VERSION ""

NS_ :

BS_:

BU_: CGM_HS TCM_HS RDCM_HS EPS_HS ECM_HS EBCM_HS BSM_HS BCM_HS

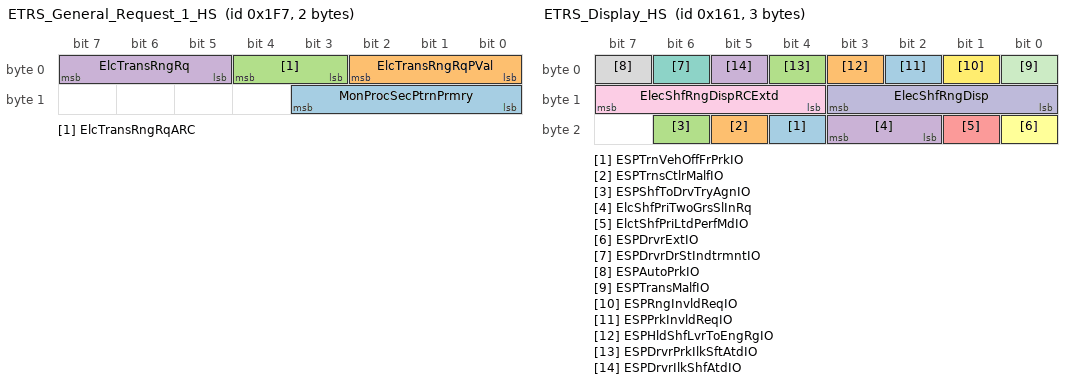
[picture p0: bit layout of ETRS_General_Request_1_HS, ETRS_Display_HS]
BO_ 503 ETRS_General_Request_1_HS: 2 ECM_HS
 SG_ MonProcSecPtrnPrmry : 11|4@0+ (1,0) [0|15] ""  CGM_HS,TCM_HS
 SG_ ElcTransRngRqPVal : 2|3@0+ (1,0) [0|7] ""  CGM_HS,TCM_HS,RDCM_HS
 SG_ ElcTransRngRqARC : 4|2@0+ (1,0) [0|3] ""  CGM_HS,TCM_HS,RDCM_HS
 SG_ ElcTransRngRq : 7|3@0+ (1,0) [0|7] ""  CGM_HS,TCM_HS,RDCM_HS,BCM_HS

BO_ 353 ETRS_Display_HS: 3 ECM_HS
 SG_ ESPTrnVehOffFrPrkIO : 20|1@0+ (1,0) [0|1] ""  CGM_HS,BCM_HS
 SG_ ESPTrnsCtlrMalfIO : 21|1@0+ (1,0) [0|1] ""  CGM_HS,BCM_HS
 SG_ ESPShfToDrvTryAgnIO : 22|1@0+ (1,0) [0|1] ""  CGM_HS,BCM_HS
 SG_ ElcShfPriTwoGrsSlInRq : 19|2@0+ (1,0) [0|3] ""  CGM_HS,BCM_HS
 SG_ ElctShfPriLtdPerfMdIO : 17|1@0+ (1,0) [0|1] ""  CGM_HS,BCM_HS
 SG_ ESPDrvrExtIO : 16|1@0+ (1,0) [0|1] ""  CGM_HS,BCM_HS
 SG_ ESPDrvrDrStIndtrmntIO : 6|1@0+ (1,0) [0|1] ""  CGM_HS,BCM_HS
 SG_ ESPAutoPrkIO : 7|1@0+ (1,0) [0|1] ""  CGM_HS,BCM_HS
 SG_ ElecShfRngDispRCExtd : 15|4@0+ (1,0) [0|15] ""  CGM_HS,BCM_HS
 SG_ ElecShfRngDisp : 11|4@0+ (1,0) [0|15] ""  CGM_HS,BCM_HS
 SG_ ESPTransMalfIO : 0|1@0+ (1,0) [0|1] ""  CGM_HS,BCM_HS
 SG_ ESPRngInvldReqIO : 1|1@0+ (1,0) [0|1] ""  CGM_HS,BCM_HS
 SG_ ESPPrkInvldReqIO : 2|1@0+ (1,0) [0|1] ""  CGM_HS,BCM_HS
 SG_ ESPHldShfLvrToEngRgIO : 3|1@0+ (1,0) [0|1] ""  CGM_HS,BCM_HS
 SG_ ESPDrvrPrkIlkSftAtdIO : 4|1@0+ (1,0) [0|1] ""  CGM_HS,BCM_HS
 SG_ ESPDrvrIlkShfAtdIO : 5|1@0+ (1,0) [0|1] ""  CGM_HS,BCM_HS

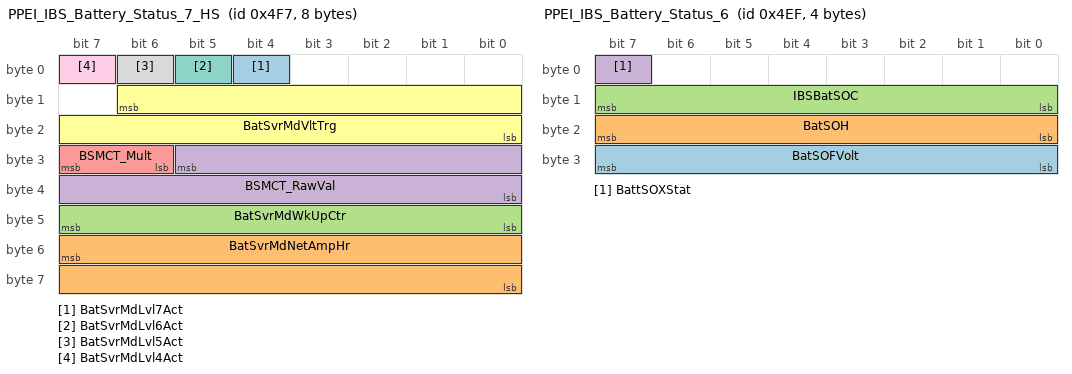
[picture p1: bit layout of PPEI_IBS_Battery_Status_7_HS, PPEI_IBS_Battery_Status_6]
BO_ 1271 PPEI_IBS_Battery_Status_7_HS: 8 ECM_HS
 SG_ BatSvrMdLvl7Act : 4|1@0+ (1,0) [0|1] ""  CGM_HS,BCM_HS
 SG_ BatSvrMdNetAmpHr : 55|16@0+ (0.01,-327.67) [-327.67|327.68] "AmpHours"  CGM_HS,BCM_HS
 SG_ BatSvrMdWkUpCtr : 47|8@0+ (1,0) [0|255] ""  CGM_HS,BCM_HS
 SG_ BSMCT_RawVal : 29|14@0+ (0.001,-8.192) [-8.192|8.191] "A"  CGM_HS,BCM_HS
 SG_ BSMCT_Mult : 31|2@0+ (1,0) [0|3] ""  CGM_HS,BCM_HS
 SG_ BatSvrMdVltTrg : 14|15@0+ (0.001,0) [0|32.767] "V"  CGM_HS,BCM_HS
 SG_ BatSvrMdLvl6Act : 5|1@0+ (1,0) [0|1] ""  CGM_HS,BCM_HS
 SG_ BatSvrMdLvl5Act : 6|1@0+ (1,0) [0|1] ""  CGM_HS,BCM_HS
 SG_ BatSvrMdLvl4Act : 7|1@0+ (1,0) [0|1] ""  CGM_HS,BCM_HS

BO_ 1263 PPEI_IBS_Battery_Status_6: 4 ECM_HS
 SG_ BatSOFVolt : 31|8@0+ (0.05,0) [0|12.75] "volts"  CGM_HS,BCM_HS
 SG_ BatSOH : 23|8@0+ (0.392157,0) [0|100.000035] "%"  CGM_HS,BCM_HS
 SG_ IBSBatSOC : 15|8@0+ (0.392157,0) [0|100.000035] "%"  CGM_HS,BCM_HS
 SG_ BattSOXStat : 7|1@0+ (1,0) [0|1] ""  CGM_HS,BCM_HS

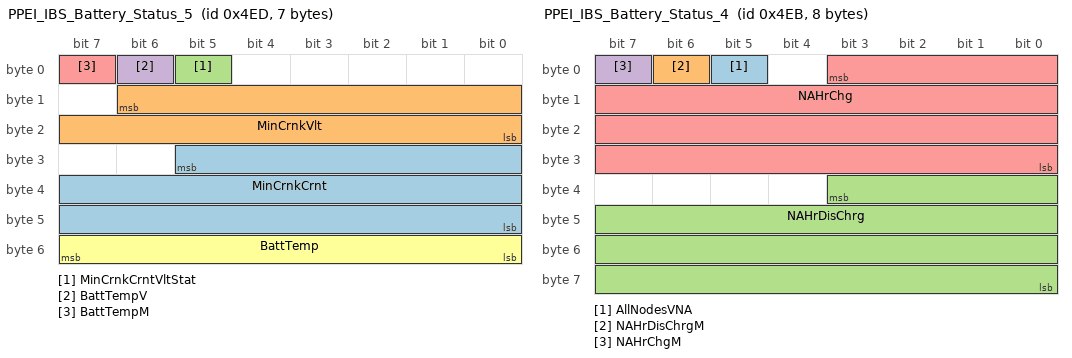
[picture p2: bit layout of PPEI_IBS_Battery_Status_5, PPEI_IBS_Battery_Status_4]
BO_ 1261 PPEI_IBS_Battery_Status_5: 7 ECM_HS
 SG_ MinCrnkCrnt : 29|22@0+ (0.001,-2097.152) [-2097.152|2097.151] "amps"  CGM_HS,BCM_HS
 SG_ MinCrnkVlt : 14|15@0+ (0.001,0) [0|32.767] "volts"  CGM_HS,BCM_HS
 SG_ MinCrnkCrntVltStat : 5|1@0+ (1,0) [0|1] ""  CGM_HS,BCM_HS
 SG_ BattTempV : 6|1@0+ (1,0) [0|1] ""  CGM_HS,BCM_HS
 SG_ BattTempM : 7|1@0+ (1,0) [0|1] ""  CGM_HS,BCM_HS
 SG_ BattTemp : 55|8@0+ (1,-40) [-40|215] "deg C"  CGM_HS,BCM_HS

BO_ 1259 PPEI_IBS_Battery_Status_4: 8 ECM_HS
 SG_ AllNodesVNA : 5|1@0+ (1,0) [0|1] ""  CGM_HS,BCM_HS
 SG_ NAHrDisChrgM : 6|1@0+ (1,0) [0|1] ""  CGM_HS,BCM_HS
 SG_ NAHrDisChrg : 35|28@0+ (0.001,0) [0|268435.455] "AmpHours"  CGM_HS,BCM_HS
 SG_ NAHrChgM : 7|1@0+ (1,0) [0|1] ""  CGM_HS,BCM_HS
 SG_ NAHrChg : 3|28@0+ (0.001,0) [0|268435.455] "AmpHours"  CGM_HS,BCM_HS

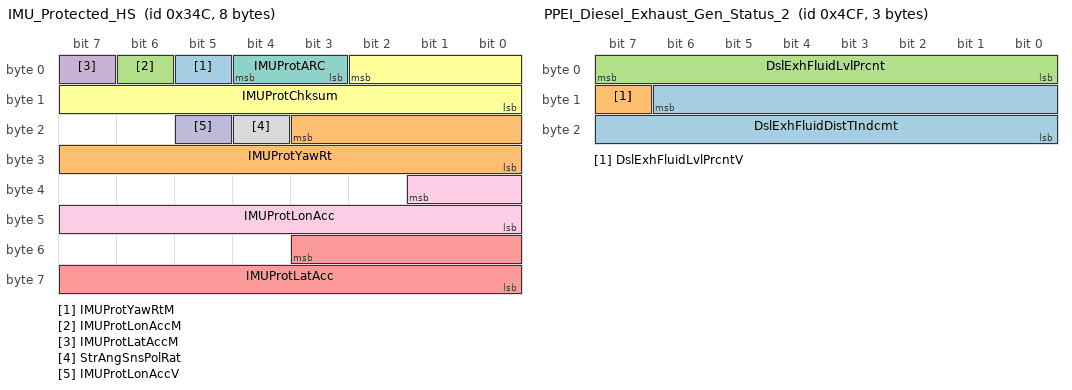
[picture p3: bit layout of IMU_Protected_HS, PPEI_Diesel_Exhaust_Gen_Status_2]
BO_ 844 IMU_Protected_HS: 8 EBCM_HS
 SG_ IMUProtYawRtM : 5|1@0+ (1,0) [0|1] ""  CGM_HS,EPS_HS
 SG_ IMUProtYawRt : 19|12@0- (0.0625,0) [-128|127.9375] "deg/sec"  CGM_HS,EPS_HS
 SG_ IMUProtLonAccM : 6|1@0+ (1,0) [0|1] ""  CGM_HS,EPS_HS
 SG_ IMUProtLatAccM : 7|1@0+ (1,0) [0|1] ""  CGM_HS,EPS_HS
 SG_ IMUProtLatAcc : 51|12@0- (0.015625,0) [-32|31.984375] "m/s^2"  CGM_HS,EPS_HS
 SG_ IMUProtChksum : 2|11@0+ (1,0) [0|2047] ""  CGM_HS,EPS_HS
 SG_ IMUProtARC : 4|2@0+ (1,0) [0|3] ""  CGM_HS,EPS_HS
 SG_ StrAngSnsPolRat : 20|1@0+ (1,0) [0|1] ""  CGM_HS,EPS_HS
 SG_ IMUProtLonAcc : 33|10@0- (0.03,0) [-15.36|15.33] "m/s^2"  CGM_HS,EPS_HS,RDCM_HS,ECM_HS,BCM_HS
 SG_ IMUProtLonAccV : 21|1@0+ (1,0) [0|1] ""  CGM_HS,EPS_HS,RDCM_HS,ECM_HS,BCM_HS

BO_ 806 DC_Converter_Stabilization_HS: 1 ECM_HS
 SG_ DCCnvStblznErrIO : 0|1@0+ (1,0) [0|1] ""  CGM_HS,ECM_HS,BCM_HS

BO_ 1231 PPEI_Diesel_Exhaust_Gen_Status_2: 3 ECM_HS
 SG_ DslExhFluidDistTIndcmt : 14|15@0+ (2,0) [0|65534] "km"  CGM_HS,BCM_HS
 SG_ DslExhFluidLvlPrcntV : 15|1@0+ (1,0) [0|1] ""  CGM_HS,BCM_HS
 SG_ DslExhFluidLvlPrcnt : 7|8@0+ (0.392157,0) [0|100.000035] "%"  CGM_HS,BCM_HS

BO_ 2032 CCP_Command_Receive_Object_HS: 8 CGM_HS
 SG_ DgnInf : 7|64@0+ (1,0) [0|1.84467440737096E+019] ""  BCM_HS

BO_ 563 Performance_Mode_Cust_Setings_HS: 5 EBCM_HS
 SG_ SPMCA_SusPrfMd6Avl : 32|1@0+ (1,0) [0|1] ""  CGM_HS,BCM_HS
 SG_ SPMCA_SusPrfMd5Avl : 33|1@0+ (1,0) [0|1] ""  CGM_HS,BCM_HS
 SG_ SPMCA_SusPrfMd4Avl : 34|1@0+ (1,0) [0|1] ""  CGM_HS,BCM_HS
 SG_ SPMCA_SusPrfMd3Avl : 35|1@0+ (1,0) [0|1] ""  CGM_HS,BCM_HS
 SG_ SPMCA_SusPrfMd2Avl : 36|1@0+ (1,0) [0|1] ""  CGM_HS,BCM_HS
 SG_ SPMCA_SusPrfMd1Avl : 37|1@0+ (1,0) [0|1] ""  CGM_HS,BCM_HS
 SG_ SPMCA_StrPrfMd6Avl : 24|1@0+ (1,0) [0|1] ""  CGM_HS,BCM_HS
 SG_ SPMCA_StrPrfMd5Avl : 25|1@0+ (1,0) [0|1] ""  CGM_HS,BCM_HS
 SG_ SPMCA_StrPrfMd4Avl : 26|1@0+ (1,0) [0|1] ""  CGM_HS,BCM_HS
 SG_ SPMCA_StrPrfMd3Avl : 27|1@0+ (1,0) [0|1] ""  CGM_HS,BCM_HS
 SG_ SPMCA_StrPrfMd2Avl : 28|1@0+ (1,0) [0|1] ""  CGM_HS,BCM_HS
 SG_ SPMCA_StrPrfMd1Avl : 29|1@0+ (1,0) [0|1] ""  CGM_HS,BCM_HS
 SG_ SPMCA_SndPrfMd6Avl : 16|1@0+ (1,0) [0|1] ""  CGM_HS,BCM_HS
 SG_ SPMCA_SndPrfMd5Avl : 17|1@0+ (1,0) [0|1] ""  CGM_HS,BCM_HS
 SG_ SPMCA_SndPrfMd4Avl : 18|1@0+ (1,0) [0|1] ""  CGM_HS,BCM_HS
 SG_ SPMCA_SndPrfMd3Avl : 19|1@0+ (1,0) [0|1] ""  CGM_HS,BCM_HS
 SG_ SPMCA_SndPrfMd2Avl : 20|1@0+ (1,0) [0|1] ""  CGM_HS,BCM_HS
 SG_ SPMCA_SndPrfMd1Avl : 21|1@0+ (1,0) [0|1] ""  CGM_HS,BCM_HS
 SG_ DPMCA_DispPrfMd6Avl : 8|1@0+ (1,0) [0|1] ""  CGM_HS,BCM_HS
 SG_ DPMCA_DispPrfMd5Avl : 9|1@0+ (1,0) [0|1] ""  CGM_HS,BCM_HS
 SG_ DPMCA_DispPrfMd4Avl : 10|1@0+ (1,0) [0|1] ""  CGM_HS,BCM_HS
 SG_ DPMCA_DispPrfMd3Avl : 11|1@0+ (1,0) [0|1] ""  CGM_HS,BCM_HS
 SG_ DPMCA_DispPrfMd2Avl : 12|1@0+ (1,0) [0|1] ""  CGM_HS,BCM_HS
 SG_ DPMCA_DispPrfMd1Avl : 13|1@0+ (1,0) [0|1] ""  CGM_HS,BCM_HS
 SG_ DPMCA_DrvlPrfMd6Avl : 0|1@0+ (1,0) [0|1] ""  CGM_HS,BCM_HS
 SG_ DPMCA_DrvlPrfMd5Avl : 1|1@0+ (1,0) [0|1] ""  CGM_HS,BCM_HS
 SG_ DPMCA_DrvlPrfMd4Avl : 2|1@0+ (1,0) [0|1] ""  CGM_HS,BCM_HS
 SG_ DPMCA_DrvlPrfMd3Avl : 3|1@0+ (1,0) [0|1] ""  CGM_HS,BCM_HS
 SG_ DPMCA_DrvlPrfMd2Avl : 4|1@0+ (1,0) [0|1] ""  CGM_HS,BCM_HS
 SG_ DPMCA_DrvlPrfMd1Avl : 5|1@0+ (1,0) [0|1] ""  CGM_HS,BCM_HS

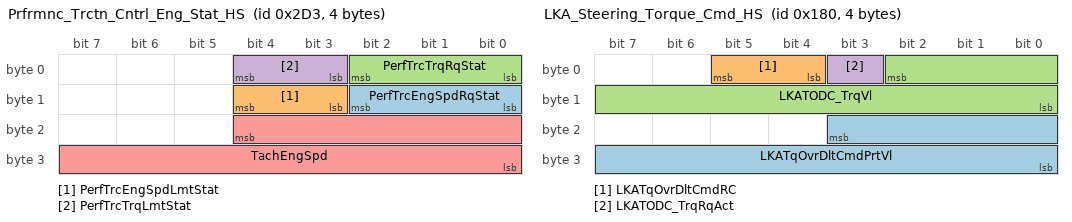
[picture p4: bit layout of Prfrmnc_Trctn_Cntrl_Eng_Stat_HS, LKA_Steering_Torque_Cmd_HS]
BO_ 723 Prfrmnc_Trctn_Cntrl_Eng_Stat_HS: 4 ECM_HS
 SG_ PerfTrcEngSpdRqStat : 10|3@0+ (1,0) [0|7] ""  CGM_HS,EBCM_HS
 SG_ PerfTrcEngSpdLmtStat : 12|2@0+ (1,0) [0|3] ""  CGM_HS,EBCM_HS
 SG_ PerfTrcTrqRqStat : 2|3@0+ (1,0) [0|7] ""  CGM_HS,EBCM_HS
 SG_ PerfTrcTrqLmtStat : 4|2@0+ (1,0) [0|3] ""  CGM_HS,EBCM_HS
 SG_ TachEngSpd : 20|13@0+ (1,0) [0|8191] "rpm"  CGM_HS,BCM_HS

BO_ 419 PTEI_Engine_Common_Use_1: 1 ECM_HS
 SG_ ClrCGMLgsDgInf : 6|1@0+ (1,0) [0|1] ""  CGM_HS
 SG_ EngRunng : 7|1@0+ (1,0) [0|1] ""  CGM_HS,TCM_HS,EBCM_HS,BCM_HS

BO_ 1268 PPEI_Engine_General_Status_9: 2 ECM_HS
 SG_ EngAirFltLfRmn : 14|7@0+ (1,0) [0|127] "%"  CGM_HS,BCM_HS
 SG_ EngAirFltMonSt : 2|3@0+ (1,0) [0|7] ""  CGM_HS,BCM_HS

BO_ 384 LKA_Steering_Torque_Cmd_HS: 4 CGM_HS
 SG_ LKATqOvrDltCmdPrtVl : 19|12@0+ (1,0) [0|4095] ""  EPS_HS
 SG_ LKATqOvrDltCmdRC : 5|2@0+ (1,0) [0|3] ""  EPS_HS
 SG_ LKATODC_TrqVl : 2|11@0- (0.01,0) [-10.24|10.23] "Nm"  EPS_HS,BCM_HS
 SG_ LKATODC_TrqRqAct : 3|1@0+ (1,0) [0|1] ""  EPS_HS,BCM_HS

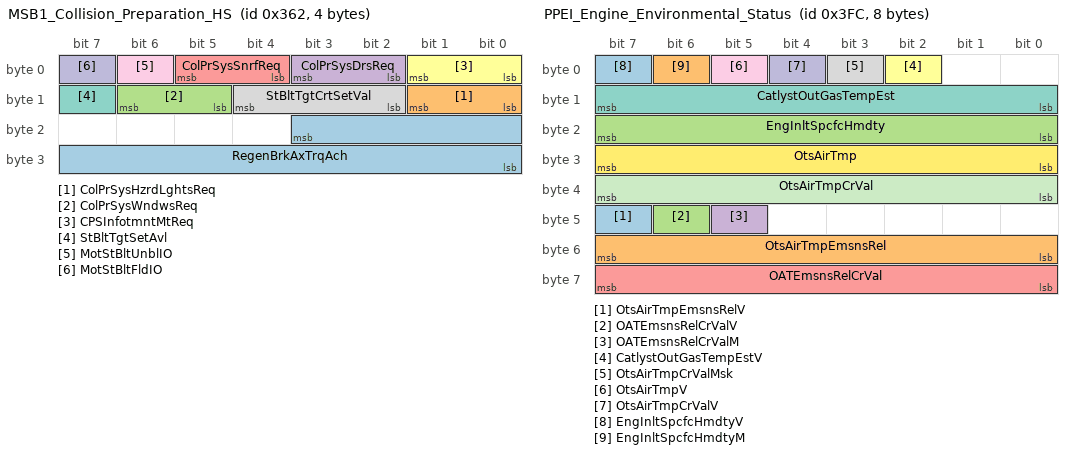
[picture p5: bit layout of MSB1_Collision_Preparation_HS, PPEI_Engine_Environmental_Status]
BO_ 866 MSB1_Collision_Preparation_HS: 4 EBCM_HS
 SG_ RegenBrkAxTrqAch : 19|12@0+ (2,0) [0|8190] "Nm"  CGM_HS,BSM_HS
 SG_ ColPrSysHzrdLghtsReq : 9|2@0+ (1,0) [0|3] ""  CGM_HS,BCM_HS
 SG_ ColPrSysWndwsReq : 14|2@0+ (1,0) [0|3] ""  CGM_HS,BCM_HS
 SG_ ColPrSysDrsReq : 3|2@0+ (1,0) [0|3] ""  CGM_HS,BCM_HS
 SG_ ColPrSysSnrfReq : 5|2@0+ (1,0) [0|3] ""  CGM_HS,BCM_HS
 SG_ CPSInfotmntMtReq : 1|2@0+ (1,0) [0|3] ""  CGM_HS,BCM_HS
 SG_ StBltTgtSetAvl : 15|1@0+ (1,0) [0|1] ""  CGM_HS,BCM_HS
 SG_ StBltTgtCrtSetVal : 12|3@0+ (1,0) [0|7] ""  CGM_HS,BCM_HS
 SG_ MotStBltUnblIO : 6|1@0+ (1,0) [0|1] ""  CGM_HS,BCM_HS
 SG_ MotStBltFldIO : 7|1@0+ (1,0) [0|1] ""  CGM_HS,BCM_HS

BO_ 479 PPEI_Propulsion_Gen_Stat_1_HS: 3 ECM_HS
 SG_ PTAVHEnbld : 4|1@0+ (1,0) [0|1] ""  CGM_HS,EBCM_HS
 SG_ PTAVHActv : 3|1@0+ (1,0) [0|1] ""  CGM_HS,EBCM_HS
 SG_ PrplsnSysAtv : 7|1@0+ (1,0) [0|1] ""  CGM_HS,TCM_HS,RDCM_HS,ECM_HS,EBCM_HS,BSM_HS
 SG_ EngAutoStpNotProb : 2|1@0+ (1,0) [0|1] ""  CGM_HS,TCM_HS,ECM_HS,BCM_HS
 SG_ EASSI_UnsdRsrvd2 : 8|1@0+ (1,0) [0|1] ""  CGM_HS,TCM_HS,EBCM_HS,ECM_HS,BCM_HS
 SG_ EASSI_StlDetd : 10|1@0+ (1,0) [0|1] ""  CGM_HS,TCM_HS,EBCM_HS,ECM_HS,BCM_HS
 SG_ EASSI_TrqDetd : 11|1@0+ (1,0) [0|1] ""  CGM_HS,TCM_HS,EBCM_HS,ECM_HS,BCM_HS
 SG_ EASSI_FuelReqOn : 12|1@0+ (1,0) [0|1] ""  CGM_HS,TCM_HS,EBCM_HS,ECM_HS,BCM_HS
 SG_ EASSI_StrtTyp : 15|3@0+ (1,0) [0|7] ""  CGM_HS,TCM_HS,EBCM_HS,ECM_HS,BCM_HS
 SG_ EASSI_StrtStpSt : 1|2@0+ (1,0) [0|3] ""  CGM_HS,TCM_HS,ECM_HS,EBCM_HS,BCM_HS
 SG_ EASSI_TorqDetdIndet : 9|1@0+ (1,0) [0|1] ""  CGM_HS,TCM_HS,ECM_HS,EBCM_HS,BCM_HS
 SG_ ASIRI_Indication08 : 16|1@0+ (1,0) [0|1] ""  CGM_HS,BCM_HS
 SG_ ASIRI_Indication07 : 17|1@0+ (1,0) [0|1] ""  CGM_HS,BCM_HS
 SG_ ASIRI_Indication06 : 18|1@0+ (1,0) [0|1] ""  CGM_HS,BCM_HS
 SG_ ASIRI_Indication05 : 19|1@0+ (1,0) [0|1] ""  CGM_HS,BCM_HS
 SG_ ASIRI_Indication04 : 20|1@0+ (1,0) [0|1] ""  CGM_HS,BCM_HS
 SG_ ASIRI_Indication03 : 21|1@0+ (1,0) [0|1] ""  CGM_HS,BCM_HS
 SG_ ASIRI_Indication02 : 22|1@0+ (1,0) [0|1] ""  CGM_HS,BCM_HS
 SG_ ASIRI_Indication01 : 23|1@0+ (1,0) [0|1] ""  CGM_HS,BCM_HS
 SG_ PTWrmgWtToShftIO : 5|1@0+ (1,0) [0|1] ""  CGM_HS,BCM_HS
 SG_ PTShftLvrLckRqd : 6|1@0+ (1,0) [0|1] ""  CGM_HS,BCM_HS

BO_ 1020 PPEI_Engine_Environmental_Status: 8 ECM_HS
 SG_ OtsAirTmpEmsnsRelV : 47|1@0+ (1,0) [0|1] ""  CGM_HS,BSM_HS
 SG_ OtsAirTmpEmsnsRel : 55|8@0+ (0.5,-40) [-40|87.5] "deg C"  CGM_HS,BSM_HS
 SG_ OATEmsnsRelCrValV : 46|1@0+ (1,0) [0|1] ""  CGM_HS,BSM_HS
 SG_ OATEmsnsRelCrValM : 45|1@0+ (1,0) [0|1] ""  CGM_HS,BSM_HS
 SG_ OATEmsnsRelCrVal : 63|8@0+ (0.5,-40) [-40|87.5] "deg C"  CGM_HS,BSM_HS
 SG_ CatlystOutGasTempEstV : 2|1@0+ (1,0) [0|1] ""  CGM_HS,BSM_HS
 SG_ CatlystOutGasTempEst : 15|8@0+ (5,-40) [-40|1235] "deg C"  CGM_HS,BSM_HS
 SG_ OtsAirTmpCrValMsk : 3|1@0+ (1,0) [0|1] ""  TCM_HS,BSM_HS,BCM_HS
 SG_ OtsAirTmpV : 5|1@0+ (1,0) [0|1] ""  CGM_HS,BSM_HS,BCM_HS
 SG_ OtsAirTmpCrValV : 4|1@0+ (1,0) [0|1] ""  TCM_HS,BSM_HS,BCM_HS
 SG_ OtsAirTmpCrVal : 39|8@0+ (0.5,-40) [-40|87.5] "deg C"  TCM_HS,BSM_HS,BCM_HS
 SG_ OtsAirTmp : 31|8@0+ (0.5,-40) [-40|87.5] "deg C"  CGM_HS,BSM_HS,BCM_HS
 SG_ EngInltSpcfcHmdtyV : 7|1@0+ (1,0) [0|1] ""  CGM_HS,EBCM_HS,BSM_HS,BCM_HS
 SG_ EngInltSpcfcHmdtyM : 6|1@0+ (1,0) [0|1] ""  CGM_HS,EBCM_HS,BSM_HS,BCM_HS
 SG_ EngInltSpcfcHmdty : 23|8@0+ (0.0196078,0) [0|4.999989] "% water"  CGM_HS,EBCM_HS,BSM_HS,BCM_HS

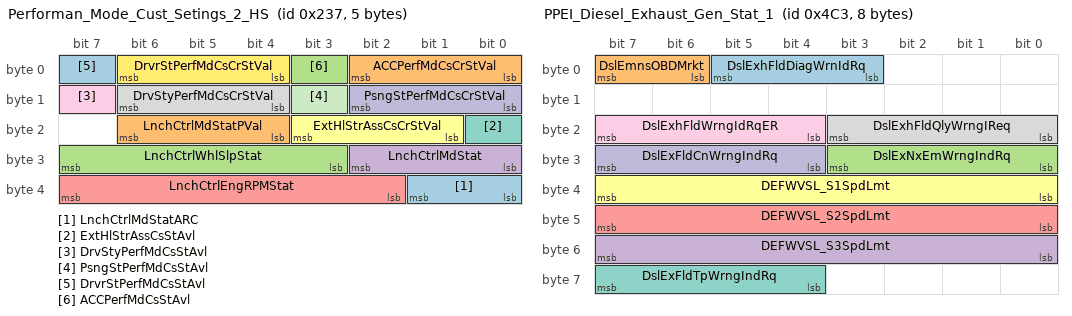
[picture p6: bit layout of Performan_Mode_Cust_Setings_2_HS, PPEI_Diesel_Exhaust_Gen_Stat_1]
BO_ 567 Performan_Mode_Cust_Setings_2_HS: 5 EBCM_HS
 SG_ LnchCtrlMdStatARC : 33|2@0+ (1,0) [0|3] ""  CGM_HS,ECM_HS
 SG_ LnchCtrlMdStatPVal : 22|3@0+ (1,0) [0|7] ""  CGM_HS,ECM_HS
 SG_ LnchCtrlWhlSlpStat : 31|5@0+ (1,0) [0|31] ""  CGM_HS,BCM_HS
 SG_ LnchCtrlMdStat : 26|3@0+ (1,0) [0|7] ""  CGM_HS,ECM_HS,BCM_HS
 SG_ LnchCtrlEngRPMStat : 39|6@0+ (1,0) [0|63] ""  CGM_HS,BCM_HS
 SG_ ExtHlStrAssCsCrStVal : 19|3@0+ (1,0) [0|7] ""  CGM_HS,BCM_HS
 SG_ ExtHlStrAssCsStAvl : 16|1@0+ (1,0) [0|1] ""  CGM_HS,BCM_HS
 SG_ DrvStyPerfMdCsCrStVal : 14|3@0+ (1,0) [0|7] ""  CGM_HS,BCM_HS
 SG_ DrvStyPerfMdCsStAvl : 15|1@0+ (1,0) [0|1] ""  CGM_HS,BCM_HS
 SG_ PsngStPerfMdCsCrStVal : 10|3@0+ (1,0) [0|7] ""  CGM_HS,BCM_HS
 SG_ PsngStPerfMdCsStAvl : 11|1@0+ (1,0) [0|1] ""  CGM_HS,BCM_HS
 SG_ DrvrStPerfMdCsCrStVal : 6|3@0+ (1,0) [0|7] ""  CGM_HS,BCM_HS
 SG_ DrvrStPerfMdCsStAvl : 7|1@0+ (1,0) [0|1] ""  CGM_HS,BCM_HS
 SG_ ACCPerfMdCsCrStVal : 2|3@0+ (1,0) [0|7] ""  CGM_HS,BCM_HS
 SG_ ACCPerfMdCsStAvl : 3|1@0+ (1,0) [0|1] ""  CGM_HS,BCM_HS

BO_ 1219 PPEI_Diesel_Exhaust_Gen_Stat_1: 8 ECM_HS
 SG_ DslExhFldDiagWrnIdRq : 5|3@0+ (1,0) [0|7] ""  CGM_HS,BCM_HS
 SG_ DslEmnsOBDMrkt : 7|2@0+ (1,0) [0|3] ""  CGM_HS,BCM_HS
 SG_ DslExNxEmWrngIndRq : 27|4@0+ (1,0) [0|15] ""  CGM_HS,BCM_HS
 SG_ DEFWVSL_S3SpdLmt : 55|8@0+ (1,0) [0|255] "km / h"  CGM_HS,BCM_HS
 SG_ DEFWVSL_S2SpdLmt : 47|8@0+ (1,0) [0|255] "km / h"  CGM_HS,BCM_HS
 SG_ DEFWVSL_S1SpdLmt : 39|8@0+ (1,0) [0|255] "km / h"  CGM_HS,BCM_HS
 SG_ DslExFldTpWrngIndRq : 63|4@0+ (1,0) [0|15] ""  CGM_HS,BCM_HS
 SG_ DslExhFldQlyWrngIReq : 19|4@0+ (1,0) [0|15] ""  CGM_HS,BCM_HS
 SG_ DslExhFldWrngIdRqER : 23|4@0+ (1,0) [0|15] ""  CGM_HS,BCM_HS
 SG_ DslExFldCnWrngIndRq : 31|4@0+ (1,0) [0|15] ""  CGM_HS,BCM_HS

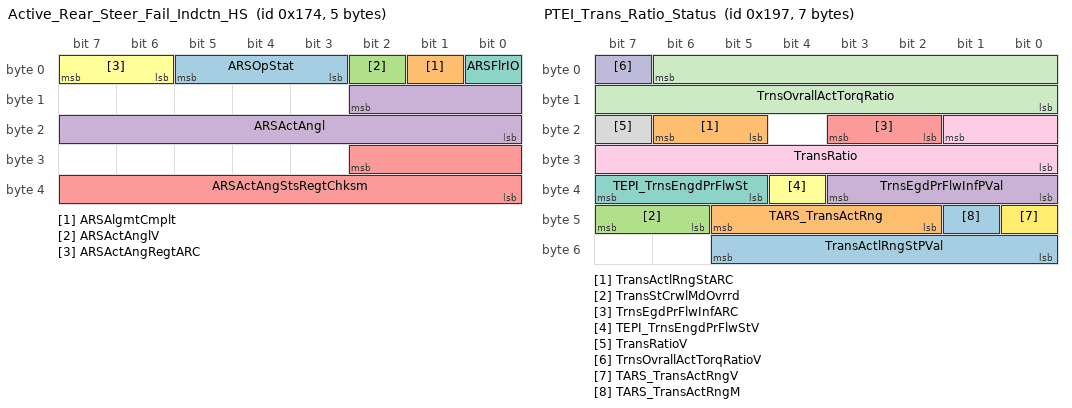
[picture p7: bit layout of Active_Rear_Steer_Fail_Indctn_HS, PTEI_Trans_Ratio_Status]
BO_ 372 Active_Rear_Steer_Fail_Indctn_HS: 5 EBCM_HS
 SG_ ARSOpStat : 5|3@0+ (1,0) [0|7] ""  CGM_HS
 SG_ ARSAlgmtCmplt : 1|1@0+ (1,0) [0|1] ""  CGM_HS
 SG_ ARSActAnglV : 2|1@0+ (1,0) [0|1] ""  CGM_HS
 SG_ ARSActAngl : 10|11@0- (0.01,0) [-10.24|10.23] "deg"  CGM_HS
 SG_ ARSActAngStsRegtChksm : 26|11@0+ (1,0) [0|2047] ""  CGM_HS
 SG_ ARSActAngRegtARC : 7|2@0+ (1,0) [0|3] ""  CGM_HS
 SG_ ARSFlrIO : 0|1@0+ (1,0) [0|1] ""  CGM_HS,BCM_HS

BO_ 565 Performan_Mode_Cust_Setings_1_HS: 5 EBCM_HS
 SG_ PerfMdMainMenuType : 2|3@0+ (1,0) [0|7] ""  CGM_HS,BCM_HS
 SG_ PSPMCA_PsngStPrfMd6Avl : 24|1@0+ (1,0) [0|1] ""  CGM_HS,BCM_HS
 SG_ PSPMCA_PsngStPrfMd5Avl : 25|1@0+ (1,0) [0|1] ""  CGM_HS,BCM_HS
 SG_ PSPMCA_PsngStPrfMd4Avl : 26|1@0+ (1,0) [0|1] ""  CGM_HS,BCM_HS
 SG_ PSPMCA_PsngStPrfMd3Avl : 27|1@0+ (1,0) [0|1] ""  CGM_HS,BCM_HS
 SG_ PSPMCA_PsngStPrfMd2Avl : 28|1@0+ (1,0) [0|1] ""  CGM_HS,BCM_HS
 SG_ PSPMCA_PsngStPrfMd1Avl : 29|1@0+ (1,0) [0|1] ""  CGM_HS,BCM_HS
 SG_ DSPMCA_DrvStyPrfMd7Avl : 32|1@0+ (1,0) [0|1] ""  CGM_HS,BCM_HS
 SG_ DSPMCA_DrvStyPrfMd6Avl : 33|1@0+ (1,0) [0|1] ""  CGM_HS,BCM_HS
 SG_ DSPMCA_DrvStyPrfMd5Avl : 34|1@0+ (1,0) [0|1] ""  CGM_HS,BCM_HS
 SG_ DSPMCA_DrvStyPrfMd4Avl : 35|1@0+ (1,0) [0|1] ""  CGM_HS,BCM_HS
 SG_ DSPMCA_DrvStyPrfMd3Avl : 36|1@0+ (1,0) [0|1] ""  CGM_HS,BCM_HS
 SG_ DSPMCA_DrvStyPrfMd2Avl : 37|1@0+ (1,0) [0|1] ""  CGM_HS,BCM_HS
 SG_ DSPMCA_DrvStyPrfMd1Avl : 38|1@0+ (1,0) [0|1] ""  CGM_HS,BCM_HS
 SG_ DSPMCA_DrvrStPrfMd6Avl : 16|1@0+ (1,0) [0|1] ""  CGM_HS,BCM_HS
 SG_ DSPMCA_DrvrStPrfMd5Avl : 17|1@0+ (1,0) [0|1] ""  CGM_HS,BCM_HS
 SG_ DSPMCA_DrvrStPrfMd4Avl : 18|1@0+ (1,0) [0|1] ""  CGM_HS,BCM_HS
 SG_ DSPMCA_DrvrStPrfMd3Avl : 19|1@0+ (1,0) [0|1] ""  CGM_HS,BCM_HS
 SG_ DSPMCA_DrvrStPrfMd2Avl : 20|1@0+ (1,0) [0|1] ""  CGM_HS,BCM_HS
 SG_ DSPMCA_DrvrStPrfMd1Avl : 21|1@0+ (1,0) [0|1] ""  CGM_HS,BCM_HS
 SG_ ACCPMCA_ACCPrfMd6Avl : 8|1@0+ (1,0) [0|1] ""  CGM_HS,BCM_HS
 SG_ ACCPMCA_ACCPrfMd5Avl : 9|1@0+ (1,0) [0|1] ""  CGM_HS,BCM_HS
 SG_ ACCPMCA_ACCPrfMd4Avl : 10|1@0+ (1,0) [0|1] ""  CGM_HS,BCM_HS
 SG_ ACCPMCA_ACCPrfMd3Avl : 11|1@0+ (1,0) [0|1] ""  CGM_HS,BCM_HS
 SG_ ACCPMCA_ACCPrfMd2Avl : 12|1@0+ (1,0) [0|1] ""  CGM_HS,BCM_HS
 SG_ ACCPMCA_ACCPrfMd1Avl : 13|1@0+ (1,0) [0|1] ""  CGM_HS,BCM_HS

BO_ 500 PPEI_Drv_Pref_Mode_Switch_Status: 6 ECM_HS
 SG_ AutoVehMdSelctIntrStat : 46|2@0+ (1,0) [0|3] ""  CGM_HS
 SG_ EnhDrvMdSwChUseAct : 40|1@0+ (1,0) [0|1] ""  CGM_HS,EBCM_HS
 SG_ EnhDrvSelMdSwStat : 42|2@0+ (1,0) [0|3] ""  CGM_HS,EBCM_HS
 SG_ DrvSelMd8Stat : 17|1@0+ (1,0) [0|1] ""  CGM_HS,RDCM_HS,EBCM_HS,BCM_HS
 SG_ DrvSelMd8ReqDnd : 16|1@0+ (1,0) [0|1] ""  CGM_HS,RDCM_HS,BCM_HS
 SG_ DrvSelMd7Stat : 19|1@0+ (1,0) [0|1] ""  CGM_HS,RDCM_HS,EBCM_HS,BCM_HS
 SG_ DrvSelMd7ReqDnd : 18|1@0+ (1,0) [0|1] ""  CGM_HS,RDCM_HS,BCM_HS
 SG_ DrvSelMd6Stat : 21|1@0+ (1,0) [0|1] ""  CGM_HS,RDCM_HS,EBCM_HS,BCM_HS
 SG_ DrvSelMd6ReqDnd : 20|1@0+ (1,0) [0|1] ""  CGM_HS,RDCM_HS,BCM_HS
 SG_ DrvSelMd5Stat : 23|1@0+ (1,0) [0|1] ""  CGM_HS,RDCM_HS,EBCM_HS,BCM_HS
 SG_ DrvSelMd5ReqDnd : 22|1@0+ (1,0) [0|1] ""  CGM_HS,RDCM_HS,BCM_HS
 SG_ DrvSelMd4Stat : 9|1@0+ (1,0) [0|1] ""  CGM_HS,RDCM_HS,EBCM_HS,BCM_HS
 SG_ DrvSelMd4ReqDnd : 8|1@0+ (1,0) [0|1] ""  CGM_HS,RDCM_HS,BCM_HS
 SG_ DrvSelMd3Stat : 11|1@0+ (1,0) [0|1] ""  CGM_HS,RDCM_HS,EBCM_HS,BCM_HS
 SG_ DrvSelMd3ReqDnd : 10|1@0+ (1,0) [0|1] ""  CGM_HS,RDCM_HS,EBCM_HS,BCM_HS
 SG_ DrvSelMd2Stat : 13|1@0+ (1,0) [0|1] ""  CGM_HS,RDCM_HS,EBCM_HS,BCM_HS
 SG_ DrvSelMd2ReqDnd : 12|1@0+ (1,0) [0|1] ""  CGM_HS,RDCM_HS,BCM_HS
 SG_ DSMSS_DrvSelMd0Pn : 47|1@0+ (1,0) [0|1] ""  CGM_HS,RDCM_HS,EBCM_HS,BCM_HS
 SG_ DSMSS_DrvSelMd8Pn : 32|1@0+ (1,0) [0|1] ""  CGM_HS,RDCM_HS,EBCM_HS,BCM_HS
 SG_ DSMSS_DrvSelMd7Pn : 33|1@0+ (1,0) [0|1] ""  CGM_HS,RDCM_HS,EBCM_HS,BCM_HS
 SG_ DSMSS_DrvSelMd6Pn : 34|1@0+ (1,0) [0|1] ""  CGM_HS,RDCM_HS,EBCM_HS,BCM_HS
 SG_ DSMSS_DrvSelMd5Pn : 35|1@0+ (1,0) [0|1] ""  CGM_HS,RDCM_HS,EBCM_HS,BCM_HS
 SG_ DSMSS_DrvSelMd4Pn : 36|1@0+ (1,0) [0|1] ""  CGM_HS,RDCM_HS,EBCM_HS,BCM_HS
 SG_ DSMSS_DrvSelMd3Pn : 37|1@0+ (1,0) [0|1] ""  CGM_HS,RDCM_HS,EBCM_HS,BCM_HS
 SG_ DSMSS_DrvSelMd2Pn : 38|1@0+ (1,0) [0|1] ""  CGM_HS,RDCM_HS,EBCM_HS,BCM_HS
 SG_ DSMSS_DrvSelMd1Pn : 39|1@0+ (1,0) [0|1] ""  CGM_HS,RDCM_HS,EBCM_HS,BCM_HS
 SG_ DSMSS_DrvSelMd8Un : 24|1@0+ (1,0) [0|1] ""  CGM_HS,RDCM_HS,EBCM_HS,BCM_HS
 SG_ DSMSS_DrvSelMd7Un : 25|1@0+ (1,0) [0|1] ""  CGM_HS,RDCM_HS,EBCM_HS,BCM_HS
 SG_ DSMSS_DrvSelMd6Un : 26|1@0+ (1,0) [0|1] ""  CGM_HS,RDCM_HS,EBCM_HS,BCM_HS
 SG_ DSMSS_DrvSelMd5Un : 27|1@0+ (1,0) [0|1] ""  CGM_HS,RDCM_HS,EBCM_HS,BCM_HS
 SG_ DSMSS_DrvSelMd4Un : 28|1@0+ (1,0) [0|1] ""  CGM_HS,RDCM_HS,EBCM_HS,BCM_HS
 SG_ DSMSS_DrvSelMd3Un : 29|1@0+ (1,0) [0|1] ""  CGM_HS,RDCM_HS,EBCM_HS,BCM_HS
 SG_ DSMSS_DrvSelMd2Un : 30|1@0+ (1,0) [0|1] ""  CGM_HS,RDCM_HS,EBCM_HS,BCM_HS
 SG_ DSMSS_DrvSelMd1Un : 31|1@0+ (1,0) [0|1] ""  CGM_HS,RDCM_HS,EBCM_HS,BCM_HS
 SG_ DrvSelMd1ReqDnd : 14|1@0+ (1,0) [0|1] ""  CGM_HS,RDCM_HS,BCM_HS
 SG_ DrvSelMd1Stat : 15|1@0+ (1,0) [0|1] ""  CGM_HS,RDCM_HS,EBCM_HS,BCM_HS

BO_ 407 PTEI_Trans_Ratio_Status: 7 TCM_HS
 SG_ TransActlRngStPVal : 53|6@0+ (1,0) [0|63] ""  CGM_HS,ECM_HS,BSM_HS
 SG_ TransActlRngStARC : 22|2@0+ (1,0) [0|3] ""  CGM_HS,ECM_HS,BSM_HS
 SG_ TransStCrwlMdOvrrd : 47|2@0+ (1,0) [0|3] ""  CGM_HS,ECM_HS
 SG_ TrnsEgdPrFlwInfPVal : 35|4@0+ (1,0) [0|15] ""  CGM_HS,ECM_HS
 SG_ TrnsEgdPrFlwInfARC : 19|2@0+ (1,0) [0|3] ""  CGM_HS,ECM_HS
 SG_ TEPI_TrnsEngdPrFlwStV : 36|1@0+ (1,0) [0|1] ""  CGM_HS,ECM_HS
 SG_ TEPI_TrnsEngdPrFlwSt : 39|3@0+ (1,0) [0|7] ""  CGM_HS,ECM_HS
 SG_ TransRatioV : 23|1@0+ (1,0) [0|1] ""  CGM_HS,ECM_HS
 SG_ TransRatio : 17|10@0+ (0.03125,0) [0|31.96875] ""  CGM_HS,ECM_HS
 SG_ TrnsOvrallActTorqRatioV : 7|1@0+ (1,0) [0|1] ""  CGM_HS,ECM_HS
 SG_ TrnsOvrallActTorqRatio : 6|15@0- (0.00390625,0) [-64|63.99609375] ""  CGM_HS,ECM_HS
 SG_ TARS_TransActRngV : 40|1@0+ (1,0) [0|1] ""  CGM_HS,ECM_HS,BSM_HS,BCM_HS
 SG_ TARS_TransActRngM : 41|1@0+ (1,0) [0|1] ""  CGM_HS,ECM_HS,BSM_HS,BCM_HS
 SG_ TARS_TransActRng : 45|4@0+ (1,0) [0|15] ""  CGM_HS,ECM_HS,BSM_HS,BCM_HS

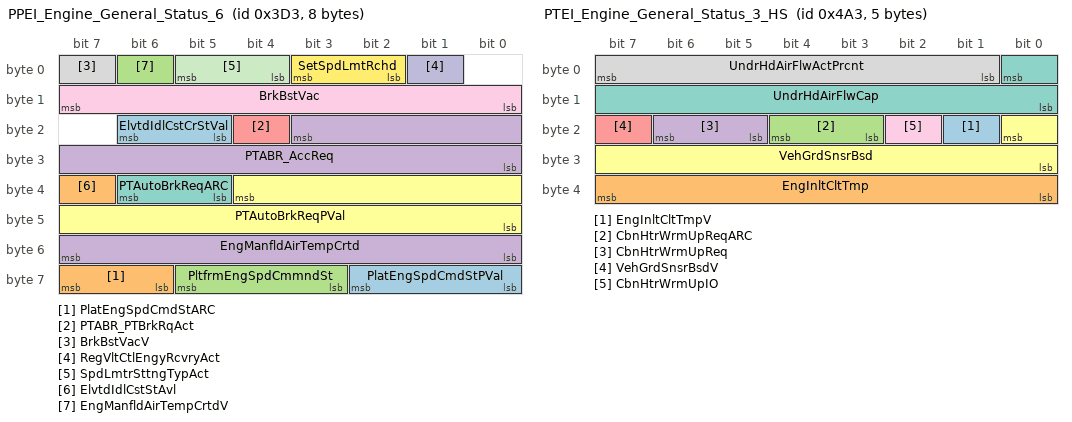
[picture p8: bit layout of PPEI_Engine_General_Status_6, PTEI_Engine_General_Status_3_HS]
BO_ 979 PPEI_Engine_General_Status_6: 8 ECM_HS
 SG_ PlatEngSpdCmdStPVal : 58|3@0+ (1,0) [0|7] ""  CGM_HS
 SG_ PlatEngSpdCmdStARC : 63|2@0+ (1,0) [0|3] ""  CGM_HS
 SG_ PltfrmEngSpdCmmndSt : 61|3@0+ (1,0) [0|7] ""  CGM_HS
 SG_ PTABR_AccReq : 19|12@0- (0.01,0) [-20.48|20.47] "m/s^2"  CGM_HS,EBCM_HS
 SG_ PTABR_PTBrkRqAct : 20|1@0+ (1,0) [0|1] ""  CGM_HS,EBCM_HS
 SG_ PTAutoBrkReqPVal : 36|13@0+ (1,0) [0|8191] ""  CGM_HS,EBCM_HS
 SG_ PTAutoBrkReqARC : 38|2@0+ (1,0) [0|3] ""  CGM_HS,EBCM_HS
 SG_ BrkBstVacV : 7|1@0+ (1,0) [0|1] ""  CGM_HS,EBCM_HS
 SG_ BrkBstVac : 15|8@0+ (0.5,0) [0|127.5] "kPa"  CGM_HS,EBCM_HS
 SG_ RegVltCtlEngyRcvryAct : 1|1@0+ (1,0) [0|1] ""  CGM_HS,BCM_HS
 SG_ SpdLmtrSttngTypAct : 5|2@0+ (1,0) [0|3] ""  CGM_HS,BCM_HS
 SG_ SetSpdLmtRchd : 3|2@0+ (1,0) [0|3] ""  CGM_HS,BCM_HS
 SG_ ElvtdIdlCstCrStVal : 22|2@0+ (1,0) [0|3] ""  CGM_HS,BCM_HS
 SG_ ElvtdIdlCstStAvl : 39|1@0+ (1,0) [0|1] ""  CGM_HS,BCM_HS
 SG_ EngManfldAirTempCrtdV : 6|1@0+ (1,0) [0|1] ""  CGM_HS,BCM_HS
 SG_ EngManfldAirTempCrtd : 55|8@0+ (1,-40) [-40|215] "deg C"  CGM_HS,BCM_HS

BO_ 368 Environment_Id_Resp_5_HS: 3 CGM_HS
 SG_ EnvIdRspSt5 : 17|2@0+ (1,0) [0|3] ""  BCM_HS
 SG_ EnvIdRsp5 : 7|16@0+ (1,0) [0|65535] ""  BCM_HS

BO_ 1187 PTEI_Engine_General_Status_3_HS: 5 ECM_HS
 SG_ EngInltCltTmpV : 17|1@0+ (1,0) [0|1] ""  TCM_HS,CGM_HS
 SG_ EngInltCltTmp : 39|8@0+ (1,-40) [-40|215] "deg C"  TCM_HS,CGM_HS
 SG_ CbnHtrWrmUpReqARC : 20|2@0+ (1,0) [0|3] ""  TCM_HS,CGM_HS
 SG_ CbnHtrWrmUpReq : 22|2@0+ (1,0) [0|3] ""  TCM_HS,CGM_HS
 SG_ VehGrdSnsrBsdV : 23|1@0+ (1,0) [0|1] ""  TCM_HS,CGM_HS
 SG_ VehGrdSnsrBsd : 16|9@0- (0.1945,0) [-49.792|49.5975] "%"  TCM_HS,CGM_HS
 SG_ UndrHdAirFlwCap : 0|9@0+ (2,0) [0|1022] "m^3/min"  TCM_HS,CGM_HS,BSM_HS
 SG_ UndrHdAirFlwActPrcnt : 7|7@0+ (0.787402,0) [0|100.000054] "%"  TCM_HS,CGM_HS,BSM_HS
 SG_ CbnHtrWrmUpIO : 18|1@0+ (1,0) [0|1] ""  CGM_HS,BCM_HS

BO_ 566 VICM_Status_HS: 7 BSM_HS
 SG_ RdDCChrgCntctrStat : 49|2@0+ (1,0) [0|3] ""  CGM_HS
 SG_ RdHVBatHtrCntctrStat : 51|2@0+ (1,0) [0|3] ""  CGM_HS
 SG_ RHVBCCS_InvtrCaptrChrgAct : 52|1@0+ (1,0) [0|1] ""  CGM_HS
 SG_ RHVBCCS_DCChrgrCntCmd : 53|1@0+ (1,0) [0|1] ""  CGM_HS
 SG_ RHVBCCS_InvtrCntCmd : 54|1@0+ (1,0) [0|1] ""  CGM_HS
 SG_ RHVBCCS_ACChrgrCntCmd : 55|1@0+ (1,0) [0|1] ""  CGM_HS
 SG_ RdHVCntctrShdwnCmd : 47|3@0+ (1,0) [0|7] ""  CGM_HS
 SG_ ChrgSysShftPrkReqPval : 44|2@0+ (1,0) [0|3] ""  ECM_HS,CGM_HS
 SG_ ChrgSysShftPrkReqARC : 42|2@0+ (1,0) [0|3] ""  ECM_HS,CGM_HS
 SG_ ChrgSysShftPrkReq : 40|1@0+ (1,0) [0|1] ""  ECM_HS,CGM_HS
 SG_ HVBatChrgCrdAlrtReq : 7|2@0+ (1,0) [0|3] ""  CGM_HS
 SG_ RdHVBatLwParMdReq : 32|1@0+ (1,0) [0|1] ""  CGM_HS
 SG_ RdHVBtClOVFFTstRq : 31|1@0+ (1,0) [0|1] ""  CGM_HS
 SG_ RdHVBtClOVFFTstIdx : 30|7@0+ (1,0) [0|127] ""  CGM_HS
 SG_ ClimCtrlHVDvcShtdwnCmd : 23|1@0+ (1,0) [0|1] ""  CGM_HS
 SG_ ThrmlRefCompSpdReqARC : 36|2@0+ (1,0) [0|3] " "  CGM_HS
 SG_ VICMHVEnMgCmEnTrS : 22|1@0+ (1,0) [0|1] ""  CGM_HS
 SG_ ChrgSysPrkBrkAnmsBrkReqPVal : 20|2@0+ (1,0) [0|3] ""  EBCM_HS,CGM_HS
 SG_ ChrgSysPrkBrkAnmsBrkReqARC : 18|2@0+ (1,0) [0|3] ""  EBCM_HS,CGM_HS
 SG_ ChrgSysPrkBrkAnmsBrkReq : 16|1@0+ (1,0) [0|1] ""  EBCM_HS,CGM_HS
 SG_ HybVehHiVltSysDisbld_236 : 21|1@0+ (1,0) [0|1] ""  CGM_HS
 SG_ ThrmlRefCompSpdReq : 5|14@0+ (1,0) [0|16383] "rpm"  CGM_HS
 SG_ ChrgSysAudblIndRq : 39|3@0+ (1,0) [0|7] ""  CGM_HS,BCM_HS

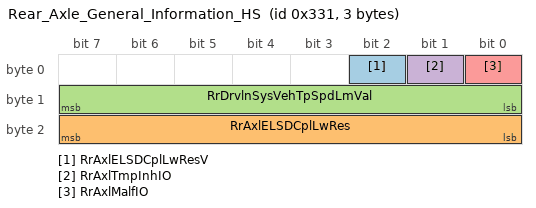
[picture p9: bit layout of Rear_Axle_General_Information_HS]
BO_ 817 Rear_Axle_General_Information_HS: 3 RDCM_HS
 SG_ RrAxlELSDCplLwResV : 2|1@0+ (1,0) [0|1] ""  CGM_HS,BCM_HS
 SG_ RrAxlELSDCplLwRes : 23|8@0+ (10,0) [0|2550] "Nm"  CGM_HS,BCM_HS
 SG_ RrDrvlnSysVehTpSpdLmVal : 15|8@0+ (2,0) [0|510] "km/h"  CGM_HS,BCM_HS
 SG_ RrAxlTmpInhIO : 1|1@0+ (1,0) [0|1] ""  CGM_HS,BCM_HS
 SG_ RrAxlMalfIO : 0|1@0+ (1,0) [0|1] ""  CGM_HS,EBCM_HS,BCM_HS

CM_ SG_ 1263 BatSOH "State of Health = the aging state of the Battery";
CM_ SG_ 979 BrkBstVac "0 kPA represents the sensor reading atmospheric pressure";
BA_DEF_ SG_  "GenSigSendOnInit" ENUM  "Not Initialized","Application","Handler","DLCLS","DLCHS","DLCCE","DLCFO";
BA_DEF_ SG_  "GenSigSendType" ENUM  "not used","not used","not used","not used","not used","not used","not used","NoSigSendType","not used","not used","OnAnyChange","OnChangeIfActive","OnDelta","DLCLS","DLCHS","DLCCE","DLCFO";
BA_DEF_ SG_  "GenSigDeltaValue" INT 0 0;
BA_DEF_ SG_  "VNSigAllNodes" ENUM  "No","Yes","DLCLS","DLCHS","DLCCE","DLCFO";
BA_DEF_ SG_  "VNSigSLHSSharedDiagnostic" ENUM  "No","Yes","DLCLS","DLCHS","DLCCE","DLCFO";
BA_DEF_ SG_  "VNSigSLHS_VNReq" ENUM  "No","Yes","DLCLS","DLCHS","DLCCE","DLCFO";
BA_DEF_ SG_  "SignalType" STRING ;
BA_DEF_ SG_  "PacketOrder" INT 0 65535;
BA_DEF_ SG_  "SignalLongName" STRING ;
BA_DEF_ SG_  "GenSigStartValue" INT 0 65535;
BA_DEF_ SG_  "TxSignalSendOnInit" ENUM  "Not Initialized","Application","Handler";
BA_DEF_ BO_  "GenMsgILSupport" ENUM  "No","Yes","DLCLS","DLCHS","DLCCE","DLCFO";
BA_DEF_ BO_  "AppGenMsgCycleTime" INT 0 0;
BA_DEF_ BO_  "TpApplType" STRING ;
BA_DEF_ BO_  "Prio" INT 0 7;
BA_DEF_ BO_  "MessageSubnet" ENUM  "LS","MS","HS","CE","PE","HV","FO","S1","HE","LE","HE2","DLCLS","DLCHS","DLCCE","DLCFO","vector_leerstring";
BA_DEF_ BO_  "DiagState" ENUM  "No","Yes";
BA_DEF_ BO_  "GenMsgIlSupport" ENUM  "No","Yes";
BA_DEF_ BO_  "GenMsgStartDelayTime" INT 0 100000;
BA_DEF_ BO_  "GenMsgDelayTime" INT 0 100000;
BA_DEF_ BO_  "GenMsgCycleTime" INT 0 100000;
BA_DEF_ BO_  "GenMsgSendType" ENUM  "cyclicX","spontanX","cyclicIfActiveX","spontanWithDelay","cyclicAndSpontanX","cyclicAndSpontanWithDelay","spontanWithRepitition","cyclicIfActiveAndSpontanWD";
BA_DEF_ BO_  "DiagResponse" ENUM  "No","Yes";
BA_DEF_ BO_  "DiagRequest" ENUM  "No","Yes";
BA_DEF_ BO_  "NmMessage" ENUM  "No","Yes";
BA_DEF_REL_ BU_SG_REL_  "GenSigSuprvResp" ENUM  "None","Notify App","Substitute Default","DLCLS","DLCHS","DLCCE","DLCFO";
BA_DEF_REL_ BU_SG_REL_  "GenSigSuprvRespSubValue" INT 0 65535;
BA_DEF_REL_ BU_SG_REL_  "GenSigRxStartValue" STRING ;
BA_DEF_REL_ BU_SG_REL_  "GenSigVDAFailResp" ENUM  "No","Yes","DLCLS","DLCHS","DLCCE","DLCFO";
BA_DEF_REL_ BU_SG_REL_  "GenSigVDAFailComment" STRING ;
BA_DEF_REL_ BU_SG_REL_  "GenSigVBitRespComment" STRING ;
BA_DEF_REL_ BU_SG_REL_  "GenSigVBitResp" ENUM  "No","Yes","DLCLS","DLCHS","DLCCE","DLCFO";
BA_DEF_REL_ BU_SG_REL_  "GenSigSuprvRespComment" STRING ;
BA_DEF_REL_ BU_SG_REL_  "GenSigTimeoutMsg" HEX 0 268435455;
BA_DEF_REL_ BU_SG_REL_  "GenSigTimeoutTime" INT 0 5000;
BA_DEF_DEF_  "GenSigSendOnInit" "Not Initialized";
BA_DEF_DEF_  "GenSigSendType" "NoSigSendType";
BA_DEF_DEF_  "GenSigDeltaValue" 0;
BA_DEF_DEF_  "VNSigAllNodes" "No";
BA_DEF_DEF_  "VNSigSLHSSharedDiagnostic" "No";
BA_DEF_DEF_  "VNSigSLHS_VNReq" "No";
BA_DEF_DEF_  "SignalType" "";
BA_DEF_DEF_  "PacketOrder" 0;
BA_DEF_DEF_  "SignalLongName" "";
BA_DEF_DEF_  "GenSigStartValue" 0;
BA_DEF_DEF_  "TxSignalSendOnInit" "Not Initialized";
BA_DEF_DEF_  "GenMsgILSupport" "Yes";
BA_DEF_DEF_  "AppGenMsgCycleTime" 0;
BA_DEF_DEF_  "TpApplType" "";
BA_DEF_DEF_  "Prio" 0;
BA_DEF_DEF_  "MessageSubnet" "LS";
BA_DEF_DEF_  "DiagState" "No";
BA_DEF_DEF_  "GenMsgIlSupport" "Yes";
BA_DEF_DEF_  "GenMsgStartDelayTime" 0;
BA_DEF_DEF_  "GenMsgDelayTime" 0;
BA_DEF_DEF_  "GenMsgCycleTime" 0;
BA_DEF_DEF_  "GenMsgSendType" "spontanX";
BA_DEF_DEF_  "DiagResponse" "No";
BA_DEF_DEF_  "DiagRequest" "No";
BA_DEF_DEF_  "NmMessage" "No";
BA_DEF_DEF_REL_ "GenSigSuprvResp" "None";
BA_DEF_DEF_REL_ "GenSigSuprvRespSubValue" 0;
BA_DEF_DEF_REL_ "GenSigRxStartValue" "";
BA_DEF_DEF_REL_ "GenSigVDAFailResp" "No";
BA_DEF_DEF_REL_ "GenSigVDAFailComment" "";
BA_DEF_DEF_REL_ "GenSigVBitRespComment" "";
BA_DEF_DEF_REL_ "GenSigVBitResp" "No";
BA_DEF_DEF_REL_ "GenSigSuprvRespComment" "";
BA_DEF_DEF_REL_ "GenSigTimeoutMsg" 0;
BA_DEF_DEF_REL_ "GenSigTimeoutTime" 0;
BA_ "GenMsgSendType" BO_ 503 0;
BA_ "GenMsgCycleTime" BO_ 503 25;
BA_ "MessageSubnet" BO_ 503 2;
BA_ "GenMsgSendType" BO_ 353 0;
BA_ "GenMsgCycleTime" BO_ 353 100;
BA_ "MessageSubnet" BO_ 353 2;
BA_ "GenMsgSendType" BO_ 1271 0;
BA_ "GenMsgCycleTime" BO_ 1271 5000;
BA_ "MessageSubnet" BO_ 1271 2;
BA_ "GenMsgSendType" BO_ 1263 0;
BA_ "GenMsgCycleTime" BO_ 1263 1000;
BA_ "MessageSubnet" BO_ 1263 2;
BA_ "GenMsgSendType" BO_ 1261 0;
BA_ "GenMsgCycleTime" BO_ 1261 1000;
BA_ "MessageSubnet" BO_ 1261 2;
BA_ "GenMsgSendType" BO_ 1259 0;
BA_ "GenMsgCycleTime" BO_ 1259 500;
BA_ "MessageSubnet" BO_ 1259 2;
BA_ "GenMsgSendType" BO_ 844 0;
BA_ "GenMsgCycleTime" BO_ 844 50;
BA_ "MessageSubnet" BO_ 844 2;
BA_ "GenMsgSendType" BO_ 806 0;
BA_ "GenMsgCycleTime" BO_ 806 500;
BA_ "MessageSubnet" BO_ 806 2;
BA_ "GenMsgSendType" BO_ 1231 0;
BA_ "GenMsgCycleTime" BO_ 1231 1000;
BA_ "MessageSubnet" BO_ 1231 2;
BA_ "DiagRequest" BO_ 2032 1;
BA_ "MessageSubnet" BO_ 2032 2;
BA_ "GenMsgSendType" BO_ 563 0;
BA_ "GenMsgCycleTime" BO_ 563 2000;
BA_ "MessageSubnet" BO_ 563 2;
BA_ "GenMsgSendType" BO_ 723 0;
BA_ "GenMsgCycleTime" BO_ 723 50;
BA_ "MessageSubnet" BO_ 723 2;
BA_ "GenMsgSendType" BO_ 419 0;
BA_ "GenMsgCycleTime" BO_ 419 25;
BA_ "MessageSubnet" BO_ 419 2;
BA_ "GenMsgSendType" BO_ 1268 0;
BA_ "GenMsgCycleTime" BO_ 1268 1000;
BA_ "MessageSubnet" BO_ 1268 2;
BA_ "GenMsgSendType" BO_ 384 0;
BA_ "GenMsgCycleTime" BO_ 384 100;
BA_ "GenMsgDelayTime" BO_ 384 10;
BA_ "MessageSubnet" BO_ 384 2;
BA_ "GenMsgSendType" BO_ 866 0;
BA_ "GenMsgCycleTime" BO_ 866 50;
BA_ "MessageSubnet" BO_ 866 2;
BA_ "GenMsgSendType" BO_ 479 0;
BA_ "GenMsgCycleTime" BO_ 479 25;
BA_ "MessageSubnet" BO_ 479 2;
BA_ "GenMsgSendType" BO_ 1020 0;
BA_ "GenMsgCycleTime" BO_ 1020 250;
BA_ "MessageSubnet" BO_ 1020 2;
BA_ "GenMsgSendType" BO_ 567 0;
BA_ "GenMsgCycleTime" BO_ 567 250;
BA_ "MessageSubnet" BO_ 567 2;
BA_ "GenMsgSendType" BO_ 1219 0;
BA_ "GenMsgCycleTime" BO_ 1219 1000;
BA_ "MessageSubnet" BO_ 1219 2;
BA_ "GenMsgSendType" BO_ 372 0;
BA_ "GenMsgCycleTime" BO_ 372 100;
BA_ "MessageSubnet" BO_ 372 2;
BA_ "GenMsgSendType" BO_ 565 0;
BA_ "GenMsgCycleTime" BO_ 565 2000;
BA_ "MessageSubnet" BO_ 565 2;
BA_ "GenMsgSendType" BO_ 500 0;
BA_ "GenMsgCycleTime" BO_ 500 25;
BA_ "MessageSubnet" BO_ 500 2;
BA_ "GenMsgSendType" BO_ 407 0;
BA_ "GenMsgCycleTime" BO_ 407 25;
BA_ "MessageSubnet" BO_ 407 2;
BA_ "GenMsgSendType" BO_ 979 0;
BA_ "GenMsgCycleTime" BO_ 979 100;
BA_ "MessageSubnet" BO_ 979 2;
BA_ "GenMsgSendType" BO_ 368 0;
BA_ "GenMsgCycleTime" BO_ 368 100;
BA_ "MessageSubnet" BO_ 368 2;
BA_ "GenMsgSendType" BO_ 1187 0;
BA_ "GenMsgCycleTime" BO_ 1187 1000;
BA_ "MessageSubnet" BO_ 1187 2;
BA_ "GenMsgSendType" BO_ 566 0;
BA_ "GenMsgCycleTime" BO_ 566 100;
BA_ "MessageSubnet" BO_ 566 2;
BA_ "GenMsgSendType" BO_ 817 0;
BA_ "GenMsgCycleTime" BO_ 817 100;
BA_ "MessageSubnet" BO_ 817 2;
BA_ "SignalLongName" SG_ 503 MonProcSecPtrnPrmry "Monitor Processor Security Pattern Primary";
BA_ "SignalType" SG_ 503 MonProcSecPtrnPrmry "UNM";
BA_ "VNSigAllNodes" SG_ 503 MonProcSecPtrnPrmry 1;
BA_ "SignalLongName" SG_ 503 ElcTransRngRqPVal "Electronic Transmission Range Request Protection Value";
BA_ "SignalType" SG_ 503 ElcTransRngRqPVal "UNM";
BA_ "VNSigAllNodes" SG_ 503 ElcTransRngRqPVal 1;
BA_ "SignalLongName" SG_ 503 ElcTransRngRqARC "Electronic Transmission Range Request Alive Rolling Count";
BA_ "SignalType" SG_ 503 ElcTransRngRqARC "UNM";
BA_ "VNSigAllNodes" SG_ 503 ElcTransRngRqARC 1;
BA_ "SignalLongName" SG_ 503 ElcTransRngRq "Electronic Transmission Range Request";
BA_ "SignalType" SG_ 503 ElcTransRngRq "ENM";
BA_ "VNSigAllNodes" SG_ 503 ElcTransRngRq 1;
BA_ "SignalLongName" SG_ 353 ESPTrnVehOffFrPrkIO "Electronic Shift Primary Turn Vehicle Off For Park Indication On";
BA_ "SignalType" SG_ 353 ESPTrnVehOffFrPrkIO "BLN";
BA_ "VNSigAllNodes" SG_ 353 ESPTrnVehOffFrPrkIO 1;
BA_ "SignalLongName" SG_ 353 ESPTrnsCtlrMalfIO "Electronic Shift Primary Transmission Controller Malfunction Indication On";
BA_ "SignalType" SG_ 353 ESPTrnsCtlrMalfIO "BLN";
BA_ "VNSigAllNodes" SG_ 353 ESPTrnsCtlrMalfIO 1;
BA_ "SignalLongName" SG_ 353 ESPShfToDrvTryAgnIO "Electronic Shift Primary Shift To Drive Try Again Indication On";
BA_ "SignalType" SG_ 353 ESPShfToDrvTryAgnIO "BLN";
BA_ "VNSigAllNodes" SG_ 353 ESPShfToDrvTryAgnIO 1;
BA_ "SignalLongName" SG_ 353 ElcShfPriTwoGrsSlInRq "Electronic Shift Primary Two Gears Selected Indication Request";
BA_ "SignalType" SG_ 353 ElcShfPriTwoGrsSlInRq "ENM";
BA_ "VNSigAllNodes" SG_ 353 ElcShfPriTwoGrsSlInRq 1;
BA_ "SignalLongName" SG_ 353 ElctShfPriLtdPerfMdIO "Electronic Shift Primary Limited Performance Mode Indication On";
BA_ "SignalType" SG_ 353 ElctShfPriLtdPerfMdIO "BLN";
BA_ "VNSigAllNodes" SG_ 353 ElctShfPriLtdPerfMdIO 1;
BA_ "GenSigSendType" SG_ 353 ElctShfPriLtdPerfMdIO 10;
BA_ "SignalLongName" SG_ 353 ESPDrvrExtIO "Electronic Shift Primary Driver Exit Indication On";
BA_ "SignalType" SG_ 353 ESPDrvrExtIO "BLN";
BA_ "VNSigAllNodes" SG_ 353 ESPDrvrExtIO 1;
BA_ "GenSigSendType" SG_ 353 ESPDrvrExtIO 10;
BA_ "SignalLongName" SG_ 353 ESPDrvrDrStIndtrmntIO "Electronic Shift Primary Driver Door State Indeterminate Indication On";
BA_ "SignalType" SG_ 353 ESPDrvrDrStIndtrmntIO "BLN";
BA_ "VNSigAllNodes" SG_ 353 ESPDrvrDrStIndtrmntIO 1;
BA_ "GenSigSendType" SG_ 353 ESPDrvrDrStIndtrmntIO 10;
BA_ "SignalLongName" SG_ 353 ESPAutoPrkIO "Electronic Shift Primary Auto Park Indication On";
BA_ "SignalType" SG_ 353 ESPAutoPrkIO "BLN";
BA_ "VNSigAllNodes" SG_ 353 ESPAutoPrkIO 1;
BA_ "GenSigSendType" SG_ 353 ESPAutoPrkIO 10;
BA_ "SignalLongName" SG_ 353 ElecShfRngDispRCExtd "Electronic Shift Range Display Rolling Count Extended";
BA_ "SignalType" SG_ 353 ElecShfRngDispRCExtd "UNM";
BA_ "VNSigAllNodes" SG_ 353 ElecShfRngDispRCExtd 1;
BA_ "SignalLongName" SG_ 353 ElecShfRngDisp "Electronic Shift Range Display";
BA_ "SignalType" SG_ 353 ElecShfRngDisp "ENM";
BA_ "VNSigAllNodes" SG_ 353 ElecShfRngDisp 1;
BA_ "SignalLongName" SG_ 353 ESPTransMalfIO "Electronic Shift Primary Transmission Malfunction Indication On";
BA_ "SignalType" SG_ 353 ESPTransMalfIO "BLN";
BA_ "VNSigAllNodes" SG_ 353 ESPTransMalfIO 1;
BA_ "SignalLongName" SG_ 353 ESPRngInvldReqIO "Electronic Shift Primary Range Invalid Request Indication On";
BA_ "SignalType" SG_ 353 ESPRngInvldReqIO "BLN";
BA_ "VNSigAllNodes" SG_ 353 ESPRngInvldReqIO 1;
BA_ "SignalLongName" SG_ 353 ESPPrkInvldReqIO "Electronic Shift Primary Park Invalid Request Indication On";
BA_ "SignalType" SG_ 353 ESPPrkInvldReqIO "BLN";
BA_ "VNSigAllNodes" SG_ 353 ESPPrkInvldReqIO 1;
BA_ "SignalLongName" SG_ 353 ESPHldShfLvrToEngRgIO "Electronic Shift Primary Hold Shift Lever to Engage Range Indication On";
BA_ "SignalType" SG_ 353 ESPHldShfLvrToEngRgIO "BLN";
BA_ "VNSigAllNodes" SG_ 353 ESPHldShfLvrToEngRgIO 1;
BA_ "SignalLongName" SG_ 353 ESPDrvrPrkIlkSftAtdIO "Electronic Shift Primary Driver Park Interlock Shift Attempted Indication On";
BA_ "SignalType" SG_ 353 ESPDrvrPrkIlkSftAtdIO "BLN";
BA_ "VNSigAllNodes" SG_ 353 ESPDrvrPrkIlkSftAtdIO 1;
BA_ "SignalLongName" SG_ 353 ESPDrvrIlkShfAtdIO "Electronic Shift Primary Driver Interlock Shift Attempted Indication On";
BA_ "SignalType" SG_ 353 ESPDrvrIlkShfAtdIO "BLN";
BA_ "VNSigAllNodes" SG_ 353 ESPDrvrIlkShfAtdIO 1;
BA_ "SignalLongName" SG_ 1271 BatSvrMdLvl7Act "Battery Saver Mode Level 7 Active";
BA_ "SignalType" SG_ 1271 BatSvrMdLvl7Act "BLN";
BA_ "VNSigAllNodes" SG_ 1271 BatSvrMdLvl7Act 1;
BA_ "SignalLongName" SG_ 1271 BatSvrMdNetAmpHr "Battery Saver Mode Net Amp Hour";
BA_ "SignalType" SG_ 1271 BatSvrMdNetAmpHr "UNM";
BA_ "VNSigAllNodes" SG_ 1271 BatSvrMdNetAmpHr 1;
BA_ "SignalLongName" SG_ 1271 BatSvrMdWkUpCtr "Battery Saver Mode Wake Up Counter";
BA_ "SignalType" SG_ 1271 BatSvrMdWkUpCtr "UNM";
BA_ "VNSigAllNodes" SG_ 1271 BatSvrMdWkUpCtr 1;
BA_ "SignalLongName" SG_ 1271 BSMCT_RawVal "Battery Saver Mode Current Trigger : Raw Value";
BA_ "PacketOrder" SG_ 1271 BSMCT_RawVal 2;
BA_ "SignalType" SG_ 1271 BSMCT_RawVal "UNM";
BA_ "VNSigAllNodes" SG_ 1271 BSMCT_RawVal 1;
BA_ "SignalLongName" SG_ 1271 BSMCT_Mult "Battery Saver Mode Current Trigger : Multiplier";
BA_ "PacketOrder" SG_ 1271 BSMCT_Mult 1;
BA_ "SignalType" SG_ 1271 BSMCT_Mult "ENM";
BA_ "VNSigAllNodes" SG_ 1271 BSMCT_Mult 1;
BA_ "SignalLongName" SG_ 1271 BatSvrMdVltTrg "Battery Saver Mode Voltage Trigger";
BA_ "SignalType" SG_ 1271 BatSvrMdVltTrg "UNM";
BA_ "VNSigAllNodes" SG_ 1271 BatSvrMdVltTrg 1;
BA_ "SignalLongName" SG_ 1271 BatSvrMdLvl6Act "Battery Saver Mode Level 6 Active";
BA_ "SignalType" SG_ 1271 BatSvrMdLvl6Act "BLN";
BA_ "VNSigAllNodes" SG_ 1271 BatSvrMdLvl6Act 1;
BA_ "SignalLongName" SG_ 1271 BatSvrMdLvl5Act "Battery Saver Mode Level 5 Active";
BA_ "SignalType" SG_ 1271 BatSvrMdLvl5Act "BLN";
BA_ "VNSigAllNodes" SG_ 1271 BatSvrMdLvl5Act 1;
BA_ "SignalLongName" SG_ 1271 BatSvrMdLvl4Act "Battery Saver Mode Level 4 Active";
BA_ "SignalType" SG_ 1271 BatSvrMdLvl4Act "BLN";
BA_ "VNSigAllNodes" SG_ 1271 BatSvrMdLvl4Act 1;
BA_ "GenSigStartValue" SG_ 1263 BatSOFVolt 200;
BA_ "SignalLongName" SG_ 1263 BatSOFVolt "Battery State Of Function Voltage";
BA_ "SignalType" SG_ 1263 BatSOFVolt "UNM";
BA_ "VNSigAllNodes" SG_ 1263 BatSOFVolt 1;
BA_ "GenSigStartValue" SG_ 1263 BatSOH 203.999928600025;
BA_ "SignalLongName" SG_ 1263 BatSOH "Battery State Of Health";
BA_ "SignalType" SG_ 1263 BatSOH "UNM";
BA_ "VNSigAllNodes" SG_ 1263 BatSOH 1;
BA_ "GenSigStartValue" SG_ 1263 IBSBatSOC 196;
BA_ "SignalLongName" SG_ 1263 IBSBatSOC "Intelligent Battery Sensor Battery State of Charge";
BA_ "SignalType" SG_ 1263 IBSBatSOC "UNM";
BA_ "VNSigAllNodes" SG_ 1263 IBSBatSOC 1;
BA_ "SignalLongName" SG_ 1263 BattSOXStat "Battery SOX Status";
BA_ "SignalType" SG_ 1263 BattSOXStat "ENM";
BA_ "VNSigAllNodes" SG_ 1263 BattSOXStat 1;
BA_ "SignalLongName" SG_ 1261 MinCrnkCrnt "Minimum Cranking Current";
BA_ "SignalType" SG_ 1261 MinCrnkCrnt "UNM";
BA_ "VNSigAllNodes" SG_ 1261 MinCrnkCrnt 1;
BA_ "SignalLongName" SG_ 1261 MinCrnkVlt "Minimum Cranking Voltage";
BA_ "SignalType" SG_ 1261 MinCrnkVlt "UNM";
BA_ "VNSigAllNodes" SG_ 1261 MinCrnkVlt 1;
BA_ "SignalLongName" SG_ 1261 MinCrnkCrntVltStat "Minimum Cranking Voltage and Current Status";
BA_ "SignalType" SG_ 1261 MinCrnkCrntVltStat "ENM";
BA_ "VNSigAllNodes" SG_ 1261 MinCrnkCrntVltStat 1;
BA_ "SignalLongName" SG_ 1261 BattTempV "Battery Temperature Validity";
BA_ "SignalType" SG_ 1261 BattTempV "ENM";
BA_ "VNSigAllNodes" SG_ 1261 BattTempV 1;
BA_ "SignalLongName" SG_ 1261 BattTempM "Battery Temperature Mask";
BA_ "SignalType" SG_ 1261 BattTempM "ENM";
BA_ "VNSigAllNodes" SG_ 1261 BattTempM 1;
BA_ "GenSigStartValue" SG_ 1261 BattTemp 65;
BA_ "SignalLongName" SG_ 1261 BattTemp "Battery Temperature";
BA_ "SignalType" SG_ 1261 BattTemp "UNM";
BA_ "VNSigAllNodes" SG_ 1261 BattTemp 1;
BA_ "SignalLongName" SG_ 1259 AllNodesVNA "All Nodes Virtual Network Activation";
BA_ "SignalType" SG_ 1259 AllNodesVNA "ENM";
BA_ "VNSigSLHS_VNReq" SG_ 1259 AllNodesVNA 1;
BA_ "VNSigAllNodes" SG_ 1259 AllNodesVNA 1;
BA_ "SignalLongName" SG_ 1259 NAHrDisChrgM "Net Amp Hours Discharge Mask";
BA_ "SignalType" SG_ 1259 NAHrDisChrgM "ENM";
BA_ "VNSigAllNodes" SG_ 1259 NAHrDisChrgM 1;
BA_ "SignalLongName" SG_ 1259 NAHrDisChrg "Net Amp Hours Discharge";
BA_ "SignalType" SG_ 1259 NAHrDisChrg "UNM";
BA_ "VNSigAllNodes" SG_ 1259 NAHrDisChrg 1;
BA_ "SignalLongName" SG_ 1259 NAHrChgM "Net Amp Hours Charge Mask";
BA_ "SignalType" SG_ 1259 NAHrChgM "ENM";
BA_ "VNSigAllNodes" SG_ 1259 NAHrChgM 1;
BA_ "SignalLongName" SG_ 1259 NAHrChg "Net Amp Hours Charge";
BA_ "SignalType" SG_ 1259 NAHrChg "UNM";
BA_ "VNSigAllNodes" SG_ 1259 NAHrChg 1;
BA_ "SignalLongName" SG_ 844 IMUProtYawRtM "Inertial Measurement Unit Protected Yaw Rate Mask";
BA_ "SignalType" SG_ 844 IMUProtYawRtM "ENM";
BA_ "VNSigAllNodes" SG_ 844 IMUProtYawRtM 1;
BA_ "SignalLongName" SG_ 844 IMUProtYawRt "Inertial Measurement Unit Protected Yaw Rate";
BA_ "SignalType" SG_ 844 IMUProtYawRt "SNM";
BA_ "VNSigAllNodes" SG_ 844 IMUProtYawRt 1;
BA_ "SignalLongName" SG_ 844 IMUProtLonAccM "Inertial Measurement Unit Protected Longitudinal Acceleration Mask";
BA_ "SignalType" SG_ 844 IMUProtLonAccM "ENM";
BA_ "VNSigAllNodes" SG_ 844 IMUProtLonAccM 1;
BA_ "SignalLongName" SG_ 844 IMUProtLatAccM "Inertial Measurement Unit Protected Lateral Acceleration Mask";
BA_ "SignalType" SG_ 844 IMUProtLatAccM "ENM";
BA_ "VNSigAllNodes" SG_ 844 IMUProtLatAccM 1;
BA_ "SignalLongName" SG_ 844 IMUProtLatAcc "Inertial Measurement Unit Protected Lateral Acceleration";
BA_ "SignalType" SG_ 844 IMUProtLatAcc "SNM";
BA_ "VNSigAllNodes" SG_ 844 IMUProtLatAcc 1;
BA_ "SignalLongName" SG_ 844 IMUProtChksum "Inertial Measurement Unit Protected Checksum";
BA_ "SignalType" SG_ 844 IMUProtChksum "UNM";
BA_ "VNSigAllNodes" SG_ 844 IMUProtChksum 1;
BA_ "SignalLongName" SG_ 844 IMUProtARC "Inertial Measurement Unit Protected Alive Rolling Count";
BA_ "SignalType" SG_ 844 IMUProtARC "UNM";
BA_ "VNSigAllNodes" SG_ 844 IMUProtARC 1;
BA_ "SignalLongName" SG_ 844 StrAngSnsPolRat "Steering Angle Sensor Polarity Rationality";
BA_ "SignalType" SG_ 844 StrAngSnsPolRat "ENM";
BA_ "VNSigAllNodes" SG_ 844 StrAngSnsPolRat 1;
BA_ "SignalLongName" SG_ 844 IMUProtLonAcc "Inertial Measurement Unit Protected Longitudinal Acceleration";
BA_ "SignalType" SG_ 844 IMUProtLonAcc "SNM";
BA_ "VNSigAllNodes" SG_ 844 IMUProtLonAcc 1;
BA_ "SignalLongName" SG_ 844 IMUProtLonAccV "Inertial Measurement Unit Protected Longitudinal Acceleration Validity";
BA_ "SignalType" SG_ 844 IMUProtLonAccV "ENM";
BA_ "VNSigAllNodes" SG_ 844 IMUProtLonAccV 1;
BA_ "SignalLongName" SG_ 806 DCCnvStblznErrIO "DC Converter Stabilization Error Indication On";
BA_ "SignalType" SG_ 806 DCCnvStblznErrIO "BLN";
BA_ "VNSigAllNodes" SG_ 806 DCCnvStblznErrIO 1;
BA_ "SignalLongName" SG_ 1231 DslExhFluidDistTIndcmt "Diesel Exhaust Fluid Distance to Inducement";
BA_ "SignalType" SG_ 1231 DslExhFluidDistTIndcmt "UNM";
BA_ "VNSigAllNodes" SG_ 1231 DslExhFluidDistTIndcmt 1;
BA_ "SignalLongName" SG_ 1231 DslExhFluidLvlPrcntV "Diesel Exhaust Fluid Level Percent Validity";
BA_ "SignalType" SG_ 1231 DslExhFluidLvlPrcntV "ENM";
BA_ "VNSigAllNodes" SG_ 1231 DslExhFluidLvlPrcntV 1;
BA_ "SignalLongName" SG_ 1231 DslExhFluidLvlPrcnt "Diesel Exhaust Fluid Level Percent";
BA_ "SignalType" SG_ 1231 DslExhFluidLvlPrcnt "UNM";
BA_ "VNSigAllNodes" SG_ 1231 DslExhFluidLvlPrcnt 1;
BA_ "SignalLongName" SG_ 2032 DgnInf "Diagnostic Information";
BA_ "SignalType" SG_ 2032 DgnInf "UNM";
BA_ "VNSigSLHSSharedDiagnostic" SG_ 2032 DgnInf 1;
BA_ "VNSigAllNodes" SG_ 2032 DgnInf 1;
BA_ "GenSigDeltaValue" SG_ 2032 DgnInf 1;
BA_ "GenSigSendType" SG_ 2032 DgnInf 12;
BA_ "SignalLongName" SG_ 563 SPMCA_SusPrfMd6Avl "Suspension Performance Mode Customization Available : Suspension Performance Mode 6 Available";
BA_ "PacketOrder" SG_ 563 SPMCA_SusPrfMd6Avl 6;
BA_ "SignalType" SG_ 563 SPMCA_SusPrfMd6Avl "BLN";
BA_ "VNSigAllNodes" SG_ 563 SPMCA_SusPrfMd6Avl 1;
BA_ "SignalLongName" SG_ 563 SPMCA_SusPrfMd5Avl "Suspension Performance Mode Customization Available : Suspension Performance Mode 5 Available";
BA_ "PacketOrder" SG_ 563 SPMCA_SusPrfMd5Avl 5;
BA_ "SignalType" SG_ 563 SPMCA_SusPrfMd5Avl "BLN";
BA_ "VNSigAllNodes" SG_ 563 SPMCA_SusPrfMd5Avl 1;
BA_ "SignalLongName" SG_ 563 SPMCA_SusPrfMd4Avl "Suspension Performance Mode Customization Available : Suspension Performance Mode 4 Available";
BA_ "PacketOrder" SG_ 563 SPMCA_SusPrfMd4Avl 4;
BA_ "SignalType" SG_ 563 SPMCA_SusPrfMd4Avl "BLN";
BA_ "VNSigAllNodes" SG_ 563 SPMCA_SusPrfMd4Avl 1;
BA_ "SignalLongName" SG_ 563 SPMCA_SusPrfMd3Avl "Suspension Performance Mode Customization Available : Suspension Performance Mode 3 Available";
BA_ "PacketOrder" SG_ 563 SPMCA_SusPrfMd3Avl 3;
BA_ "SignalType" SG_ 563 SPMCA_SusPrfMd3Avl "BLN";
BA_ "VNSigAllNodes" SG_ 563 SPMCA_SusPrfMd3Avl 1;
BA_ "SignalLongName" SG_ 563 SPMCA_SusPrfMd2Avl "Suspension Performance Mode Customization Available : Suspension Performance Mode 2 Available";
BA_ "PacketOrder" SG_ 563 SPMCA_SusPrfMd2Avl 2;
BA_ "SignalType" SG_ 563 SPMCA_SusPrfMd2Avl "BLN";
BA_ "VNSigAllNodes" SG_ 563 SPMCA_SusPrfMd2Avl 1;
BA_ "SignalLongName" SG_ 563 SPMCA_SusPrfMd1Avl "Suspension Performance Mode Customization Available : Suspension Performance Mode 1 Available";
BA_ "PacketOrder" SG_ 563 SPMCA_SusPrfMd1Avl 1;
BA_ "SignalType" SG_ 563 SPMCA_SusPrfMd1Avl "BLN";
BA_ "VNSigAllNodes" SG_ 563 SPMCA_SusPrfMd1Avl 1;
BA_ "SignalLongName" SG_ 563 SPMCA_StrPrfMd6Avl "Steering Performance Mode Customization Available : Steering Performance Mode 6 Available";
BA_ "PacketOrder" SG_ 563 SPMCA_StrPrfMd6Avl 6;
BA_ "SignalType" SG_ 563 SPMCA_StrPrfMd6Avl "BLN";
BA_ "VNSigAllNodes" SG_ 563 SPMCA_StrPrfMd6Avl 1;
BA_ "SignalLongName" SG_ 563 SPMCA_StrPrfMd5Avl "Steering Performance Mode Customization Available : Steering Performance Mode 5 Available";
BA_ "PacketOrder" SG_ 563 SPMCA_StrPrfMd5Avl 5;
BA_ "SignalType" SG_ 563 SPMCA_StrPrfMd5Avl "BLN";
BA_ "VNSigAllNodes" SG_ 563 SPMCA_StrPrfMd5Avl 1;
BA_ "SignalLongName" SG_ 563 SPMCA_StrPrfMd4Avl "Steering Performance Mode Customization Available : Steering Performance Mode 4 Available";
BA_ "PacketOrder" SG_ 563 SPMCA_StrPrfMd4Avl 4;
BA_ "SignalType" SG_ 563 SPMCA_StrPrfMd4Avl "BLN";
BA_ "VNSigAllNodes" SG_ 563 SPMCA_StrPrfMd4Avl 1;
BA_ "SignalLongName" SG_ 563 SPMCA_StrPrfMd3Avl "Steering Performance Mode Customization Available : Steering Performance Mode 3 Available";
BA_ "PacketOrder" SG_ 563 SPMCA_StrPrfMd3Avl 3;
BA_ "SignalType" SG_ 563 SPMCA_StrPrfMd3Avl "BLN";
BA_ "VNSigAllNodes" SG_ 563 SPMCA_StrPrfMd3Avl 1;
BA_ "SignalLongName" SG_ 563 SPMCA_StrPrfMd2Avl "Steering Performance Mode Customization Available : Steering Performance Mode 2 Available";
BA_ "PacketOrder" SG_ 563 SPMCA_StrPrfMd2Avl 2;
BA_ "SignalType" SG_ 563 SPMCA_StrPrfMd2Avl "BLN";
BA_ "VNSigAllNodes" SG_ 563 SPMCA_StrPrfMd2Avl 1;
BA_ "SignalLongName" SG_ 563 SPMCA_StrPrfMd1Avl "Steering Performance Mode Customization Available : Steering Performance Mode 1 Available";
BA_ "PacketOrder" SG_ 563 SPMCA_StrPrfMd1Avl 1;
BA_ "SignalType" SG_ 563 SPMCA_StrPrfMd1Avl "BLN";
BA_ "VNSigAllNodes" SG_ 563 SPMCA_StrPrfMd1Avl 1;
BA_ "SignalLongName" SG_ 563 SPMCA_SndPrfMd6Avl "Sound Performance Mode Customization Available : Sound Performance Mode 6 Available";
BA_ "PacketOrder" SG_ 563 SPMCA_SndPrfMd6Avl 6;
BA_ "SignalType" SG_ 563 SPMCA_SndPrfMd6Avl "BLN";
BA_ "VNSigAllNodes" SG_ 563 SPMCA_SndPrfMd6Avl 1;
BA_ "SignalLongName" SG_ 563 SPMCA_SndPrfMd5Avl "Sound Performance Mode Customization Available : Sound Performance Mode 5 Available";
BA_ "PacketOrder" SG_ 563 SPMCA_SndPrfMd5Avl 5;
BA_ "SignalType" SG_ 563 SPMCA_SndPrfMd5Avl "BLN";
BA_ "VNSigAllNodes" SG_ 563 SPMCA_SndPrfMd5Avl 1;
BA_ "SignalLongName" SG_ 563 SPMCA_SndPrfMd4Avl "Sound Performance Mode Customization Available : Sound Performance Mode 4 Available";
BA_ "PacketOrder" SG_ 563 SPMCA_SndPrfMd4Avl 4;
BA_ "SignalType" SG_ 563 SPMCA_SndPrfMd4Avl "BLN";
BA_ "VNSigAllNodes" SG_ 563 SPMCA_SndPrfMd4Avl 1;
BA_ "SignalLongName" SG_ 563 SPMCA_SndPrfMd3Avl "Sound Performance Mode Customization Available : Sound Performance Mode 3 Available";
BA_ "PacketOrder" SG_ 563 SPMCA_SndPrfMd3Avl 3;
BA_ "SignalType" SG_ 563 SPMCA_SndPrfMd3Avl "BLN";
BA_ "VNSigAllNodes" SG_ 563 SPMCA_SndPrfMd3Avl 1;
BA_ "SignalLongName" SG_ 563 SPMCA_SndPrfMd2Avl "Sound Performance Mode Customization Available : Sound Performance Mode 2 Available";
BA_ "PacketOrder" SG_ 563 SPMCA_SndPrfMd2Avl 2;
BA_ "SignalType" SG_ 563 SPMCA_SndPrfMd2Avl "BLN";
BA_ "VNSigAllNodes" SG_ 563 SPMCA_SndPrfMd2Avl 1;
BA_ "SignalLongName" SG_ 563 SPMCA_SndPrfMd1Avl "Sound Performance Mode Customization Available : Sound Performance Mode 1 Available";
BA_ "PacketOrder" SG_ 563 SPMCA_SndPrfMd1Avl 1;
BA_ "SignalType" SG_ 563 SPMCA_SndPrfMd1Avl "BLN";
BA_ "VNSigAllNodes" SG_ 563 SPMCA_SndPrfMd1Avl 1;
BA_ "SignalLongName" SG_ 563 DPMCA_DispPrfMd6Avl "Display Performance Mode Customization Available : Display Performance Mode 6 Available";
BA_ "PacketOrder" SG_ 563 DPMCA_DispPrfMd6Avl 6;
BA_ "SignalType" SG_ 563 DPMCA_DispPrfMd6Avl "BLN";
BA_ "VNSigAllNodes" SG_ 563 DPMCA_DispPrfMd6Avl 1;
BA_ "SignalLongName" SG_ 563 DPMCA_DispPrfMd5Avl "Display Performance Mode Customization Available : Display Performance Mode 5 Available";
BA_ "PacketOrder" SG_ 563 DPMCA_DispPrfMd5Avl 5;
BA_ "SignalType" SG_ 563 DPMCA_DispPrfMd5Avl "BLN";
BA_ "VNSigAllNodes" SG_ 563 DPMCA_DispPrfMd5Avl 1;
BA_ "SignalLongName" SG_ 563 DPMCA_DispPrfMd4Avl "Display Performance Mode Customization Available : Display Performance Mode 4 Available";
BA_ "PacketOrder" SG_ 563 DPMCA_DispPrfMd4Avl 4;
BA_ "SignalType" SG_ 563 DPMCA_DispPrfMd4Avl "BLN";
BA_ "VNSigAllNodes" SG_ 563 DPMCA_DispPrfMd4Avl 1;
BA_ "SignalLongName" SG_ 563 DPMCA_DispPrfMd3Avl "Display Performance Mode Customization Available : Display Performance Mode 3 Available";
BA_ "PacketOrder" SG_ 563 DPMCA_DispPrfMd3Avl 3;
BA_ "SignalType" SG_ 563 DPMCA_DispPrfMd3Avl "BLN";
BA_ "VNSigAllNodes" SG_ 563 DPMCA_DispPrfMd3Avl 1;
BA_ "SignalLongName" SG_ 563 DPMCA_DispPrfMd2Avl "Display Performance Mode Customization Available : Display Performance Mode 2 Available";
BA_ "PacketOrder" SG_ 563 DPMCA_DispPrfMd2Avl 2;
BA_ "SignalType" SG_ 563 DPMCA_DispPrfMd2Avl "BLN";
BA_ "VNSigAllNodes" SG_ 563 DPMCA_DispPrfMd2Avl 1;
BA_ "SignalLongName" SG_ 563 DPMCA_DispPrfMd1Avl "Display Performance Mode Customization Available : Display Performance Mode 1 Available";
BA_ "PacketOrder" SG_ 563 DPMCA_DispPrfMd1Avl 1;
BA_ "SignalType" SG_ 563 DPMCA_DispPrfMd1Avl "BLN";
BA_ "VNSigAllNodes" SG_ 563 DPMCA_DispPrfMd1Avl 1;
BA_ "SignalLongName" SG_ 563 DPMCA_DrvlPrfMd6Avl "Driveline Performance Mode Customization Available : Driveline Performance Mode 6 Available";
BA_ "PacketOrder" SG_ 563 DPMCA_DrvlPrfMd6Avl 6;
BA_ "SignalType" SG_ 563 DPMCA_DrvlPrfMd6Avl "BLN";
BA_ "VNSigAllNodes" SG_ 563 DPMCA_DrvlPrfMd6Avl 1;
BA_ "SignalLongName" SG_ 563 DPMCA_DrvlPrfMd5Avl "Driveline Performance Mode Customization Available : Driveline Performance Mode 5 Available";
BA_ "PacketOrder" SG_ 563 DPMCA_DrvlPrfMd5Avl 5;
BA_ "SignalType" SG_ 563 DPMCA_DrvlPrfMd5Avl "BLN";
BA_ "VNSigAllNodes" SG_ 563 DPMCA_DrvlPrfMd5Avl 1;
BA_ "SignalLongName" SG_ 563 DPMCA_DrvlPrfMd4Avl "Driveline Performance Mode Customization Available : Driveline Performance Mode 4 Available";
BA_ "PacketOrder" SG_ 563 DPMCA_DrvlPrfMd4Avl 4;
BA_ "SignalType" SG_ 563 DPMCA_DrvlPrfMd4Avl "BLN";
BA_ "VNSigAllNodes" SG_ 563 DPMCA_DrvlPrfMd4Avl 1;
BA_ "SignalLongName" SG_ 563 DPMCA_DrvlPrfMd3Avl "Driveline Performance Mode Customization Available : Driveline Performance Mode 3 Available";
BA_ "PacketOrder" SG_ 563 DPMCA_DrvlPrfMd3Avl 3;
BA_ "SignalType" SG_ 563 DPMCA_DrvlPrfMd3Avl "BLN";
BA_ "VNSigAllNodes" SG_ 563 DPMCA_DrvlPrfMd3Avl 1;
BA_ "SignalLongName" SG_ 563 DPMCA_DrvlPrfMd2Avl "Driveline Performance Mode Customization Available : Driveline Performance Mode 2 Available";
BA_ "PacketOrder" SG_ 563 DPMCA_DrvlPrfMd2Avl 2;
BA_ "SignalType" SG_ 563 DPMCA_DrvlPrfMd2Avl "BLN";
BA_ "VNSigAllNodes" SG_ 563 DPMCA_DrvlPrfMd2Avl 1;
BA_ "SignalLongName" SG_ 563 DPMCA_DrvlPrfMd1Avl "Driveline Performance Mode Customization Available : Driveline Performance Mode 1 Available";
BA_ "PacketOrder" SG_ 563 DPMCA_DrvlPrfMd1Avl 1;
BA_ "SignalType" SG_ 563 DPMCA_DrvlPrfMd1Avl "BLN";
BA_ "VNSigAllNodes" SG_ 563 DPMCA_DrvlPrfMd1Avl 1;
BA_ "SignalLongName" SG_ 723 PerfTrcEngSpdRqStat "Performance Traction Engine Speed Request Status";
BA_ "SignalType" SG_ 723 PerfTrcEngSpdRqStat "ENM";
BA_ "VNSigAllNodes" SG_ 723 PerfTrcEngSpdRqStat 1;
BA_ "SignalLongName" SG_ 723 PerfTrcEngSpdLmtStat "Performance Traction Engine Speed Limiting Status";
BA_ "SignalType" SG_ 723 PerfTrcEngSpdLmtStat "ENM";
BA_ "VNSigAllNodes" SG_ 723 PerfTrcEngSpdLmtStat 1;
BA_ "SignalLongName" SG_ 723 PerfTrcTrqRqStat "Performance Traction Torque Request Status";
BA_ "SignalType" SG_ 723 PerfTrcTrqRqStat "ENM";
BA_ "VNSigAllNodes" SG_ 723 PerfTrcTrqRqStat 1;
BA_ "SignalLongName" SG_ 723 PerfTrcTrqLmtStat "Performance Traction Torque Limiting Status";
BA_ "SignalType" SG_ 723 PerfTrcTrqLmtStat "ENM";
BA_ "VNSigAllNodes" SG_ 723 PerfTrcTrqLmtStat 1;
BA_ "SignalLongName" SG_ 723 TachEngSpd "Tachometer Engine Speed";
BA_ "SignalType" SG_ 723 TachEngSpd "UNM";
BA_ "VNSigAllNodes" SG_ 723 TachEngSpd 1;
BA_ "SignalLongName" SG_ 419 ClrCGMLgsDgInf "Clear Central Gateway Module Legislated Diagnostic Information";
BA_ "SignalType" SG_ 419 ClrCGMLgsDgInf "BLN";
BA_ "VNSigAllNodes" SG_ 419 ClrCGMLgsDgInf 1;
BA_ "SignalLongName" SG_ 419 EngRunng "Engine Running";
BA_ "SignalType" SG_ 419 EngRunng "BLN";
BA_ "VNSigAllNodes" SG_ 419 EngRunng 1;
BA_ "SignalLongName" SG_ 1268 EngAirFltLfRmn "Engine Air Filter Life Remaining";
BA_ "SignalType" SG_ 1268 EngAirFltLfRmn "UNM";
BA_ "VNSigAllNodes" SG_ 1268 EngAirFltLfRmn 1;
BA_ "GenSigDeltaValue" SG_ 1268 EngAirFltLfRmn 1;
BA_ "GenSigSendType" SG_ 1268 EngAirFltLfRmn 12;
BA_ "SignalLongName" SG_ 1268 EngAirFltMonSt "Engine Air Filter Monitor Status";
BA_ "SignalType" SG_ 1268 EngAirFltMonSt "ENM";
BA_ "VNSigAllNodes" SG_ 1268 EngAirFltMonSt 1;
BA_ "GenSigSendType" SG_ 1268 EngAirFltMonSt 10;
BA_ "GenSigSendOnInit" SG_ 1268 EngAirFltMonSt 2;
BA_ "SignalLongName" SG_ 384 LKATqOvrDltCmdPrtVl "Lane Keeping Assist Torque Overlay Delta Command Protection Value";
BA_ "SignalType" SG_ 384 LKATqOvrDltCmdPrtVl "UNM";
BA_ "VNSigAllNodes" SG_ 384 LKATqOvrDltCmdPrtVl 1;
BA_ "GenSigDeltaValue" SG_ 384 LKATqOvrDltCmdPrtVl 1;
BA_ "GenSigSendType" SG_ 384 LKATqOvrDltCmdPrtVl 12;
BA_ "SignalLongName" SG_ 384 LKATqOvrDltCmdRC "Lane Keeping Assist Torque Overlay Delta Command Rolling Count";
BA_ "SignalType" SG_ 384 LKATqOvrDltCmdRC "UNM";
BA_ "VNSigAllNodes" SG_ 384 LKATqOvrDltCmdRC 1;
BA_ "GenSigDeltaValue" SG_ 384 LKATqOvrDltCmdRC 1;
BA_ "GenSigSendType" SG_ 384 LKATqOvrDltCmdRC 12;
BA_ "SignalLongName" SG_ 384 LKATODC_TrqVl "Lane Keeping Assist Torque Overlay Delta Command : Torque Value";
BA_ "PacketOrder" SG_ 384 LKATODC_TrqVl 2;
BA_ "SignalType" SG_ 384 LKATODC_TrqVl "SNM";
BA_ "VNSigAllNodes" SG_ 384 LKATODC_TrqVl 1;
BA_ "GenSigDeltaValue" SG_ 384 LKATODC_TrqVl 1;
BA_ "GenSigSendType" SG_ 384 LKATODC_TrqVl 12;
BA_ "SignalLongName" SG_ 384 LKATODC_TrqRqAct "Lane Keeping Assist Torque Overlay Delta Command : Torque Request Active";
BA_ "PacketOrder" SG_ 384 LKATODC_TrqRqAct 1;
BA_ "SignalType" SG_ 384 LKATODC_TrqRqAct "BLN";
BA_ "VNSigAllNodes" SG_ 384 LKATODC_TrqRqAct 1;
BA_ "GenSigSendType" SG_ 384 LKATODC_TrqRqAct 10;
BA_ "SignalLongName" SG_ 866 RegenBrkAxTrqAch "Regenerative Braking Axle Torque Achieved";
BA_ "SignalType" SG_ 866 RegenBrkAxTrqAch "UNM";
BA_ "VNSigAllNodes" SG_ 866 RegenBrkAxTrqAch 1;
BA_ "SignalLongName" SG_ 866 ColPrSysHzrdLghtsReq "Collision Preparation System Hazard Lights Request";
BA_ "SignalType" SG_ 866 ColPrSysHzrdLghtsReq "ENM";
BA_ "VNSigAllNodes" SG_ 866 ColPrSysHzrdLghtsReq 1;
BA_ "SignalLongName" SG_ 866 ColPrSysWndwsReq "Collision Preparation System Windows Request";
BA_ "SignalType" SG_ 866 ColPrSysWndwsReq "ENM";
BA_ "VNSigAllNodes" SG_ 866 ColPrSysWndwsReq 1;
BA_ "SignalLongName" SG_ 866 ColPrSysDrsReq "Collision Preparation System Doors Request";
BA_ "SignalType" SG_ 866 ColPrSysDrsReq "ENM";
BA_ "VNSigAllNodes" SG_ 866 ColPrSysDrsReq 1;
BA_ "SignalLongName" SG_ 866 ColPrSysSnrfReq "Collision Preparation System Sunroof Request";
BA_ "SignalType" SG_ 866 ColPrSysSnrfReq "ENM";
BA_ "VNSigAllNodes" SG_ 866 ColPrSysSnrfReq 1;
BA_ "SignalLongName" SG_ 866 CPSInfotmntMtReq "Collision Preparation System Infotainment Mute Request";
BA_ "SignalType" SG_ 866 CPSInfotmntMtReq "ENM";
BA_ "VNSigAllNodes" SG_ 866 CPSInfotmntMtReq 1;
BA_ "SignalLongName" SG_ 866 StBltTgtSetAvl "Seat Belt Tightening Settings Available";
BA_ "SignalType" SG_ 866 StBltTgtSetAvl "BLN";
BA_ "VNSigAllNodes" SG_ 866 StBltTgtSetAvl 1;
BA_ "SignalLongName" SG_ 866 StBltTgtCrtSetVal "Seat Belt Tightening Current Setting Value";
BA_ "SignalType" SG_ 866 StBltTgtCrtSetVal "ENM";
BA_ "VNSigAllNodes" SG_ 866 StBltTgtCrtSetVal 1;
BA_ "SignalLongName" SG_ 866 MotStBltUnblIO "Motorized Seat Belt Unavailable Indication On";
BA_ "SignalType" SG_ 866 MotStBltUnblIO "BLN";
BA_ "VNSigAllNodes" SG_ 866 MotStBltUnblIO 1;
BA_ "SignalLongName" SG_ 866 MotStBltFldIO "Motorized Seat Belt Failed Indication On";
BA_ "SignalType" SG_ 866 MotStBltFldIO "BLN";
BA_ "VNSigAllNodes" SG_ 866 MotStBltFldIO 1;
BA_ "SignalLongName" SG_ 479 PTAVHEnbld "Powertrain Auto Vehicle Hold Enabled";
BA_ "SignalType" SG_ 479 PTAVHEnbld "BLN";
BA_ "VNSigAllNodes" SG_ 479 PTAVHEnbld 1;
BA_ "SignalLongName" SG_ 479 PTAVHActv "Powertrain Auto Vehicle Hold Active";
BA_ "SignalType" SG_ 479 PTAVHActv "BLN";
BA_ "VNSigAllNodes" SG_ 479 PTAVHActv 1;
BA_ "SignalLongName" SG_ 479 PrplsnSysAtv "Propulsion System Active";
BA_ "SignalType" SG_ 479 PrplsnSysAtv "BLN";
BA_ "VNSigAllNodes" SG_ 479 PrplsnSysAtv 1;
BA_ "SignalLongName" SG_ 479 EngAutoStpNotProb "Engine Auto Stop Not Probable";
BA_ "SignalType" SG_ 479 EngAutoStpNotProb "BLN";
BA_ "VNSigAllNodes" SG_ 479 EngAutoStpNotProb 1;
BA_ "GenSigSendType" SG_ 479 EngAutoStpNotProb 10;
BA_ "SignalLongName" SG_ 479 EASSI_UnsdRsrvd2 "Engine Auto Start Stop Information : Unused and Reserved 2";
BA_ "PacketOrder" SG_ 479 EASSI_UnsdRsrvd2 7;
BA_ "SignalType" SG_ 479 EASSI_UnsdRsrvd2 "BLN";
BA_ "VNSigAllNodes" SG_ 479 EASSI_UnsdRsrvd2 1;
BA_ "GenSigSendType" SG_ 479 EASSI_UnsdRsrvd2 10;
BA_ "SignalLongName" SG_ 479 EASSI_StlDetd "Engine Auto Start Stop Information : Stall Detected";
BA_ "PacketOrder" SG_ 479 EASSI_StlDetd 5;
BA_ "SignalType" SG_ 479 EASSI_StlDetd "BLN";
BA_ "VNSigAllNodes" SG_ 479 EASSI_StlDetd 1;
BA_ "GenSigSendType" SG_ 479 EASSI_StlDetd 10;
BA_ "SignalLongName" SG_ 479 EASSI_TrqDetd "Engine Auto Start Stop Information : Torque Detected";
BA_ "PacketOrder" SG_ 479 EASSI_TrqDetd 4;
BA_ "SignalType" SG_ 479 EASSI_TrqDetd "BLN";
BA_ "VNSigAllNodes" SG_ 479 EASSI_TrqDetd 1;
BA_ "GenSigSendType" SG_ 479 EASSI_TrqDetd 10;
BA_ "SignalLongName" SG_ 479 EASSI_FuelReqOn "Engine Auto Start Stop Information : Fuel Requested On";
BA_ "PacketOrder" SG_ 479 EASSI_FuelReqOn 3;
BA_ "SignalType" SG_ 479 EASSI_FuelReqOn "BLN";
BA_ "VNSigAllNodes" SG_ 479 EASSI_FuelReqOn 1;
BA_ "GenSigSendType" SG_ 479 EASSI_FuelReqOn 10;
BA_ "SignalLongName" SG_ 479 EASSI_StrtTyp "Engine Auto Start Stop Information : Start Type";
BA_ "PacketOrder" SG_ 479 EASSI_StrtTyp 2;
BA_ "SignalType" SG_ 479 EASSI_StrtTyp "ENM";
BA_ "VNSigAllNodes" SG_ 479 EASSI_StrtTyp 1;
BA_ "GenSigSendType" SG_ 479 EASSI_StrtTyp 10;
BA_ "SignalLongName" SG_ 479 EASSI_StrtStpSt "Engine Auto Start Stop Information : Start Stop State";
BA_ "PacketOrder" SG_ 479 EASSI_StrtStpSt 1;
BA_ "SignalType" SG_ 479 EASSI_StrtStpSt "ENM";
BA_ "VNSigAllNodes" SG_ 479 EASSI_StrtStpSt 1;
BA_ "GenSigSendType" SG_ 479 EASSI_StrtStpSt 10;
BA_ "SignalLongName" SG_ 479 EASSI_TorqDetdIndet "Engine Auto Start Stop Information : Torque Detected Indeterminate";
BA_ "PacketOrder" SG_ 479 EASSI_TorqDetdIndet 6;
BA_ "SignalType" SG_ 479 EASSI_TorqDetdIndet "BLN";
BA_ "VNSigAllNodes" SG_ 479 EASSI_TorqDetdIndet 1;
BA_ "GenSigSendType" SG_ 479 EASSI_TorqDetdIndet 10;
BA_ "SignalLongName" SG_ 479 ASIRI_Indication08 "Auto Stop Inhibit Reason Indication : Indication 8";
BA_ "PacketOrder" SG_ 479 ASIRI_Indication08 8;
BA_ "SignalType" SG_ 479 ASIRI_Indication08 "BLN";
BA_ "VNSigAllNodes" SG_ 479 ASIRI_Indication08 1;
BA_ "GenSigSendType" SG_ 479 ASIRI_Indication08 10;
BA_ "SignalLongName" SG_ 479 ASIRI_Indication07 "Auto Stop Inhibit Reason Indication : Indication 7";
BA_ "PacketOrder" SG_ 479 ASIRI_Indication07 7;
BA_ "SignalType" SG_ 479 ASIRI_Indication07 "BLN";
BA_ "VNSigAllNodes" SG_ 479 ASIRI_Indication07 1;
BA_ "GenSigSendType" SG_ 479 ASIRI_Indication07 10;
BA_ "SignalLongName" SG_ 479 ASIRI_Indication06 "Auto Stop Inhibit Reason Indication : Indication 6";
BA_ "PacketOrder" SG_ 479 ASIRI_Indication06 6;
BA_ "SignalType" SG_ 479 ASIRI_Indication06 "BLN";
BA_ "VNSigAllNodes" SG_ 479 ASIRI_Indication06 1;
BA_ "GenSigSendType" SG_ 479 ASIRI_Indication06 10;
BA_ "SignalLongName" SG_ 479 ASIRI_Indication05 "Auto Stop Inhibit Reason Indication : Indication 5";
BA_ "PacketOrder" SG_ 479 ASIRI_Indication05 5;
BA_ "SignalType" SG_ 479 ASIRI_Indication05 "BLN";
BA_ "VNSigAllNodes" SG_ 479 ASIRI_Indication05 1;
BA_ "GenSigSendType" SG_ 479 ASIRI_Indication05 10;
BA_ "SignalLongName" SG_ 479 ASIRI_Indication04 "Auto Stop Inhibit Reason Indication : Indication 4";
BA_ "PacketOrder" SG_ 479 ASIRI_Indication04 4;
BA_ "SignalType" SG_ 479 ASIRI_Indication04 "BLN";
BA_ "VNSigAllNodes" SG_ 479 ASIRI_Indication04 1;
BA_ "GenSigSendType" SG_ 479 ASIRI_Indication04 10;
BA_ "SignalLongName" SG_ 479 ASIRI_Indication03 "Auto Stop Inhibit Reason Indication : Indication 3";
BA_ "PacketOrder" SG_ 479 ASIRI_Indication03 3;
BA_ "SignalType" SG_ 479 ASIRI_Indication03 "BLN";
BA_ "VNSigAllNodes" SG_ 479 ASIRI_Indication03 1;
BA_ "GenSigSendType" SG_ 479 ASIRI_Indication03 10;
BA_ "SignalLongName" SG_ 479 ASIRI_Indication02 "Auto Stop Inhibit Reason Indication : Indication 2";
BA_ "PacketOrder" SG_ 479 ASIRI_Indication02 2;
BA_ "SignalType" SG_ 479 ASIRI_Indication02 "BLN";
BA_ "VNSigAllNodes" SG_ 479 ASIRI_Indication02 1;
BA_ "GenSigSendType" SG_ 479 ASIRI_Indication02 10;
BA_ "SignalLongName" SG_ 479 ASIRI_Indication01 "Auto Stop Inhibit Reason Indication : Indication 1";
BA_ "PacketOrder" SG_ 479 ASIRI_Indication01 1;
BA_ "SignalType" SG_ 479 ASIRI_Indication01 "BLN";
BA_ "VNSigAllNodes" SG_ 479 ASIRI_Indication01 1;
BA_ "GenSigSendType" SG_ 479 ASIRI_Indication01 10;
BA_ "SignalLongName" SG_ 479 PTWrmgWtToShftIO "Powertrain Warming Wait To Shift Indication On";
BA_ "SignalType" SG_ 479 PTWrmgWtToShftIO "BLN";
BA_ "VNSigAllNodes" SG_ 479 PTWrmgWtToShftIO 1;
BA_ "SignalLongName" SG_ 479 PTShftLvrLckRqd "Powertrain Shift Lever Lock Requested";
BA_ "SignalType" SG_ 479 PTShftLvrLckRqd "BLN";
BA_ "VNSigAllNodes" SG_ 479 PTShftLvrLckRqd 1;
BA_ "SignalLongName" SG_ 1020 OtsAirTmpEmsnsRelV "Outside Air Temperature Emissions Related Validity";
BA_ "SignalType" SG_ 1020 OtsAirTmpEmsnsRelV "ENM";
BA_ "VNSigAllNodes" SG_ 1020 OtsAirTmpEmsnsRelV 1;
BA_ "SignalLongName" SG_ 1020 OtsAirTmpEmsnsRel "Outside Air Temperature Emissions Related";
BA_ "SignalType" SG_ 1020 OtsAirTmpEmsnsRel "UNM";
BA_ "VNSigAllNodes" SG_ 1020 OtsAirTmpEmsnsRel 1;
BA_ "SignalLongName" SG_ 1020 OATEmsnsRelCrValV "Outside Air Temperature Emissions Related Corrected Value Validity";
BA_ "SignalType" SG_ 1020 OATEmsnsRelCrValV "ENM";
BA_ "VNSigAllNodes" SG_ 1020 OATEmsnsRelCrValV 1;
BA_ "SignalLongName" SG_ 1020 OATEmsnsRelCrValM "Outside Air Temperature Emissions Related Corrected Value Mask";
BA_ "SignalType" SG_ 1020 OATEmsnsRelCrValM "ENM";
BA_ "VNSigAllNodes" SG_ 1020 OATEmsnsRelCrValM 1;
BA_ "SignalLongName" SG_ 1020 OATEmsnsRelCrVal "Outside Air Temperature Emissions Related Corrected Value";
BA_ "SignalType" SG_ 1020 OATEmsnsRelCrVal "UNM";
BA_ "VNSigAllNodes" SG_ 1020 OATEmsnsRelCrVal 1;
BA_ "SignalLongName" SG_ 1020 CatlystOutGasTempEstV "Catalyst Outlet Gas Temperature Estimate Validity";
BA_ "SignalType" SG_ 1020 CatlystOutGasTempEstV "ENM";
BA_ "VNSigAllNodes" SG_ 1020 CatlystOutGasTempEstV 1;
BA_ "SignalLongName" SG_ 1020 CatlystOutGasTempEst "Catalyst Outlet Gas Temperature Estimate";
BA_ "SignalType" SG_ 1020 CatlystOutGasTempEst "UNM";
BA_ "VNSigAllNodes" SG_ 1020 CatlystOutGasTempEst 1;
BA_ "SignalLongName" SG_ 1020 OtsAirTmpCrValMsk "Outside Air Temperature Corrected Value Mask";
BA_ "SignalType" SG_ 1020 OtsAirTmpCrValMsk "ENM";
BA_ "VNSigAllNodes" SG_ 1020 OtsAirTmpCrValMsk 1;
BA_ "GenSigSendType" SG_ 1020 OtsAirTmpCrValMsk 10;
BA_ "SignalLongName" SG_ 1020 OtsAirTmpV "Outside Air Temperature Validity";
BA_ "SignalType" SG_ 1020 OtsAirTmpV "ENM";
BA_ "VNSigAllNodes" SG_ 1020 OtsAirTmpV 1;
BA_ "GenSigSendType" SG_ 1020 OtsAirTmpV 10;
BA_ "SignalLongName" SG_ 1020 OtsAirTmpCrValV "Outside Air Temperature Corrected Value Validity";
BA_ "SignalType" SG_ 1020 OtsAirTmpCrValV "ENM";
BA_ "VNSigAllNodes" SG_ 1020 OtsAirTmpCrValV 1;
BA_ "GenSigSendType" SG_ 1020 OtsAirTmpCrValV 10;
BA_ "SignalLongName" SG_ 1020 OtsAirTmpCrVal "Outside Air Temperature Corrected Value";
BA_ "SignalType" SG_ 1020 OtsAirTmpCrVal "UNM";
BA_ "VNSigAllNodes" SG_ 1020 OtsAirTmpCrVal 1;
BA_ "GenSigDeltaValue" SG_ 1020 OtsAirTmpCrVal 1;
BA_ "GenSigSendType" SG_ 1020 OtsAirTmpCrVal 12;
BA_ "GenSigSendOnInit" SG_ 1020 OtsAirTmpCrVal 1;
BA_ "SignalLongName" SG_ 1020 OtsAirTmp "Outside Air Temperature";
BA_ "SignalType" SG_ 1020 OtsAirTmp "UNM";
BA_ "VNSigAllNodes" SG_ 1020 OtsAirTmp 1;
BA_ "GenSigDeltaValue" SG_ 1020 OtsAirTmp 1;
BA_ "GenSigSendType" SG_ 1020 OtsAirTmp 12;
BA_ "GenSigSendOnInit" SG_ 1020 OtsAirTmp 1;
BA_ "SignalLongName" SG_ 1020 EngInltSpcfcHmdtyV "Engine Inlet Specific Humidity Validity";
BA_ "SignalType" SG_ 1020 EngInltSpcfcHmdtyV "ENM";
BA_ "VNSigAllNodes" SG_ 1020 EngInltSpcfcHmdtyV 1;
BA_ "GenSigSendType" SG_ 1020 EngInltSpcfcHmdtyV 10;
BA_ "SignalLongName" SG_ 1020 EngInltSpcfcHmdtyM "Engine Inlet Specific Humidity Mask";
BA_ "SignalType" SG_ 1020 EngInltSpcfcHmdtyM "ENM";
BA_ "VNSigAllNodes" SG_ 1020 EngInltSpcfcHmdtyM 1;
BA_ "GenSigSendType" SG_ 1020 EngInltSpcfcHmdtyM 10;
BA_ "SignalLongName" SG_ 1020 EngInltSpcfcHmdty "Engine Inlet Specific Humidity";
BA_ "SignalType" SG_ 1020 EngInltSpcfcHmdty "UNM";
BA_ "VNSigAllNodes" SG_ 1020 EngInltSpcfcHmdty 1;
BA_ "GenSigDeltaValue" SG_ 1020 EngInltSpcfcHmdty 1;
BA_ "GenSigSendType" SG_ 1020 EngInltSpcfcHmdty 12;
BA_ "SignalLongName" SG_ 567 LnchCtrlMdStatARC "Launch Control Mode Status Alive Rolling Count";
BA_ "SignalType" SG_ 567 LnchCtrlMdStatARC "UNM";
BA_ "VNSigAllNodes" SG_ 567 LnchCtrlMdStatARC 1;
BA_ "SignalLongName" SG_ 567 LnchCtrlMdStatPVal "Launch Control Mode Status Protection Value";
BA_ "SignalType" SG_ 567 LnchCtrlMdStatPVal "UNM";
BA_ "VNSigAllNodes" SG_ 567 LnchCtrlMdStatPVal 1;
BA_ "SignalLongName" SG_ 567 LnchCtrlWhlSlpStat "Launch Control Wheel Slip Status";
BA_ "SignalType" SG_ 567 LnchCtrlWhlSlpStat "ENM";
BA_ "VNSigAllNodes" SG_ 567 LnchCtrlWhlSlpStat 1;
BA_ "GenSigSendType" SG_ 567 LnchCtrlWhlSlpStat 10;
BA_ "SignalLongName" SG_ 567 LnchCtrlMdStat "Launch Control Mode Status";
BA_ "SignalType" SG_ 567 LnchCtrlMdStat "ENM";
BA_ "VNSigAllNodes" SG_ 567 LnchCtrlMdStat 1;
BA_ "GenSigSendType" SG_ 567 LnchCtrlMdStat 10;
BA_ "SignalLongName" SG_ 567 LnchCtrlEngRPMStat "Launch Control Engine RPM Status";
BA_ "SignalType" SG_ 567 LnchCtrlEngRPMStat "ENM";
BA_ "VNSigAllNodes" SG_ 567 LnchCtrlEngRPMStat 1;
BA_ "GenSigSendType" SG_ 567 LnchCtrlEngRPMStat 10;
BA_ "SignalLongName" SG_ 567 ExtHlStrAssCsCrStVal "Extended Hill Start Assist Customization Current Setting Value";
BA_ "SignalType" SG_ 567 ExtHlStrAssCsCrStVal "ENM";
BA_ "VNSigAllNodes" SG_ 567 ExtHlStrAssCsCrStVal 1;
BA_ "SignalLongName" SG_ 567 ExtHlStrAssCsStAvl "Extended Hill Start Assist Customization Setting Available";
BA_ "SignalType" SG_ 567 ExtHlStrAssCsStAvl "BLN";
BA_ "VNSigAllNodes" SG_ 567 ExtHlStrAssCsStAvl 1;
BA_ "SignalLongName" SG_ 567 DrvStyPerfMdCsCrStVal "Driving Style Performance Mode Customization Current Setting Value";
BA_ "SignalType" SG_ 567 DrvStyPerfMdCsCrStVal "ENM";
BA_ "VNSigAllNodes" SG_ 567 DrvStyPerfMdCsCrStVal 1;
BA_ "SignalLongName" SG_ 567 DrvStyPerfMdCsStAvl "Driving Style Performance Mode Customization Setting Available";
BA_ "SignalType" SG_ 567 DrvStyPerfMdCsStAvl "BLN";
BA_ "VNSigAllNodes" SG_ 567 DrvStyPerfMdCsStAvl 1;
BA_ "SignalLongName" SG_ 567 PsngStPerfMdCsCrStVal "Passenger Seat Performance Mode Customization Current Setting Value";
BA_ "SignalType" SG_ 567 PsngStPerfMdCsCrStVal "ENM";
BA_ "VNSigAllNodes" SG_ 567 PsngStPerfMdCsCrStVal 1;
BA_ "SignalLongName" SG_ 567 PsngStPerfMdCsStAvl "Passenger Seat Performance Mode Customization Setting Available";
BA_ "SignalType" SG_ 567 PsngStPerfMdCsStAvl "BLN";
BA_ "VNSigAllNodes" SG_ 567 PsngStPerfMdCsStAvl 1;
BA_ "SignalLongName" SG_ 567 DrvrStPerfMdCsCrStVal "Driver Seat Performance Mode Customization Current Setting Value";
BA_ "SignalType" SG_ 567 DrvrStPerfMdCsCrStVal "ENM";
BA_ "VNSigAllNodes" SG_ 567 DrvrStPerfMdCsCrStVal 1;
BA_ "SignalLongName" SG_ 567 DrvrStPerfMdCsStAvl "Driver Seat Performance Mode Customization Setting Available";
BA_ "SignalType" SG_ 567 DrvrStPerfMdCsStAvl "BLN";
BA_ "VNSigAllNodes" SG_ 567 DrvrStPerfMdCsStAvl 1;
BA_ "SignalLongName" SG_ 567 ACCPerfMdCsCrStVal "Adaptive Cruise Control Performance Mode Customization Current Setting Value";
BA_ "SignalType" SG_ 567 ACCPerfMdCsCrStVal "ENM";
BA_ "VNSigAllNodes" SG_ 567 ACCPerfMdCsCrStVal 1;
BA_ "SignalLongName" SG_ 567 ACCPerfMdCsStAvl "Adaptive Cruise Control Performance Mode Customization Setting Available";
BA_ "SignalType" SG_ 567 ACCPerfMdCsStAvl "BLN";
BA_ "VNSigAllNodes" SG_ 567 ACCPerfMdCsStAvl 1;
BA_ "SignalLongName" SG_ 1219 DslExhFldDiagWrnIdRq "Diesel Exhaust Fluid System Diagnostic Warning Indication Request";
BA_ "SignalType" SG_ 1219 DslExhFldDiagWrnIdRq "ENM";
BA_ "VNSigAllNodes" SG_ 1219 DslExhFldDiagWrnIdRq 1;
BA_ "SignalLongName" SG_ 1219 DslEmnsOBDMrkt "Diesel Emissions OBD Market";
BA_ "SignalType" SG_ 1219 DslEmnsOBDMrkt "ENM";
BA_ "VNSigAllNodes" SG_ 1219 DslEmnsOBDMrkt 1;
BA_ "SignalLongName" SG_ 1219 DslExNxEmWrngIndRq "Diesel Exhaust NOx Emissions Too High Warning Indication Request";
BA_ "SignalType" SG_ 1219 DslExNxEmWrngIndRq "ENM";
BA_ "VNSigAllNodes" SG_ 1219 DslExNxEmWrngIndRq 1;
BA_ "SignalLongName" SG_ 1219 DEFWVSL_S3SpdLmt "Diesel Exhaust Fluid Warning Vehicle Speed Limit : Stage 3 Vehicle Speed Limit";
BA_ "PacketOrder" SG_ 1219 DEFWVSL_S3SpdLmt 3;
BA_ "SignalType" SG_ 1219 DEFWVSL_S3SpdLmt "UNM";
BA_ "VNSigAllNodes" SG_ 1219 DEFWVSL_S3SpdLmt 1;
BA_ "SignalLongName" SG_ 1219 DEFWVSL_S2SpdLmt "Diesel Exhaust Fluid Warning Vehicle Speed Limit : Stage 2 Vehicle Speed Limit";
BA_ "PacketOrder" SG_ 1219 DEFWVSL_S2SpdLmt 2;
BA_ "SignalType" SG_ 1219 DEFWVSL_S2SpdLmt "UNM";
BA_ "VNSigAllNodes" SG_ 1219 DEFWVSL_S2SpdLmt 1;
BA_ "SignalLongName" SG_ 1219 DEFWVSL_S1SpdLmt "Diesel Exhaust Fluid Warning Vehicle Speed Limit : Stage 1 Vehicle Speed Limit";
BA_ "PacketOrder" SG_ 1219 DEFWVSL_S1SpdLmt 1;
BA_ "SignalType" SG_ 1219 DEFWVSL_S1SpdLmt "UNM";
BA_ "VNSigAllNodes" SG_ 1219 DEFWVSL_S1SpdLmt 1;
BA_ "SignalLongName" SG_ 1219 DslExFldTpWrngIndRq "Diesel Exhaust Fluid Tampering Warning Indication Request";
BA_ "SignalType" SG_ 1219 DslExFldTpWrngIndRq "ENM";
BA_ "VNSigAllNodes" SG_ 1219 DslExFldTpWrngIndRq 1;
BA_ "SignalLongName" SG_ 1219 DslExhFldQlyWrngIReq "Diesel Exhaust Fluid Quality Warning Indication Request";
BA_ "SignalType" SG_ 1219 DslExhFldQlyWrngIReq "ENM";
BA_ "VNSigAllNodes" SG_ 1219 DslExhFldQlyWrngIReq 1;
BA_ "SignalLongName" SG_ 1219 DslExhFldWrngIdRqER "Diesel Exhaust Fluid Level Warning Indication Request Extended Range";
BA_ "SignalType" SG_ 1219 DslExhFldWrngIdRqER "ENM";
BA_ "VNSigAllNodes" SG_ 1219 DslExhFldWrngIdRqER 1;
BA_ "SignalLongName" SG_ 1219 DslExFldCnWrngIndRq "Diesel Exhaust Fluid Consumption Monitoring Warning Indication Request";
BA_ "SignalType" SG_ 1219 DslExFldCnWrngIndRq "ENM";
BA_ "VNSigAllNodes" SG_ 1219 DslExFldCnWrngIndRq 1;
BA_ "SignalLongName" SG_ 372 ARSOpStat "Active Rear Steer Operational Status";
BA_ "SignalType" SG_ 372 ARSOpStat "ENM";
BA_ "VNSigAllNodes" SG_ 372 ARSOpStat 1;
BA_ "SignalLongName" SG_ 372 ARSAlgmtCmplt "Active Rear Steer Alignment Complete";
BA_ "SignalType" SG_ 372 ARSAlgmtCmplt "BLN";
BA_ "VNSigAllNodes" SG_ 372 ARSAlgmtCmplt 1;
BA_ "SignalLongName" SG_ 372 ARSActAnglV "Active Rear Steer Actual Angle Validity";
BA_ "SignalType" SG_ 372 ARSActAnglV "ENM";
BA_ "VNSigAllNodes" SG_ 372 ARSActAnglV 1;
BA_ "SignalLongName" SG_ 372 ARSActAngl "Active Rear Steer Actual Angle";
BA_ "SignalType" SG_ 372 ARSActAngl "SNM";
BA_ "VNSigAllNodes" SG_ 372 ARSActAngl 1;
BA_ "SignalLongName" SG_ 372 ARSActAngStsRegtChksm "Active Rear Steer Actual Angle Status Regenerated Checksum";
BA_ "SignalType" SG_ 372 ARSActAngStsRegtChksm "UNM";
BA_ "VNSigAllNodes" SG_ 372 ARSActAngStsRegtChksm 1;
BA_ "SignalLongName" SG_ 372 ARSActAngRegtARC "Active Rear Steer Actual Angle Regenerated Alive Rolling Count";
BA_ "SignalType" SG_ 372 ARSActAngRegtARC "UNM";
BA_ "VNSigAllNodes" SG_ 372 ARSActAngRegtARC 1;
BA_ "SignalLongName" SG_ 372 ARSFlrIO "Active Rear Steer Failure Indication On";
BA_ "SignalType" SG_ 372 ARSFlrIO "BLN";
BA_ "VNSigAllNodes" SG_ 372 ARSFlrIO 1;
BA_ "SignalLongName" SG_ 565 PerfMdMainMenuType "Performance Mode Main Menu Type";
BA_ "SignalType" SG_ 565 PerfMdMainMenuType "ENM";
BA_ "VNSigAllNodes" SG_ 565 PerfMdMainMenuType 1;
BA_ "GenSigSendType" SG_ 565 PerfMdMainMenuType 10;
BA_ "GenSigSendOnInit" SG_ 565 PerfMdMainMenuType 2;
BA_ "SignalLongName" SG_ 565 PSPMCA_PsngStPrfMd6Avl "Passenger Seat Performance Mode Customization Available : Passenger Seat Performance Mode 6 Available";
BA_ "PacketOrder" SG_ 565 PSPMCA_PsngStPrfMd6Avl 6;
BA_ "SignalType" SG_ 565 PSPMCA_PsngStPrfMd6Avl "BLN";
BA_ "VNSigAllNodes" SG_ 565 PSPMCA_PsngStPrfMd6Avl 1;
BA_ "SignalLongName" SG_ 565 PSPMCA_PsngStPrfMd5Avl "Passenger Seat Performance Mode Customization Available : Passenger Seat Performance Mode 5 Available";
BA_ "PacketOrder" SG_ 565 PSPMCA_PsngStPrfMd5Avl 5;
BA_ "SignalType" SG_ 565 PSPMCA_PsngStPrfMd5Avl "BLN";
BA_ "VNSigAllNodes" SG_ 565 PSPMCA_PsngStPrfMd5Avl 1;
BA_ "SignalLongName" SG_ 565 PSPMCA_PsngStPrfMd4Avl "Passenger Seat Performance Mode Customization Available : Passenger Seat Performance Mode 4 Available";
BA_ "PacketOrder" SG_ 565 PSPMCA_PsngStPrfMd4Avl 4;
BA_ "SignalType" SG_ 565 PSPMCA_PsngStPrfMd4Avl "BLN";
BA_ "VNSigAllNodes" SG_ 565 PSPMCA_PsngStPrfMd4Avl 1;
BA_ "SignalLongName" SG_ 565 PSPMCA_PsngStPrfMd3Avl "Passenger Seat Performance Mode Customization Available : Passenger Seat Performance Mode 3 Available";
BA_ "PacketOrder" SG_ 565 PSPMCA_PsngStPrfMd3Avl 3;
BA_ "SignalType" SG_ 565 PSPMCA_PsngStPrfMd3Avl "BLN";
BA_ "VNSigAllNodes" SG_ 565 PSPMCA_PsngStPrfMd3Avl 1;
BA_ "SignalLongName" SG_ 565 PSPMCA_PsngStPrfMd2Avl "Passenger Seat Performance Mode Customization Available : Passenger Seat Performance Mode 2 Available";
BA_ "PacketOrder" SG_ 565 PSPMCA_PsngStPrfMd2Avl 2;
BA_ "SignalType" SG_ 565 PSPMCA_PsngStPrfMd2Avl "BLN";
BA_ "VNSigAllNodes" SG_ 565 PSPMCA_PsngStPrfMd2Avl 1;
BA_ "SignalLongName" SG_ 565 PSPMCA_PsngStPrfMd1Avl "Passenger Seat Performance Mode Customization Available : Passenger Seat Performance Mode 1 Available";
BA_ "PacketOrder" SG_ 565 PSPMCA_PsngStPrfMd1Avl 1;
BA_ "SignalType" SG_ 565 PSPMCA_PsngStPrfMd1Avl "BLN";
BA_ "VNSigAllNodes" SG_ 565 PSPMCA_PsngStPrfMd1Avl 1;
BA_ "SignalLongName" SG_ 565 DSPMCA_DrvStyPrfMd7Avl "Driving Style Performance Mode Customization Available : Driving Style Performance Mode 7 Available";
BA_ "PacketOrder" SG_ 565 DSPMCA_DrvStyPrfMd7Avl 7;
BA_ "SignalType" SG_ 565 DSPMCA_DrvStyPrfMd7Avl "BLN";
BA_ "VNSigAllNodes" SG_ 565 DSPMCA_DrvStyPrfMd7Avl 1;
BA_ "SignalLongName" SG_ 565 DSPMCA_DrvStyPrfMd6Avl "Driving Style Performance Mode Customization Available : Driving Style Performance Mode 6 Available";
BA_ "PacketOrder" SG_ 565 DSPMCA_DrvStyPrfMd6Avl 6;
BA_ "SignalType" SG_ 565 DSPMCA_DrvStyPrfMd6Avl "BLN";
BA_ "VNSigAllNodes" SG_ 565 DSPMCA_DrvStyPrfMd6Avl 1;
BA_ "SignalLongName" SG_ 565 DSPMCA_DrvStyPrfMd5Avl "Driving Style Performance Mode Customization Available : Driving Style Performance Mode 5 Available";
BA_ "PacketOrder" SG_ 565 DSPMCA_DrvStyPrfMd5Avl 5;
BA_ "SignalType" SG_ 565 DSPMCA_DrvStyPrfMd5Avl "BLN";
BA_ "VNSigAllNodes" SG_ 565 DSPMCA_DrvStyPrfMd5Avl 1;
BA_ "SignalLongName" SG_ 565 DSPMCA_DrvStyPrfMd4Avl "Driving Style Performance Mode Customization Available : Driving Style Performance Mode 4 Available";
BA_ "PacketOrder" SG_ 565 DSPMCA_DrvStyPrfMd4Avl 4;
BA_ "SignalType" SG_ 565 DSPMCA_DrvStyPrfMd4Avl "BLN";
BA_ "VNSigAllNodes" SG_ 565 DSPMCA_DrvStyPrfMd4Avl 1;
BA_ "SignalLongName" SG_ 565 DSPMCA_DrvStyPrfMd3Avl "Driving Style Performance Mode Customization Available : Driving Style Performance Mode 3 Available";
BA_ "PacketOrder" SG_ 565 DSPMCA_DrvStyPrfMd3Avl 3;
BA_ "SignalType" SG_ 565 DSPMCA_DrvStyPrfMd3Avl "BLN";
BA_ "VNSigAllNodes" SG_ 565 DSPMCA_DrvStyPrfMd3Avl 1;
BA_ "SignalLongName" SG_ 565 DSPMCA_DrvStyPrfMd2Avl "Driving Style Performance Mode Customization Available : Driving Style Performance Mode 2 Available";
BA_ "PacketOrder" SG_ 565 DSPMCA_DrvStyPrfMd2Avl 2;
BA_ "SignalType" SG_ 565 DSPMCA_DrvStyPrfMd2Avl "BLN";
BA_ "VNSigAllNodes" SG_ 565 DSPMCA_DrvStyPrfMd2Avl 1;
BA_ "SignalLongName" SG_ 565 DSPMCA_DrvStyPrfMd1Avl "Driving Style Performance Mode Customization Available : Driving Style Performance Mode 1 Available";
BA_ "PacketOrder" SG_ 565 DSPMCA_DrvStyPrfMd1Avl 1;
BA_ "SignalType" SG_ 565 DSPMCA_DrvStyPrfMd1Avl "BLN";
BA_ "VNSigAllNodes" SG_ 565 DSPMCA_DrvStyPrfMd1Avl 1;
BA_ "SignalLongName" SG_ 565 DSPMCA_DrvrStPrfMd6Avl "Driver Seat Performance Mode Customization Available : Driver Seat Performance Mode 6 Available";
BA_ "PacketOrder" SG_ 565 DSPMCA_DrvrStPrfMd6Avl 6;
BA_ "SignalType" SG_ 565 DSPMCA_DrvrStPrfMd6Avl "BLN";
BA_ "VNSigAllNodes" SG_ 565 DSPMCA_DrvrStPrfMd6Avl 1;
BA_ "SignalLongName" SG_ 565 DSPMCA_DrvrStPrfMd5Avl "Driver Seat Performance Mode Customization Available : Driver Seat Performance Mode 5 Available";
BA_ "PacketOrder" SG_ 565 DSPMCA_DrvrStPrfMd5Avl 5;
BA_ "SignalType" SG_ 565 DSPMCA_DrvrStPrfMd5Avl "BLN";
BA_ "VNSigAllNodes" SG_ 565 DSPMCA_DrvrStPrfMd5Avl 1;
BA_ "SignalLongName" SG_ 565 DSPMCA_DrvrStPrfMd4Avl "Driver Seat Performance Mode Customization Available : Driver Seat Performance Mode 4 Available";
BA_ "PacketOrder" SG_ 565 DSPMCA_DrvrStPrfMd4Avl 4;
BA_ "SignalType" SG_ 565 DSPMCA_DrvrStPrfMd4Avl "BLN";
BA_ "VNSigAllNodes" SG_ 565 DSPMCA_DrvrStPrfMd4Avl 1;
BA_ "SignalLongName" SG_ 565 DSPMCA_DrvrStPrfMd3Avl "Driver Seat Performance Mode Customization Available : Driver Seat Performance Mode 3 Available";
BA_ "PacketOrder" SG_ 565 DSPMCA_DrvrStPrfMd3Avl 3;
BA_ "SignalType" SG_ 565 DSPMCA_DrvrStPrfMd3Avl "BLN";
BA_ "VNSigAllNodes" SG_ 565 DSPMCA_DrvrStPrfMd3Avl 1;
BA_ "SignalLongName" SG_ 565 DSPMCA_DrvrStPrfMd2Avl "Driver Seat Performance Mode Customization Available : Driver Seat Performance Mode 2 Available";
BA_ "PacketOrder" SG_ 565 DSPMCA_DrvrStPrfMd2Avl 2;
BA_ "SignalType" SG_ 565 DSPMCA_DrvrStPrfMd2Avl "BLN";
BA_ "VNSigAllNodes" SG_ 565 DSPMCA_DrvrStPrfMd2Avl 1;
BA_ "SignalLongName" SG_ 565 DSPMCA_DrvrStPrfMd1Avl "Driver Seat Performance Mode Customization Available : Driver Seat Performance Mode 1 Available";
BA_ "PacketOrder" SG_ 565 DSPMCA_DrvrStPrfMd1Avl 1;
BA_ "SignalType" SG_ 565 DSPMCA_DrvrStPrfMd1Avl "BLN";
BA_ "VNSigAllNodes" SG_ 565 DSPMCA_DrvrStPrfMd1Avl 1;
BA_ "SignalLongName" SG_ 565 ACCPMCA_ACCPrfMd6Avl "Adaptive Cruise Control Performance Mode Customization Available : Adaptive Cruise Control Performance Mode 6 Available";
BA_ "PacketOrder" SG_ 565 ACCPMCA_ACCPrfMd6Avl 6;
BA_ "SignalType" SG_ 565 ACCPMCA_ACCPrfMd6Avl "BLN";
BA_ "VNSigAllNodes" SG_ 565 ACCPMCA_ACCPrfMd6Avl 1;
BA_ "SignalLongName" SG_ 565 ACCPMCA_ACCPrfMd5Avl "Adaptive Cruise Control Performance Mode Customization Available : Adaptive Cruise Control Performance Mode 5 Available";
BA_ "PacketOrder" SG_ 565 ACCPMCA_ACCPrfMd5Avl 5;
BA_ "SignalType" SG_ 565 ACCPMCA_ACCPrfMd5Avl "BLN";
BA_ "VNSigAllNodes" SG_ 565 ACCPMCA_ACCPrfMd5Avl 1;
BA_ "SignalLongName" SG_ 565 ACCPMCA_ACCPrfMd4Avl "Adaptive Cruise Control Performance Mode Customization Available : Adaptive Cruise Control Performance Mode 4 Available";
BA_ "PacketOrder" SG_ 565 ACCPMCA_ACCPrfMd4Avl 4;
BA_ "SignalType" SG_ 565 ACCPMCA_ACCPrfMd4Avl "BLN";
BA_ "VNSigAllNodes" SG_ 565 ACCPMCA_ACCPrfMd4Avl 1;
BA_ "SignalLongName" SG_ 565 ACCPMCA_ACCPrfMd3Avl "Adaptive Cruise Control Performance Mode Customization Available : Adaptive Cruise Control Performance Mode 3 Available";
BA_ "PacketOrder" SG_ 565 ACCPMCA_ACCPrfMd3Avl 3;
BA_ "SignalType" SG_ 565 ACCPMCA_ACCPrfMd3Avl "BLN";
BA_ "VNSigAllNodes" SG_ 565 ACCPMCA_ACCPrfMd3Avl 1;
BA_ "SignalLongName" SG_ 565 ACCPMCA_ACCPrfMd2Avl "Adaptive Cruise Control Performance Mode Customization Available : Adaptive Cruise Control Performance Mode 2 Available";
BA_ "PacketOrder" SG_ 565 ACCPMCA_ACCPrfMd2Avl 2;
BA_ "SignalType" SG_ 565 ACCPMCA_ACCPrfMd2Avl "BLN";
BA_ "VNSigAllNodes" SG_ 565 ACCPMCA_ACCPrfMd2Avl 1;
BA_ "SignalLongName" SG_ 565 ACCPMCA_ACCPrfMd1Avl "Adaptive Cruise Control Performance Mode Customization Available : Adaptive Cruise Control Performance Mode 1 Available";
BA_ "PacketOrder" SG_ 565 ACCPMCA_ACCPrfMd1Avl 1;
BA_ "SignalType" SG_ 565 ACCPMCA_ACCPrfMd1Avl "BLN";
BA_ "VNSigAllNodes" SG_ 565 ACCPMCA_ACCPrfMd1Avl 1;
BA_ "SignalLongName" SG_ 500 AutoVehMdSelctIntrStat "Automatic Vehicle Mode Selection Interface Status";
BA_ "SignalType" SG_ 500 AutoVehMdSelctIntrStat "ENM";
BA_ "VNSigAllNodes" SG_ 500 AutoVehMdSelctIntrStat 1;
BA_ "SignalLongName" SG_ 500 EnhDrvMdSwChUseAct "Enhanced Driver Selected Mode Switch Chassis Use Active";
BA_ "SignalType" SG_ 500 EnhDrvMdSwChUseAct "BLN";
BA_ "VNSigAllNodes" SG_ 500 EnhDrvMdSwChUseAct 1;
BA_ "SignalLongName" SG_ 500 EnhDrvSelMdSwStat "Enhanced Driver Selected Mode Switch Status";
BA_ "SignalType" SG_ 500 EnhDrvSelMdSwStat "ENM";
BA_ "VNSigAllNodes" SG_ 500 EnhDrvSelMdSwStat 1;
BA_ "SignalLongName" SG_ 500 DrvSelMd8Stat "Driver Selected Mode 8 Status";
BA_ "SignalType" SG_ 500 DrvSelMd8Stat "ENM";
BA_ "VNSigAllNodes" SG_ 500 DrvSelMd8Stat 1;
BA_ "GenSigSendType" SG_ 500 DrvSelMd8Stat 10;
BA_ "SignalLongName" SG_ 500 DrvSelMd8ReqDnd "Driver Selected Mode 8 Request Denied";
BA_ "SignalType" SG_ 500 DrvSelMd8ReqDnd "BLN";
BA_ "VNSigAllNodes" SG_ 500 DrvSelMd8ReqDnd 1;
BA_ "GenSigSendType" SG_ 500 DrvSelMd8ReqDnd 10;
BA_ "SignalLongName" SG_ 500 DrvSelMd7Stat "Driver Selected Mode 7 Status";
BA_ "SignalType" SG_ 500 DrvSelMd7Stat "ENM";
BA_ "VNSigAllNodes" SG_ 500 DrvSelMd7Stat 1;
BA_ "GenSigSendType" SG_ 500 DrvSelMd7Stat 10;
BA_ "SignalLongName" SG_ 500 DrvSelMd7ReqDnd "Driver Selected Mode 7 Request Denied";
BA_ "SignalType" SG_ 500 DrvSelMd7ReqDnd "BLN";
BA_ "VNSigAllNodes" SG_ 500 DrvSelMd7ReqDnd 1;
BA_ "GenSigSendType" SG_ 500 DrvSelMd7ReqDnd 10;
BA_ "SignalLongName" SG_ 500 DrvSelMd6Stat "Driver Selected Mode 6 Status";
BA_ "SignalType" SG_ 500 DrvSelMd6Stat "ENM";
BA_ "VNSigAllNodes" SG_ 500 DrvSelMd6Stat 1;
BA_ "GenSigSendType" SG_ 500 DrvSelMd6Stat 10;
BA_ "SignalLongName" SG_ 500 DrvSelMd6ReqDnd "Driver Selected Mode 6 Request Denied";
BA_ "SignalType" SG_ 500 DrvSelMd6ReqDnd "BLN";
BA_ "VNSigAllNodes" SG_ 500 DrvSelMd6ReqDnd 1;
BA_ "GenSigSendType" SG_ 500 DrvSelMd6ReqDnd 10;
BA_ "SignalLongName" SG_ 500 DrvSelMd5Stat "Driver Selected Mode 5 Status";
BA_ "SignalType" SG_ 500 DrvSelMd5Stat "ENM";
BA_ "VNSigAllNodes" SG_ 500 DrvSelMd5Stat 1;
BA_ "GenSigSendType" SG_ 500 DrvSelMd5Stat 10;
BA_ "SignalLongName" SG_ 500 DrvSelMd5ReqDnd "Driver Selected Mode 5 Request Denied";
BA_ "SignalType" SG_ 500 DrvSelMd5ReqDnd "BLN";
BA_ "VNSigAllNodes" SG_ 500 DrvSelMd5ReqDnd 1;
BA_ "GenSigSendType" SG_ 500 DrvSelMd5ReqDnd 10;
BA_ "SignalLongName" SG_ 500 DrvSelMd4Stat "Driver Selected Mode 4 Status";
BA_ "SignalType" SG_ 500 DrvSelMd4Stat "ENM";
BA_ "VNSigAllNodes" SG_ 500 DrvSelMd4Stat 1;
BA_ "GenSigSendType" SG_ 500 DrvSelMd4Stat 10;
BA_ "SignalLongName" SG_ 500 DrvSelMd4ReqDnd "Driver Selected Mode 4 Request Denied";
BA_ "SignalType" SG_ 500 DrvSelMd4ReqDnd "BLN";
BA_ "VNSigAllNodes" SG_ 500 DrvSelMd4ReqDnd 1;
BA_ "GenSigSendType" SG_ 500 DrvSelMd4ReqDnd 10;
BA_ "SignalLongName" SG_ 500 DrvSelMd3Stat "Driver Selected Mode 3 Status";
BA_ "SignalType" SG_ 500 DrvSelMd3Stat "ENM";
BA_ "VNSigAllNodes" SG_ 500 DrvSelMd3Stat 1;
BA_ "GenSigSendType" SG_ 500 DrvSelMd3Stat 10;
BA_ "GenSigSendOnInit" SG_ 500 DrvSelMd3Stat 1;
BA_ "SignalLongName" SG_ 500 DrvSelMd3ReqDnd "Driver Selected Mode 3 Request Denied";
BA_ "SignalType" SG_ 500 DrvSelMd3ReqDnd "BLN";
BA_ "VNSigAllNodes" SG_ 500 DrvSelMd3ReqDnd 1;
BA_ "GenSigSendType" SG_ 500 DrvSelMd3ReqDnd 10;
BA_ "SignalLongName" SG_ 500 DrvSelMd2Stat "Driver Selected Mode 2 Status";
BA_ "SignalType" SG_ 500 DrvSelMd2Stat "ENM";
BA_ "VNSigAllNodes" SG_ 500 DrvSelMd2Stat 1;
BA_ "GenSigSendType" SG_ 500 DrvSelMd2Stat 10;
BA_ "GenSigSendOnInit" SG_ 500 DrvSelMd2Stat 1;
BA_ "SignalLongName" SG_ 500 DrvSelMd2ReqDnd "Driver Selected Mode 2 Request Denied";
BA_ "SignalType" SG_ 500 DrvSelMd2ReqDnd "BLN";
BA_ "VNSigAllNodes" SG_ 500 DrvSelMd2ReqDnd 1;
BA_ "GenSigSendType" SG_ 500 DrvSelMd2ReqDnd 10;
BA_ "SignalLongName" SG_ 500 DSMSS_DrvSelMd0Pn "Driver Selected Mode Selection Status : Driver Selected Mode 0 Pending";
BA_ "PacketOrder" SG_ 500 DSMSS_DrvSelMd0Pn 17;
BA_ "SignalType" SG_ 500 DSMSS_DrvSelMd0Pn "BLN";
BA_ "VNSigAllNodes" SG_ 500 DSMSS_DrvSelMd0Pn 1;
BA_ "GenSigSendType" SG_ 500 DSMSS_DrvSelMd0Pn 10;
BA_ "GenSigSendOnInit" SG_ 500 DSMSS_DrvSelMd0Pn 1;
BA_ "SignalLongName" SG_ 500 DSMSS_DrvSelMd8Pn "Driver Selected Mode Selection Status : Driver Selected Mode 8 Pending";
BA_ "PacketOrder" SG_ 500 DSMSS_DrvSelMd8Pn 16;
BA_ "SignalType" SG_ 500 DSMSS_DrvSelMd8Pn "BLN";
BA_ "VNSigAllNodes" SG_ 500 DSMSS_DrvSelMd8Pn 1;
BA_ "GenSigSendType" SG_ 500 DSMSS_DrvSelMd8Pn 10;
BA_ "GenSigSendOnInit" SG_ 500 DSMSS_DrvSelMd8Pn 1;
BA_ "SignalLongName" SG_ 500 DSMSS_DrvSelMd7Pn "Driver Selected Mode Selection Status : Driver Selected Mode 7 Pending";
BA_ "PacketOrder" SG_ 500 DSMSS_DrvSelMd7Pn 15;
BA_ "SignalType" SG_ 500 DSMSS_DrvSelMd7Pn "BLN";
BA_ "VNSigAllNodes" SG_ 500 DSMSS_DrvSelMd7Pn 1;
BA_ "GenSigSendType" SG_ 500 DSMSS_DrvSelMd7Pn 10;
BA_ "GenSigSendOnInit" SG_ 500 DSMSS_DrvSelMd7Pn 1;
BA_ "SignalLongName" SG_ 500 DSMSS_DrvSelMd6Pn "Driver Selected Mode Selection Status : Driver Selected Mode 6 Pending";
BA_ "PacketOrder" SG_ 500 DSMSS_DrvSelMd6Pn 14;
BA_ "SignalType" SG_ 500 DSMSS_DrvSelMd6Pn "BLN";
BA_ "VNSigAllNodes" SG_ 500 DSMSS_DrvSelMd6Pn 1;
BA_ "GenSigSendType" SG_ 500 DSMSS_DrvSelMd6Pn 10;
BA_ "GenSigSendOnInit" SG_ 500 DSMSS_DrvSelMd6Pn 1;
BA_ "SignalLongName" SG_ 500 DSMSS_DrvSelMd5Pn "Driver Selected Mode Selection Status : Driver Selected Mode 5 Pending";
BA_ "PacketOrder" SG_ 500 DSMSS_DrvSelMd5Pn 13;
BA_ "SignalType" SG_ 500 DSMSS_DrvSelMd5Pn "BLN";
BA_ "VNSigAllNodes" SG_ 500 DSMSS_DrvSelMd5Pn 1;
BA_ "GenSigSendType" SG_ 500 DSMSS_DrvSelMd5Pn 10;
BA_ "GenSigSendOnInit" SG_ 500 DSMSS_DrvSelMd5Pn 1;
BA_ "SignalLongName" SG_ 500 DSMSS_DrvSelMd4Pn "Driver Selected Mode Selection Status : Driver Selected Mode 4 Pending";
BA_ "PacketOrder" SG_ 500 DSMSS_DrvSelMd4Pn 12;
BA_ "SignalType" SG_ 500 DSMSS_DrvSelMd4Pn "BLN";
BA_ "VNSigAllNodes" SG_ 500 DSMSS_DrvSelMd4Pn 1;
BA_ "GenSigSendType" SG_ 500 DSMSS_DrvSelMd4Pn 10;
BA_ "GenSigSendOnInit" SG_ 500 DSMSS_DrvSelMd4Pn 1;
BA_ "SignalLongName" SG_ 500 DSMSS_DrvSelMd3Pn "Driver Selected Mode Selection Status : Driver Selected Mode 3 Pending";
BA_ "PacketOrder" SG_ 500 DSMSS_DrvSelMd3Pn 11;
BA_ "SignalType" SG_ 500 DSMSS_DrvSelMd3Pn "BLN";
BA_ "VNSigAllNodes" SG_ 500 DSMSS_DrvSelMd3Pn 1;
BA_ "GenSigSendType" SG_ 500 DSMSS_DrvSelMd3Pn 10;
BA_ "GenSigSendOnInit" SG_ 500 DSMSS_DrvSelMd3Pn 1;
BA_ "SignalLongName" SG_ 500 DSMSS_DrvSelMd2Pn "Driver Selected Mode Selection Status : Driver Selected Mode 2 Pending";
BA_ "PacketOrder" SG_ 500 DSMSS_DrvSelMd2Pn 10;
BA_ "SignalType" SG_ 500 DSMSS_DrvSelMd2Pn "BLN";
BA_ "VNSigAllNodes" SG_ 500 DSMSS_DrvSelMd2Pn 1;
BA_ "GenSigSendType" SG_ 500 DSMSS_DrvSelMd2Pn 10;
BA_ "GenSigSendOnInit" SG_ 500 DSMSS_DrvSelMd2Pn 1;
BA_ "SignalLongName" SG_ 500 DSMSS_DrvSelMd1Pn "Driver Selected Mode Selection Status : Driver Selected Mode 1 Pending";
BA_ "PacketOrder" SG_ 500 DSMSS_DrvSelMd1Pn 9;
BA_ "SignalType" SG_ 500 DSMSS_DrvSelMd1Pn "BLN";
BA_ "VNSigAllNodes" SG_ 500 DSMSS_DrvSelMd1Pn 1;
BA_ "GenSigSendType" SG_ 500 DSMSS_DrvSelMd1Pn 10;
BA_ "GenSigSendOnInit" SG_ 500 DSMSS_DrvSelMd1Pn 1;
BA_ "SignalLongName" SG_ 500 DSMSS_DrvSelMd8Un "Driver Selected Mode Selection Status : Driver Selected Mode 8 Unavailable";
BA_ "PacketOrder" SG_ 500 DSMSS_DrvSelMd8Un 8;
BA_ "SignalType" SG_ 500 DSMSS_DrvSelMd8Un "BLN";
BA_ "VNSigAllNodes" SG_ 500 DSMSS_DrvSelMd8Un 1;
BA_ "GenSigSendType" SG_ 500 DSMSS_DrvSelMd8Un 10;
BA_ "GenSigSendOnInit" SG_ 500 DSMSS_DrvSelMd8Un 1;
BA_ "SignalLongName" SG_ 500 DSMSS_DrvSelMd7Un "Driver Selected Mode Selection Status : Driver Selected Mode 7 Unavailable";
BA_ "PacketOrder" SG_ 500 DSMSS_DrvSelMd7Un 7;
BA_ "SignalType" SG_ 500 DSMSS_DrvSelMd7Un "BLN";
BA_ "VNSigAllNodes" SG_ 500 DSMSS_DrvSelMd7Un 1;
BA_ "GenSigSendType" SG_ 500 DSMSS_DrvSelMd7Un 10;
BA_ "GenSigSendOnInit" SG_ 500 DSMSS_DrvSelMd7Un 1;
BA_ "SignalLongName" SG_ 500 DSMSS_DrvSelMd6Un "Driver Selected Mode Selection Status : Driver Selected Mode 6 Unavailable";
BA_ "PacketOrder" SG_ 500 DSMSS_DrvSelMd6Un 6;
BA_ "SignalType" SG_ 500 DSMSS_DrvSelMd6Un "BLN";
BA_ "VNSigAllNodes" SG_ 500 DSMSS_DrvSelMd6Un 1;
BA_ "GenSigSendType" SG_ 500 DSMSS_DrvSelMd6Un 10;
BA_ "GenSigSendOnInit" SG_ 500 DSMSS_DrvSelMd6Un 1;
BA_ "SignalLongName" SG_ 500 DSMSS_DrvSelMd5Un "Driver Selected Mode Selection Status : Driver Selected Mode 5 Unavailable";
BA_ "PacketOrder" SG_ 500 DSMSS_DrvSelMd5Un 5;
BA_ "SignalType" SG_ 500 DSMSS_DrvSelMd5Un "BLN";
BA_ "VNSigAllNodes" SG_ 500 DSMSS_DrvSelMd5Un 1;
BA_ "GenSigSendType" SG_ 500 DSMSS_DrvSelMd5Un 10;
BA_ "GenSigSendOnInit" SG_ 500 DSMSS_DrvSelMd5Un 1;
BA_ "SignalLongName" SG_ 500 DSMSS_DrvSelMd4Un "Driver Selected Mode Selection Status : Driver Selected Mode 4 Unavailable";
BA_ "PacketOrder" SG_ 500 DSMSS_DrvSelMd4Un 4;
BA_ "SignalType" SG_ 500 DSMSS_DrvSelMd4Un "BLN";
BA_ "VNSigAllNodes" SG_ 500 DSMSS_DrvSelMd4Un 1;
BA_ "GenSigSendType" SG_ 500 DSMSS_DrvSelMd4Un 10;
BA_ "GenSigSendOnInit" SG_ 500 DSMSS_DrvSelMd4Un 1;
BA_ "SignalLongName" SG_ 500 DSMSS_DrvSelMd3Un "Driver Selected Mode Selection Status : Driver Selected Mode 3 Unavailable";
BA_ "PacketOrder" SG_ 500 DSMSS_DrvSelMd3Un 3;
BA_ "SignalType" SG_ 500 DSMSS_DrvSelMd3Un "BLN";
BA_ "VNSigAllNodes" SG_ 500 DSMSS_DrvSelMd3Un 1;
BA_ "GenSigSendType" SG_ 500 DSMSS_DrvSelMd3Un 10;
BA_ "GenSigSendOnInit" SG_ 500 DSMSS_DrvSelMd3Un 1;
BA_ "SignalLongName" SG_ 500 DSMSS_DrvSelMd2Un "Driver Selected Mode Selection Status : Driver Selected Mode 2 Unavailable";
BA_ "PacketOrder" SG_ 500 DSMSS_DrvSelMd2Un 2;
BA_ "SignalType" SG_ 500 DSMSS_DrvSelMd2Un "BLN";
BA_ "VNSigAllNodes" SG_ 500 DSMSS_DrvSelMd2Un 1;
BA_ "GenSigSendType" SG_ 500 DSMSS_DrvSelMd2Un 10;
BA_ "GenSigSendOnInit" SG_ 500 DSMSS_DrvSelMd2Un 1;
BA_ "SignalLongName" SG_ 500 DSMSS_DrvSelMd1Un "Driver Selected Mode Selection Status : Driver Selected Mode 1 Unavailable";
BA_ "PacketOrder" SG_ 500 DSMSS_DrvSelMd1Un 1;
BA_ "SignalType" SG_ 500 DSMSS_DrvSelMd1Un "BLN";
BA_ "VNSigAllNodes" SG_ 500 DSMSS_DrvSelMd1Un 1;
BA_ "GenSigSendType" SG_ 500 DSMSS_DrvSelMd1Un 10;
BA_ "GenSigSendOnInit" SG_ 500 DSMSS_DrvSelMd1Un 1;
BA_ "SignalLongName" SG_ 500 DrvSelMd1ReqDnd "Driver Selected Mode 1 Request Denied";
BA_ "SignalType" SG_ 500 DrvSelMd1ReqDnd "BLN";
BA_ "VNSigAllNodes" SG_ 500 DrvSelMd1ReqDnd 1;
BA_ "GenSigSendType" SG_ 500 DrvSelMd1ReqDnd 10;
BA_ "SignalLongName" SG_ 500 DrvSelMd1Stat "Driver Selected Mode 1 Status";
BA_ "SignalType" SG_ 500 DrvSelMd1Stat "ENM";
BA_ "VNSigAllNodes" SG_ 500 DrvSelMd1Stat 1;
BA_ "GenSigSendType" SG_ 500 DrvSelMd1Stat 10;
BA_ "GenSigSendOnInit" SG_ 500 DrvSelMd1Stat 1;
BA_ "SignalLongName" SG_ 407 TransActlRngStPVal "Transmission Actual Range Status Protection Value";
BA_ "SignalType" SG_ 407 TransActlRngStPVal "UNM";
BA_ "VNSigAllNodes" SG_ 407 TransActlRngStPVal 1;
BA_ "SignalLongName" SG_ 407 TransActlRngStARC "Transmission Actual Range Status Alive Rolling Count";
BA_ "SignalType" SG_ 407 TransActlRngStARC "UNM";
BA_ "VNSigAllNodes" SG_ 407 TransActlRngStARC 1;
BA_ "SignalLongName" SG_ 407 TransStCrwlMdOvrrd "Transmission State Crawl Mode Override";
BA_ "SignalType" SG_ 407 TransStCrwlMdOvrrd "ENM";
BA_ "VNSigAllNodes" SG_ 407 TransStCrwlMdOvrrd 1;
BA_ "SignalLongName" SG_ 407 TrnsEgdPrFlwInfPVal "Transmission Engaged Powerflow Information Protection Value";
BA_ "SignalType" SG_ 407 TrnsEgdPrFlwInfPVal "UNM";
BA_ "VNSigAllNodes" SG_ 407 TrnsEgdPrFlwInfPVal 1;
BA_ "SignalLongName" SG_ 407 TrnsEgdPrFlwInfARC "Transmission Engaged Powerflow Information Alive Rolling Count";
BA_ "SignalType" SG_ 407 TrnsEgdPrFlwInfARC "UNM";
BA_ "VNSigAllNodes" SG_ 407 TrnsEgdPrFlwInfARC 1;
BA_ "SignalLongName" SG_ 407 TEPI_TrnsEngdPrFlwStV "Transmission Engaged Powerflow Information : Transmission Engaged Powerflow State Validity";
BA_ "PacketOrder" SG_ 407 TEPI_TrnsEngdPrFlwStV 2;
BA_ "SignalType" SG_ 407 TEPI_TrnsEngdPrFlwStV "ENM";
BA_ "VNSigAllNodes" SG_ 407 TEPI_TrnsEngdPrFlwStV 1;
BA_ "SignalLongName" SG_ 407 TEPI_TrnsEngdPrFlwSt "Transmission Engaged Powerflow Information : Transmission Engaged Powerflow State";
BA_ "PacketOrder" SG_ 407 TEPI_TrnsEngdPrFlwSt 1;
BA_ "SignalType" SG_ 407 TEPI_TrnsEngdPrFlwSt "ENM";
BA_ "VNSigAllNodes" SG_ 407 TEPI_TrnsEngdPrFlwSt 1;
BA_ "SignalLongName" SG_ 407 TransRatioV "Transmission Ratio Validity";
BA_ "SignalType" SG_ 407 TransRatioV "ENM";
BA_ "VNSigAllNodes" SG_ 407 TransRatioV 1;
BA_ "SignalLongName" SG_ 407 TransRatio "Transmission Ratio";
BA_ "SignalType" SG_ 407 TransRatio "UNM";
BA_ "VNSigAllNodes" SG_ 407 TransRatio 1;
BA_ "SignalLongName" SG_ 407 TrnsOvrallActTorqRatioV "Transmission Overall Actual Torque Ratio Validity";
BA_ "SignalType" SG_ 407 TrnsOvrallActTorqRatioV "ENM";
BA_ "VNSigAllNodes" SG_ 407 TrnsOvrallActTorqRatioV 1;
BA_ "SignalLongName" SG_ 407 TrnsOvrallActTorqRatio "Transmission Overall Actual Torque Ratio";
BA_ "SignalType" SG_ 407 TrnsOvrallActTorqRatio "SNM";
BA_ "VNSigAllNodes" SG_ 407 TrnsOvrallActTorqRatio 1;
BA_ "SignalLongName" SG_ 407 TARS_TransActRngV "Transmission Actual Range Status : Transmission Actual Range Validity";
BA_ "PacketOrder" SG_ 407 TARS_TransActRngV 3;
BA_ "SignalType" SG_ 407 TARS_TransActRngV "ENM";
BA_ "VNSigAllNodes" SG_ 407 TARS_TransActRngV 1;
BA_ "SignalLongName" SG_ 407 TARS_TransActRngM "Transmission Actual Range Status : Transmission Actual Range Mask";
BA_ "PacketOrder" SG_ 407 TARS_TransActRngM 2;
BA_ "SignalType" SG_ 407 TARS_TransActRngM "ENM";
BA_ "VNSigAllNodes" SG_ 407 TARS_TransActRngM 1;
BA_ "SignalLongName" SG_ 407 TARS_TransActRng "Transmission Actual Range Status : Transmission Actual Range";
BA_ "PacketOrder" SG_ 407 TARS_TransActRng 1;
BA_ "SignalType" SG_ 407 TARS_TransActRng "ENM";
BA_ "VNSigAllNodes" SG_ 407 TARS_TransActRng 1;
BA_ "SignalLongName" SG_ 979 PlatEngSpdCmdStPVal "Platform Engine Speed Command Status Protection Value";
BA_ "SignalType" SG_ 979 PlatEngSpdCmdStPVal "UNM";
BA_ "VNSigAllNodes" SG_ 979 PlatEngSpdCmdStPVal 1;
BA_ "SignalLongName" SG_ 979 PlatEngSpdCmdStARC "Platform Engine Speed Command Status Alive Rolling Count";
BA_ "SignalType" SG_ 979 PlatEngSpdCmdStARC "UNM";
BA_ "VNSigAllNodes" SG_ 979 PlatEngSpdCmdStARC 1;
BA_ "SignalLongName" SG_ 979 PltfrmEngSpdCmmndSt "Platform Engine Speed Command Status";
BA_ "SignalType" SG_ 979 PltfrmEngSpdCmmndSt "ENM";
BA_ "VNSigAllNodes" SG_ 979 PltfrmEngSpdCmmndSt 1;
BA_ "SignalLongName" SG_ 979 PTABR_AccReq "Powertrain Automatic Braking Request : Acceleration Request";
BA_ "PacketOrder" SG_ 979 PTABR_AccReq 2;
BA_ "SignalType" SG_ 979 PTABR_AccReq "SNM";
BA_ "VNSigAllNodes" SG_ 979 PTABR_AccReq 1;
BA_ "SignalLongName" SG_ 979 PTABR_PTBrkRqAct "Powertrain Automatic Braking Request : Powertrain Brake Request Active";
BA_ "PacketOrder" SG_ 979 PTABR_PTBrkRqAct 1;
BA_ "SignalType" SG_ 979 PTABR_PTBrkRqAct "BLN";
BA_ "VNSigAllNodes" SG_ 979 PTABR_PTBrkRqAct 1;
BA_ "SignalLongName" SG_ 979 PTAutoBrkReqPVal "Powertrain Automatic Braking Request Protection Value";
BA_ "SignalType" SG_ 979 PTAutoBrkReqPVal "UNM";
BA_ "VNSigAllNodes" SG_ 979 PTAutoBrkReqPVal 1;
BA_ "SignalLongName" SG_ 979 PTAutoBrkReqARC "Powertrain Automatic Braking Request Alive Rolling Count";
BA_ "SignalType" SG_ 979 PTAutoBrkReqARC "UNM";
BA_ "VNSigAllNodes" SG_ 979 PTAutoBrkReqARC 1;
BA_ "SignalLongName" SG_ 979 BrkBstVacV "Brake Boost Vacuum Validity";
BA_ "SignalType" SG_ 979 BrkBstVacV "ENM";
BA_ "VNSigAllNodes" SG_ 979 BrkBstVacV 1;
BA_ "SignalLongName" SG_ 979 BrkBstVac "Brake Boost Vacuum";
BA_ "SignalType" SG_ 979 BrkBstVac "UNM";
BA_ "VNSigAllNodes" SG_ 979 BrkBstVac 1;
BA_ "SignalLongName" SG_ 979 RegVltCtlEngyRcvryAct "Regulated Voltage Control Energy Recovery Active";
BA_ "SignalType" SG_ 979 RegVltCtlEngyRcvryAct "BLN";
BA_ "VNSigAllNodes" SG_ 979 RegVltCtlEngyRcvryAct 1;
BA_ "GenSigSendType" SG_ 979 RegVltCtlEngyRcvryAct 10;
BA_ "SignalLongName" SG_ 979 SpdLmtrSttngTypAct "Speed Limiter Setting Type Active";
BA_ "SignalType" SG_ 979 SpdLmtrSttngTypAct "ENM";
BA_ "VNSigAllNodes" SG_ 979 SpdLmtrSttngTypAct 1;
BA_ "GenSigSendType" SG_ 979 SpdLmtrSttngTypAct 10;
BA_ "SignalLongName" SG_ 979 SetSpdLmtRchd "Set Speed Limit Reached";
BA_ "SignalType" SG_ 979 SetSpdLmtRchd "ENM";
BA_ "VNSigAllNodes" SG_ 979 SetSpdLmtRchd 1;
BA_ "SignalLongName" SG_ 979 ElvtdIdlCstCrStVal "Elevated Idle Customization Current Setting Value";
BA_ "SignalType" SG_ 979 ElvtdIdlCstCrStVal "ENM";
BA_ "VNSigAllNodes" SG_ 979 ElvtdIdlCstCrStVal 1;
BA_ "SignalLongName" SG_ 979 ElvtdIdlCstStAvl "Elevated Idle Customization Setting Available";
BA_ "SignalType" SG_ 979 ElvtdIdlCstStAvl "BLN";
BA_ "VNSigAllNodes" SG_ 979 ElvtdIdlCstStAvl 1;
BA_ "SignalLongName" SG_ 979 EngManfldAirTempCrtdV "Engine Manifold Air Temperature Corrected Validity";
BA_ "SignalType" SG_ 979 EngManfldAirTempCrtdV "ENM";
BA_ "VNSigAllNodes" SG_ 979 EngManfldAirTempCrtdV 1;
BA_ "SignalLongName" SG_ 979 EngManfldAirTempCrtd "Engine Manifold Air Temperature Corrected";
BA_ "SignalType" SG_ 979 EngManfldAirTempCrtd "UNM";
BA_ "VNSigAllNodes" SG_ 979 EngManfldAirTempCrtd 1;
BA_ "SignalLongName" SG_ 368 EnvIdRspSt5 "Environment Identification Response Status 5";
BA_ "SignalType" SG_ 368 EnvIdRspSt5 "ENM";
BA_ "VNSigAllNodes" SG_ 368 EnvIdRspSt5 1;
BA_ "SignalLongName" SG_ 368 EnvIdRsp5 "Environment Identification Response 5";
BA_ "SignalType" SG_ 368 EnvIdRsp5 "UNM";
BA_ "VNSigAllNodes" SG_ 368 EnvIdRsp5 1;
BA_ "SignalLongName" SG_ 1187 EngInltCltTmpV "Engine Inlet Coolant Temperature Validity";
BA_ "SignalType" SG_ 1187 EngInltCltTmpV "ENM";
BA_ "VNSigAllNodes" SG_ 1187 EngInltCltTmpV 1;
BA_ "SignalLongName" SG_ 1187 EngInltCltTmp "Engine Inlet Coolant Temperature";
BA_ "SignalType" SG_ 1187 EngInltCltTmp "UNM";
BA_ "VNSigAllNodes" SG_ 1187 EngInltCltTmp 1;
BA_ "SignalLongName" SG_ 1187 CbnHtrWrmUpReqARC "Cabin Heater Warm Up Request Alive Rolling Count";
BA_ "SignalType" SG_ 1187 CbnHtrWrmUpReqARC "UNM";
BA_ "VNSigAllNodes" SG_ 1187 CbnHtrWrmUpReqARC 1;
BA_ "SignalLongName" SG_ 1187 CbnHtrWrmUpReq "Cabin Heater Warm Up Request";
BA_ "SignalType" SG_ 1187 CbnHtrWrmUpReq "ENM";
BA_ "VNSigAllNodes" SG_ 1187 CbnHtrWrmUpReq 1;
BA_ "SignalLongName" SG_ 1187 VehGrdSnsrBsdV "Vehicle Grade Sensor Based Validity";
BA_ "SignalType" SG_ 1187 VehGrdSnsrBsdV "ENM";
BA_ "VNSigAllNodes" SG_ 1187 VehGrdSnsrBsdV 1;
BA_ "SignalLongName" SG_ 1187 VehGrdSnsrBsd "Vehicle Grade Sensor Based";
BA_ "SignalType" SG_ 1187 VehGrdSnsrBsd "SNM";
BA_ "VNSigAllNodes" SG_ 1187 VehGrdSnsrBsd 1;
BA_ "SignalLongName" SG_ 1187 UndrHdAirFlwCap "Under Hood Air Flow Capacity";
BA_ "SignalType" SG_ 1187 UndrHdAirFlwCap "UNM";
BA_ "VNSigAllNodes" SG_ 1187 UndrHdAirFlwCap 1;
BA_ "SignalLongName" SG_ 1187 UndrHdAirFlwActPrcnt "Under Hood Air Flow Actual Percent";
BA_ "SignalType" SG_ 1187 UndrHdAirFlwActPrcnt "UNM";
BA_ "VNSigAllNodes" SG_ 1187 UndrHdAirFlwActPrcnt 1;
BA_ "SignalLongName" SG_ 1187 CbnHtrWrmUpIO "Cabin Heater Warm Up Indication On";
BA_ "SignalType" SG_ 1187 CbnHtrWrmUpIO "BLN";
BA_ "VNSigAllNodes" SG_ 1187 CbnHtrWrmUpIO 1;
BA_ "SignalLongName" SG_ 566 RdDCChrgCntctrStat "Redundant DC Charge Contactor Status";
BA_ "SignalType" SG_ 566 RdDCChrgCntctrStat "ENM";
BA_ "VNSigAllNodes" SG_ 566 RdDCChrgCntctrStat 1;
BA_ "SignalLongName" SG_ 566 RdHVBatHtrCntctrStat "Redundant High Voltage Battery Heater Contactor Status";
BA_ "SignalType" SG_ 566 RdHVBatHtrCntctrStat "ENM";
BA_ "VNSigAllNodes" SG_ 566 RdHVBatHtrCntctrStat 1;
BA_ "SignalLongName" SG_ 566 RHVBCCS_InvtrCaptrChrgAct "Redundant High Voltage Battery Connect Command Status : Inverter Capacitor Charging Active";
BA_ "PacketOrder" SG_ 566 RHVBCCS_InvtrCaptrChrgAct 4;
BA_ "SignalType" SG_ 566 RHVBCCS_InvtrCaptrChrgAct "BLN";
BA_ "VNSigAllNodes" SG_ 566 RHVBCCS_InvtrCaptrChrgAct 1;
BA_ "SignalLongName" SG_ 566 RHVBCCS_DCChrgrCntCmd "Redundant High Voltage Battery Connect Command Status : DC Charger Connect Commanded";
BA_ "PacketOrder" SG_ 566 RHVBCCS_DCChrgrCntCmd 3;
BA_ "SignalType" SG_ 566 RHVBCCS_DCChrgrCntCmd "BLN";
BA_ "VNSigAllNodes" SG_ 566 RHVBCCS_DCChrgrCntCmd 1;
BA_ "SignalLongName" SG_ 566 RHVBCCS_InvtrCntCmd "Redundant High Voltage Battery Connect Command Status : Inverter Connect Commanded";
BA_ "PacketOrder" SG_ 566 RHVBCCS_InvtrCntCmd 2;
BA_ "SignalType" SG_ 566 RHVBCCS_InvtrCntCmd "BLN";
BA_ "VNSigAllNodes" SG_ 566 RHVBCCS_InvtrCntCmd 1;
BA_ "SignalLongName" SG_ 566 RHVBCCS_ACChrgrCntCmd "Redundant High Voltage Battery Connect Command Status : AC Charger Connect Commanded";
BA_ "PacketOrder" SG_ 566 RHVBCCS_ACChrgrCntCmd 1;
BA_ "SignalType" SG_ 566 RHVBCCS_ACChrgrCntCmd "BLN";
BA_ "VNSigAllNodes" SG_ 566 RHVBCCS_ACChrgrCntCmd 1;
BA_ "SignalLongName" SG_ 566 RdHVCntctrShdwnCmd "Redundant High Voltage Contactor Shutdown Command";
BA_ "SignalType" SG_ 566 RdHVCntctrShdwnCmd "ENM";
BA_ "VNSigAllNodes" SG_ 566 RdHVCntctrShdwnCmd 1;
BA_ "SignalLongName" SG_ 566 ChrgSysShftPrkReqPval "Charging System Shift To Park Requested Protection Value";
BA_ "SignalType" SG_ 566 ChrgSysShftPrkReqPval "UNM";
BA_ "VNSigAllNodes" SG_ 566 ChrgSysShftPrkReqPval 1;
BA_ "SignalLongName" SG_ 566 ChrgSysShftPrkReqARC "Charging System Shift To Park Requested Alive Rolling Count";
BA_ "SignalType" SG_ 566 ChrgSysShftPrkReqARC "UNM";
BA_ "VNSigAllNodes" SG_ 566 ChrgSysShftPrkReqARC 1;
BA_ "SignalLongName" SG_ 566 ChrgSysShftPrkReq "Charging System Shift To Park Requested";
BA_ "SignalType" SG_ 566 ChrgSysShftPrkReq "BLN";
BA_ "VNSigAllNodes" SG_ 566 ChrgSysShftPrkReq 1;
BA_ "SignalLongName" SG_ 566 HVBatChrgCrdAlrtReq "High Voltage Battery Charge Cord Alert Request";
BA_ "SignalType" SG_ 566 HVBatChrgCrdAlrtReq "ENM";
BA_ "VNSigAllNodes" SG_ 566 HVBatChrgCrdAlrtReq 1;
BA_ "GenSigSendType" SG_ 566 HVBatChrgCrdAlrtReq 10;
BA_ "SignalLongName" SG_ 566 RdHVBatLwParMdReq "Redundant High Voltage Battery Low Parasitic Mode Requested";
BA_ "SignalType" SG_ 566 RdHVBatLwParMdReq "BLN";
BA_ "VNSigAllNodes" SG_ 566 RdHVBatLwParMdReq 1;
BA_ "SignalLongName" SG_ 566 RdHVBtClOVFFTstRq "Redundant High Voltage Battery Cell Over Voltage Fault Flag Test Req";
BA_ "SignalType" SG_ 566 RdHVBtClOVFFTstRq "BLN";
BA_ "VNSigAllNodes" SG_ 566 RdHVBtClOVFFTstRq 1;
BA_ "SignalLongName" SG_ 566 RdHVBtClOVFFTstIdx "Redundant High Voltage Battery Cell Over Voltage Fault Flag Test Index";
BA_ "SignalType" SG_ 566 RdHVBtClOVFFTstIdx "UNM";
BA_ "VNSigAllNodes" SG_ 566 RdHVBtClOVFFTstIdx 1;
BA_ "SignalLongName" SG_ 566 ClimCtrlHVDvcShtdwnCmd "Climate Control High Voltage Device Shutdown Commanded";
BA_ "SignalType" SG_ 566 ClimCtrlHVDvcShtdwnCmd "BLN";
BA_ "VNSigAllNodes" SG_ 566 ClimCtrlHVDvcShtdwnCmd 1;
BA_ "GenSigDeltaValue" SG_ 566 ClimCtrlHVDvcShtdwnCmd 1;
BA_ "GenSigSendType" SG_ 566 ClimCtrlHVDvcShtdwnCmd 10;
BA_ "GenSigSendOnInit" SG_ 566 ClimCtrlHVDvcShtdwnCmd 1;
BA_ "SignalLongName" SG_ 566 ThrmlRefCompSpdReqARC "Thermal Refrigerant Compressor Speed Request Alive Rolling Count";
BA_ "SignalType" SG_ 566 ThrmlRefCompSpdReqARC "UNM";
BA_ "VNSigAllNodes" SG_ 566 ThrmlRefCompSpdReqARC 1;
BA_ "SignalLongName" SG_ 566 VICMHVEnMgCmEnTrS "VICM High Voltage Energy Management Comm Enable Terminal Status";
BA_ "SignalType" SG_ 566 VICMHVEnMgCmEnTrS "ENM";
BA_ "VNSigAllNodes" SG_ 566 VICMHVEnMgCmEnTrS 1;
BA_ "SignalLongName" SG_ 566 ChrgSysPrkBrkAnmsBrkReqPVal "Charging System Park Brake Autonomous Apply Request Protection Value";
BA_ "SignalType" SG_ 566 ChrgSysPrkBrkAnmsBrkReqPVal "UNM";
BA_ "VNSigAllNodes" SG_ 566 ChrgSysPrkBrkAnmsBrkReqPVal 1;
BA_ "SignalLongName" SG_ 566 ChrgSysPrkBrkAnmsBrkReqARC "Charging System Park Brake Autonomous Apply Request Alive Rolling Count";
BA_ "SignalType" SG_ 566 ChrgSysPrkBrkAnmsBrkReqARC "UNM";
BA_ "VNSigAllNodes" SG_ 566 ChrgSysPrkBrkAnmsBrkReqARC 1;
BA_ "SignalLongName" SG_ 566 ChrgSysPrkBrkAnmsBrkReq "Charging System Park Brake Autonomous Apply Request";
BA_ "SignalType" SG_ 566 ChrgSysPrkBrkAnmsBrkReq "BLN";
BA_ "VNSigAllNodes" SG_ 566 ChrgSysPrkBrkAnmsBrkReq 1;
BA_ "SignalLongName" SG_ 566 HybVehHiVltSysDisbld_236 "Hybrid Vehicle High Voltage System Disabled";
BA_ "SignalType" SG_ 566 HybVehHiVltSysDisbld_236 "BLN";
BA_ "VNSigAllNodes" SG_ 566 HybVehHiVltSysDisbld_236 1;
BA_ "SignalLongName" SG_ 566 ThrmlRefCompSpdReq "Thermal Refrigerant Compressor Speed Request";
BA_ "SignalType" SG_ 566 ThrmlRefCompSpdReq "UNM";
BA_ "VNSigAllNodes" SG_ 566 ThrmlRefCompSpdReq 1;
BA_ "SignalLongName" SG_ 566 ChrgSysAudblIndRq "Charging System Audible Indication Request";
BA_ "SignalType" SG_ 566 ChrgSysAudblIndRq "ENM";
BA_ "VNSigAllNodes" SG_ 566 ChrgSysAudblIndRq 1;
BA_ "SignalLongName" SG_ 817 RrAxlELSDCplLwResV "Rear Axle Electronic Limited Slip Differential Coupling Low Resolution Validity";
BA_ "SignalType" SG_ 817 RrAxlELSDCplLwResV "ENM";
BA_ "VNSigAllNodes" SG_ 817 RrAxlELSDCplLwResV 1;
BA_ "SignalLongName" SG_ 817 RrAxlELSDCplLwRes "Rear Axle Electronic Limited Slip Differential Coupling Low Resolution";
BA_ "SignalType" SG_ 817 RrAxlELSDCplLwRes "UNM";
BA_ "VNSigAllNodes" SG_ 817 RrAxlELSDCplLwRes 1;
BA_ "SignalLongName" SG_ 817 RrDrvlnSysVehTpSpdLmVal "Rear Driveline System Vehicle Top Speed Limit Value";
BA_ "SignalType" SG_ 817 RrDrvlnSysVehTpSpdLmVal "UNM";
BA_ "VNSigAllNodes" SG_ 817 RrDrvlnSysVehTpSpdLmVal 1;
BA_ "SignalLongName" SG_ 817 RrAxlTmpInhIO "Rear Axle Temporary Inhibit Indication On";
BA_ "SignalType" SG_ 817 RrAxlTmpInhIO "BLN";
BA_ "VNSigAllNodes" SG_ 817 RrAxlTmpInhIO 1;
BA_ "SignalLongName" SG_ 817 RrAxlMalfIO "Rear Axle Malfunction Indication On";
BA_ "SignalType" SG_ 817 RrAxlMalfIO "BLN";
BA_ "VNSigAllNodes" SG_ 817 RrAxlMalfIO 1;
BA_REL_ "GenSigTimeoutTime" BU_SG_REL_ TCM_HS SG_ 503 ElcTransRngRq 250;
BA_REL_ "GenSigTimeoutMsg" BU_SG_REL_ TCM_HS SG_ 503 ElcTransRngRq 503;
BA_REL_ "GenSigSuprvResp" BU_SG_REL_ TCM_HS SG_ 503 ElcTransRngRq 1;
BA_REL_ "GenSigTimeoutTime" BU_SG_REL_ RDCM_HS SG_ 503 ElcTransRngRq 250;
BA_REL_ "GenSigTimeoutMsg" BU_SG_REL_ RDCM_HS SG_ 503 ElcTransRngRq 503;
BA_REL_ "GenSigSuprvResp" BU_SG_REL_ RDCM_HS SG_ 503 ElcTransRngRq 1;
BA_REL_ "GenSigTimeoutTime" BU_SG_REL_ BCM_HS SG_ 503 ElcTransRngRq 250;
BA_REL_ "GenSigTimeoutMsg" BU_SG_REL_ BCM_HS SG_ 503 ElcTransRngRq 503;
BA_REL_ "GenSigSuprvResp" BU_SG_REL_ BCM_HS SG_ 503 ElcTransRngRq 1;
BA_REL_ "GenSigTimeoutTime" BU_SG_REL_ BCM_HS SG_ 353 ElcShfPriTwoGrsSlInRq 250;
BA_REL_ "GenSigTimeoutMsg" BU_SG_REL_ BCM_HS SG_ 353 ElcShfPriTwoGrsSlInRq 353;
BA_REL_ "GenSigSuprvResp" BU_SG_REL_ BCM_HS SG_ 353 ElcShfPriTwoGrsSlInRq 1;
BA_REL_ "GenSigTimeoutTime" BU_SG_REL_ BCM_HS SG_ 353 ElctShfPriLtdPerfMdIO 250;
BA_REL_ "GenSigTimeoutMsg" BU_SG_REL_ BCM_HS SG_ 353 ElctShfPriLtdPerfMdIO 353;
BA_REL_ "GenSigSuprvResp" BU_SG_REL_ BCM_HS SG_ 353 ElctShfPriLtdPerfMdIO 1;
BA_REL_ "GenSigTimeoutTime" BU_SG_REL_ BCM_HS SG_ 353 ElecShfRngDispRCExtd 250;
BA_REL_ "GenSigTimeoutMsg" BU_SG_REL_ BCM_HS SG_ 353 ElecShfRngDispRCExtd 353;
BA_REL_ "GenSigSuprvResp" BU_SG_REL_ BCM_HS SG_ 353 ElecShfRngDispRCExtd 1;
BA_REL_ "GenSigTimeoutTime" BU_SG_REL_ BCM_HS SG_ 353 ElecShfRngDisp 250;
BA_REL_ "GenSigTimeoutMsg" BU_SG_REL_ BCM_HS SG_ 353 ElecShfRngDisp 353;
BA_REL_ "GenSigSuprvResp" BU_SG_REL_ BCM_HS SG_ 353 ElecShfRngDisp 1;
BA_REL_ "GenSigTimeoutTime" BU_SG_REL_ BCM_HS SG_ 353 ESPTransMalfIO 250;
BA_REL_ "GenSigTimeoutMsg" BU_SG_REL_ BCM_HS SG_ 353 ESPTransMalfIO 353;
BA_REL_ "GenSigSuprvResp" BU_SG_REL_ BCM_HS SG_ 353 ESPTransMalfIO 1;
BA_REL_ "GenSigTimeoutTime" BU_SG_REL_ BCM_HS SG_ 353 ESPRngInvldReqIO 250;
BA_REL_ "GenSigTimeoutMsg" BU_SG_REL_ BCM_HS SG_ 353 ESPRngInvldReqIO 353;
BA_REL_ "GenSigSuprvResp" BU_SG_REL_ BCM_HS SG_ 353 ESPRngInvldReqIO 1;
BA_REL_ "GenSigTimeoutTime" BU_SG_REL_ BCM_HS SG_ 353 ESPPrkInvldReqIO 250;
BA_REL_ "GenSigTimeoutMsg" BU_SG_REL_ BCM_HS SG_ 353 ESPPrkInvldReqIO 353;
BA_REL_ "GenSigSuprvResp" BU_SG_REL_ BCM_HS SG_ 353 ESPPrkInvldReqIO 1;
BA_REL_ "GenSigTimeoutTime" BU_SG_REL_ BCM_HS SG_ 353 ESPHldShfLvrToEngRgIO 250;
BA_REL_ "GenSigTimeoutMsg" BU_SG_REL_ BCM_HS SG_ 353 ESPHldShfLvrToEngRgIO 353;
BA_REL_ "GenSigSuprvResp" BU_SG_REL_ BCM_HS SG_ 353 ESPHldShfLvrToEngRgIO 1;
BA_REL_ "GenSigTimeoutTime" BU_SG_REL_ BCM_HS SG_ 353 ESPDrvrPrkIlkSftAtdIO 250;
BA_REL_ "GenSigTimeoutMsg" BU_SG_REL_ BCM_HS SG_ 353 ESPDrvrPrkIlkSftAtdIO 353;
BA_REL_ "GenSigSuprvResp" BU_SG_REL_ BCM_HS SG_ 353 ESPDrvrPrkIlkSftAtdIO 1;
BA_REL_ "GenSigTimeoutTime" BU_SG_REL_ BCM_HS SG_ 353 ESPDrvrIlkShfAtdIO 250;
BA_REL_ "GenSigTimeoutMsg" BU_SG_REL_ BCM_HS SG_ 353 ESPDrvrIlkShfAtdIO 353;
BA_REL_ "GenSigSuprvResp" BU_SG_REL_ BCM_HS SG_ 353 ESPDrvrIlkShfAtdIO 1;
BA_REL_ "GenSigTimeoutMsg" BU_SG_REL_ BCM_HS SG_ 1271 BatSvrMdLvl7Act 1271;
BA_REL_ "GenSigSuprvResp" BU_SG_REL_ BCM_HS SG_ 1271 BatSvrMdLvl7Act 1;
BA_REL_ "GenSigTimeoutMsg" BU_SG_REL_ BCM_HS SG_ 1271 BatSvrMdNetAmpHr 1271;
BA_REL_ "GenSigSuprvResp" BU_SG_REL_ BCM_HS SG_ 1271 BatSvrMdNetAmpHr 1;
BA_REL_ "GenSigTimeoutMsg" BU_SG_REL_ BCM_HS SG_ 1271 BatSvrMdWkUpCtr 1271;
BA_REL_ "GenSigSuprvResp" BU_SG_REL_ BCM_HS SG_ 1271 BatSvrMdWkUpCtr 1;
BA_REL_ "GenSigTimeoutMsg" BU_SG_REL_ BCM_HS SG_ 1271 BSMCT_RawVal 1271;
BA_REL_ "GenSigSuprvResp" BU_SG_REL_ BCM_HS SG_ 1271 BSMCT_RawVal 1;
BA_REL_ "GenSigTimeoutMsg" BU_SG_REL_ BCM_HS SG_ 1271 BSMCT_Mult 1271;
BA_REL_ "GenSigSuprvResp" BU_SG_REL_ BCM_HS SG_ 1271 BSMCT_Mult 1;
BA_REL_ "GenSigTimeoutMsg" BU_SG_REL_ BCM_HS SG_ 1271 BatSvrMdVltTrg 1271;
BA_REL_ "GenSigSuprvResp" BU_SG_REL_ BCM_HS SG_ 1271 BatSvrMdVltTrg 1;
BA_REL_ "GenSigTimeoutMsg" BU_SG_REL_ BCM_HS SG_ 1271 BatSvrMdLvl6Act 1271;
BA_REL_ "GenSigSuprvResp" BU_SG_REL_ BCM_HS SG_ 1271 BatSvrMdLvl6Act 1;
BA_REL_ "GenSigTimeoutMsg" BU_SG_REL_ BCM_HS SG_ 1271 BatSvrMdLvl5Act 1271;
BA_REL_ "GenSigSuprvResp" BU_SG_REL_ BCM_HS SG_ 1271 BatSvrMdLvl5Act 1;
BA_REL_ "GenSigTimeoutMsg" BU_SG_REL_ BCM_HS SG_ 1271 BatSvrMdLvl4Act 1271;
BA_REL_ "GenSigSuprvResp" BU_SG_REL_ BCM_HS SG_ 1271 BatSvrMdLvl4Act 1;
BA_REL_ "GenSigTimeoutTime" BU_SG_REL_ BCM_HS SG_ 1263 BatSOFVolt 2500;
BA_REL_ "GenSigTimeoutMsg" BU_SG_REL_ BCM_HS SG_ 1263 BatSOFVolt 1263;
BA_REL_ "GenSigSuprvResp" BU_SG_REL_ BCM_HS SG_ 1263 BatSOFVolt 1;
BA_REL_ "GenSigTimeoutTime" BU_SG_REL_ BCM_HS SG_ 1263 BatSOH 2500;
BA_REL_ "GenSigTimeoutMsg" BU_SG_REL_ BCM_HS SG_ 1263 BatSOH 1263;
BA_REL_ "GenSigSuprvResp" BU_SG_REL_ BCM_HS SG_ 1263 BatSOH 1;
BA_REL_ "GenSigTimeoutTime" BU_SG_REL_ BCM_HS SG_ 1263 IBSBatSOC 2500;
BA_REL_ "GenSigTimeoutMsg" BU_SG_REL_ BCM_HS SG_ 1263 IBSBatSOC 1263;
BA_REL_ "GenSigSuprvResp" BU_SG_REL_ BCM_HS SG_ 1263 IBSBatSOC 1;
BA_REL_ "GenSigTimeoutTime" BU_SG_REL_ BCM_HS SG_ 1263 BattSOXStat 2500;
BA_REL_ "GenSigTimeoutMsg" BU_SG_REL_ BCM_HS SG_ 1263 BattSOXStat 1263;
BA_REL_ "GenSigSuprvResp" BU_SG_REL_ BCM_HS SG_ 1263 BattSOXStat 1;
BA_REL_ "GenSigTimeoutTime" BU_SG_REL_ BCM_HS SG_ 1261 MinCrnkCrnt 2500;
BA_REL_ "GenSigTimeoutMsg" BU_SG_REL_ BCM_HS SG_ 1261 MinCrnkCrnt 1261;
BA_REL_ "GenSigSuprvResp" BU_SG_REL_ BCM_HS SG_ 1261 MinCrnkCrnt 1;
BA_REL_ "GenSigTimeoutTime" BU_SG_REL_ BCM_HS SG_ 1261 MinCrnkVlt 2500;
BA_REL_ "GenSigTimeoutMsg" BU_SG_REL_ BCM_HS SG_ 1261 MinCrnkVlt 1261;
BA_REL_ "GenSigSuprvResp" BU_SG_REL_ BCM_HS SG_ 1261 MinCrnkVlt 1;
BA_REL_ "GenSigTimeoutTime" BU_SG_REL_ BCM_HS SG_ 1261 BattTemp 2500;
BA_REL_ "GenSigTimeoutMsg" BU_SG_REL_ BCM_HS SG_ 1261 BattTemp 1261;
BA_REL_ "GenSigSuprvResp" BU_SG_REL_ BCM_HS SG_ 1261 BattTemp 1;
BA_REL_ "GenSigTimeoutTime" BU_SG_REL_ BCM_HS SG_ 1259 AllNodesVNA 1250;
BA_REL_ "GenSigTimeoutMsg" BU_SG_REL_ BCM_HS SG_ 1259 AllNodesVNA 1259;
BA_REL_ "GenSigSuprvResp" BU_SG_REL_ BCM_HS SG_ 1259 AllNodesVNA 1;
BA_REL_ "GenSigTimeoutTime" BU_SG_REL_ BCM_HS SG_ 1259 NAHrDisChrg 1250;
BA_REL_ "GenSigTimeoutMsg" BU_SG_REL_ BCM_HS SG_ 1259 NAHrDisChrg 1259;
BA_REL_ "GenSigSuprvResp" BU_SG_REL_ BCM_HS SG_ 1259 NAHrDisChrg 1;
BA_REL_ "GenSigTimeoutTime" BU_SG_REL_ BCM_HS SG_ 1259 NAHrChg 1250;
BA_REL_ "GenSigTimeoutMsg" BU_SG_REL_ BCM_HS SG_ 1259 NAHrChg 1259;
BA_REL_ "GenSigSuprvResp" BU_SG_REL_ BCM_HS SG_ 1259 NAHrChg 1;
BA_REL_ "GenSigTimeoutTime" BU_SG_REL_ CGM_HS SG_ 844 IMUProtYawRt 250;
BA_REL_ "GenSigTimeoutMsg" BU_SG_REL_ CGM_HS SG_ 844 IMUProtYawRt 844;
BA_REL_ "GenSigSuprvResp" BU_SG_REL_ CGM_HS SG_ 844 IMUProtYawRt 1;
BA_REL_ "GenSigTimeoutTime" BU_SG_REL_ EPS_HS SG_ 844 IMUProtYawRt 250;
BA_REL_ "GenSigTimeoutMsg" BU_SG_REL_ EPS_HS SG_ 844 IMUProtYawRt 844;
BA_REL_ "GenSigSuprvResp" BU_SG_REL_ EPS_HS SG_ 844 IMUProtYawRt 1;
BA_REL_ "GenSigTimeoutTime" BU_SG_REL_ CGM_HS SG_ 844 IMUProtLatAcc 250;
BA_REL_ "GenSigTimeoutMsg" BU_SG_REL_ CGM_HS SG_ 844 IMUProtLatAcc 844;
BA_REL_ "GenSigSuprvResp" BU_SG_REL_ CGM_HS SG_ 844 IMUProtLatAcc 1;
BA_REL_ "GenSigTimeoutTime" BU_SG_REL_ EPS_HS SG_ 844 IMUProtLatAcc 250;
BA_REL_ "GenSigTimeoutMsg" BU_SG_REL_ EPS_HS SG_ 844 IMUProtLatAcc 844;
BA_REL_ "GenSigSuprvResp" BU_SG_REL_ EPS_HS SG_ 844 IMUProtLatAcc 1;
BA_REL_ "GenSigTimeoutTime" BU_SG_REL_ EPS_HS SG_ 844 IMUProtChksum 250;
BA_REL_ "GenSigTimeoutMsg" BU_SG_REL_ EPS_HS SG_ 844 IMUProtChksum 844;
BA_REL_ "GenSigSuprvResp" BU_SG_REL_ EPS_HS SG_ 844 IMUProtChksum 1;
BA_REL_ "GenSigTimeoutTime" BU_SG_REL_ EPS_HS SG_ 844 IMUProtARC 250;
BA_REL_ "GenSigTimeoutMsg" BU_SG_REL_ EPS_HS SG_ 844 IMUProtARC 844;
BA_REL_ "GenSigSuprvResp" BU_SG_REL_ EPS_HS SG_ 844 IMUProtARC 1;
BA_REL_ "GenSigTimeoutTime" BU_SG_REL_ CGM_HS SG_ 844 StrAngSnsPolRat 250;
BA_REL_ "GenSigTimeoutMsg" BU_SG_REL_ CGM_HS SG_ 844 StrAngSnsPolRat 844;
BA_REL_ "GenSigSuprvResp" BU_SG_REL_ CGM_HS SG_ 844 StrAngSnsPolRat 1;
BA_REL_ "GenSigTimeoutTime" BU_SG_REL_ EPS_HS SG_ 844 StrAngSnsPolRat 250;
BA_REL_ "GenSigTimeoutMsg" BU_SG_REL_ EPS_HS SG_ 844 StrAngSnsPolRat 844;
BA_REL_ "GenSigSuprvResp" BU_SG_REL_ EPS_HS SG_ 844 StrAngSnsPolRat 1;
BA_REL_ "GenSigTimeoutTime" BU_SG_REL_ CGM_HS SG_ 844 IMUProtLonAcc 250;
BA_REL_ "GenSigTimeoutMsg" BU_SG_REL_ CGM_HS SG_ 844 IMUProtLonAcc 844;
BA_REL_ "GenSigSuprvResp" BU_SG_REL_ CGM_HS SG_ 844 IMUProtLonAcc 1;
BA_REL_ "GenSigTimeoutTime" BU_SG_REL_ EPS_HS SG_ 844 IMUProtLonAcc 250;
BA_REL_ "GenSigTimeoutMsg" BU_SG_REL_ EPS_HS SG_ 844 IMUProtLonAcc 844;
BA_REL_ "GenSigSuprvResp" BU_SG_REL_ EPS_HS SG_ 844 IMUProtLonAcc 1;
BA_REL_ "GenSigTimeoutTime" BU_SG_REL_ RDCM_HS SG_ 844 IMUProtLonAcc 250;
BA_REL_ "GenSigTimeoutMsg" BU_SG_REL_ RDCM_HS SG_ 844 IMUProtLonAcc 844;
BA_REL_ "GenSigSuprvResp" BU_SG_REL_ RDCM_HS SG_ 844 IMUProtLonAcc 1;
BA_REL_ "GenSigTimeoutTime" BU_SG_REL_ ECM_HS SG_ 844 IMUProtLonAcc 250;
BA_REL_ "GenSigTimeoutMsg" BU_SG_REL_ ECM_HS SG_ 844 IMUProtLonAcc 844;
BA_REL_ "GenSigSuprvResp" BU_SG_REL_ ECM_HS SG_ 844 IMUProtLonAcc 1;
BA_REL_ "GenSigTimeoutTime" BU_SG_REL_ ECM_HS SG_ 806 DCCnvStblznErrIO 1250;
BA_REL_ "GenSigTimeoutMsg" BU_SG_REL_ ECM_HS SG_ 806 DCCnvStblznErrIO 806;
BA_REL_ "GenSigSuprvResp" BU_SG_REL_ ECM_HS SG_ 806 DCCnvStblznErrIO 1;
BA_REL_ "GenSigTimeoutTime" BU_SG_REL_ BCM_HS SG_ 806 DCCnvStblznErrIO 1250;
BA_REL_ "GenSigTimeoutMsg" BU_SG_REL_ BCM_HS SG_ 806 DCCnvStblznErrIO 806;
BA_REL_ "GenSigSuprvResp" BU_SG_REL_ BCM_HS SG_ 806 DCCnvStblznErrIO 1;
BA_REL_ "GenSigTimeoutTime" BU_SG_REL_ BCM_HS SG_ 1231 DslExhFluidDistTIndcmt 2500;
BA_REL_ "GenSigTimeoutMsg" BU_SG_REL_ BCM_HS SG_ 1231 DslExhFluidDistTIndcmt 1231;
BA_REL_ "GenSigSuprvResp" BU_SG_REL_ BCM_HS SG_ 1231 DslExhFluidDistTIndcmt 1;
BA_REL_ "GenSigTimeoutTime" BU_SG_REL_ BCM_HS SG_ 1231 DslExhFluidLvlPrcnt 2500;
BA_REL_ "GenSigTimeoutMsg" BU_SG_REL_ BCM_HS SG_ 1231 DslExhFluidLvlPrcnt 1231;
BA_REL_ "GenSigSuprvResp" BU_SG_REL_ BCM_HS SG_ 1231 DslExhFluidLvlPrcnt 1;
BA_REL_ "GenSigTimeoutTime" BU_SG_REL_ BCM_HS SG_ 563 SPMCA_SusPrfMd6Avl 5000;
BA_REL_ "GenSigTimeoutMsg" BU_SG_REL_ BCM_HS SG_ 563 SPMCA_SusPrfMd6Avl 563;
BA_REL_ "GenSigSuprvResp" BU_SG_REL_ BCM_HS SG_ 563 SPMCA_SusPrfMd6Avl 1;
BA_REL_ "GenSigTimeoutTime" BU_SG_REL_ BCM_HS SG_ 563 SPMCA_SusPrfMd5Avl 5000;
BA_REL_ "GenSigTimeoutMsg" BU_SG_REL_ BCM_HS SG_ 563 SPMCA_SusPrfMd5Avl 563;
BA_REL_ "GenSigSuprvResp" BU_SG_REL_ BCM_HS SG_ 563 SPMCA_SusPrfMd5Avl 1;
BA_REL_ "GenSigTimeoutTime" BU_SG_REL_ BCM_HS SG_ 563 SPMCA_SusPrfMd4Avl 5000;
BA_REL_ "GenSigTimeoutMsg" BU_SG_REL_ BCM_HS SG_ 563 SPMCA_SusPrfMd4Avl 563;
BA_REL_ "GenSigSuprvResp" BU_SG_REL_ BCM_HS SG_ 563 SPMCA_SusPrfMd4Avl 1;
BA_REL_ "GenSigTimeoutTime" BU_SG_REL_ BCM_HS SG_ 563 SPMCA_SusPrfMd3Avl 5000;
BA_REL_ "GenSigTimeoutMsg" BU_SG_REL_ BCM_HS SG_ 563 SPMCA_SusPrfMd3Avl 563;
BA_REL_ "GenSigSuprvResp" BU_SG_REL_ BCM_HS SG_ 563 SPMCA_SusPrfMd3Avl 1;
BA_REL_ "GenSigTimeoutTime" BU_SG_REL_ BCM_HS SG_ 563 SPMCA_SusPrfMd2Avl 5000;
BA_REL_ "GenSigTimeoutMsg" BU_SG_REL_ BCM_HS SG_ 563 SPMCA_SusPrfMd2Avl 563;
BA_REL_ "GenSigSuprvResp" BU_SG_REL_ BCM_HS SG_ 563 SPMCA_SusPrfMd2Avl 1;
BA_REL_ "GenSigTimeoutTime" BU_SG_REL_ BCM_HS SG_ 563 SPMCA_SusPrfMd1Avl 5000;
BA_REL_ "GenSigTimeoutMsg" BU_SG_REL_ BCM_HS SG_ 563 SPMCA_SusPrfMd1Avl 563;
BA_REL_ "GenSigSuprvResp" BU_SG_REL_ BCM_HS SG_ 563 SPMCA_SusPrfMd1Avl 1;
BA_REL_ "GenSigTimeoutTime" BU_SG_REL_ BCM_HS SG_ 563 SPMCA_StrPrfMd6Avl 5000;
BA_REL_ "GenSigTimeoutMsg" BU_SG_REL_ BCM_HS SG_ 563 SPMCA_StrPrfMd6Avl 563;
BA_REL_ "GenSigSuprvResp" BU_SG_REL_ BCM_HS SG_ 563 SPMCA_StrPrfMd6Avl 1;
BA_REL_ "GenSigTimeoutTime" BU_SG_REL_ BCM_HS SG_ 563 SPMCA_StrPrfMd5Avl 5000;
BA_REL_ "GenSigTimeoutMsg" BU_SG_REL_ BCM_HS SG_ 563 SPMCA_StrPrfMd5Avl 563;
BA_REL_ "GenSigSuprvResp" BU_SG_REL_ BCM_HS SG_ 563 SPMCA_StrPrfMd5Avl 1;
BA_REL_ "GenSigTimeoutTime" BU_SG_REL_ BCM_HS SG_ 563 SPMCA_StrPrfMd4Avl 5000;
BA_REL_ "GenSigTimeoutMsg" BU_SG_REL_ BCM_HS SG_ 563 SPMCA_StrPrfMd4Avl 563;
BA_REL_ "GenSigSuprvResp" BU_SG_REL_ BCM_HS SG_ 563 SPMCA_StrPrfMd4Avl 1;
BA_REL_ "GenSigTimeoutTime" BU_SG_REL_ BCM_HS SG_ 563 SPMCA_StrPrfMd3Avl 5000;
BA_REL_ "GenSigTimeoutMsg" BU_SG_REL_ BCM_HS SG_ 563 SPMCA_StrPrfMd3Avl 563;
BA_REL_ "GenSigSuprvResp" BU_SG_REL_ BCM_HS SG_ 563 SPMCA_StrPrfMd3Avl 1;
BA_REL_ "GenSigTimeoutTime" BU_SG_REL_ BCM_HS SG_ 563 SPMCA_StrPrfMd2Avl 5000;
BA_REL_ "GenSigTimeoutMsg" BU_SG_REL_ BCM_HS SG_ 563 SPMCA_StrPrfMd2Avl 563;
BA_REL_ "GenSigSuprvResp" BU_SG_REL_ BCM_HS SG_ 563 SPMCA_StrPrfMd2Avl 1;
BA_REL_ "GenSigTimeoutTime" BU_SG_REL_ BCM_HS SG_ 563 SPMCA_StrPrfMd1Avl 5000;
BA_REL_ "GenSigTimeoutMsg" BU_SG_REL_ BCM_HS SG_ 563 SPMCA_StrPrfMd1Avl 563;
BA_REL_ "GenSigSuprvResp" BU_SG_REL_ BCM_HS SG_ 563 SPMCA_StrPrfMd1Avl 1;
BA_REL_ "GenSigTimeoutTime" BU_SG_REL_ BCM_HS SG_ 563 SPMCA_SndPrfMd6Avl 5000;
BA_REL_ "GenSigTimeoutMsg" BU_SG_REL_ BCM_HS SG_ 563 SPMCA_SndPrfMd6Avl 563;
BA_REL_ "GenSigSuprvResp" BU_SG_REL_ BCM_HS SG_ 563 SPMCA_SndPrfMd6Avl 1;
BA_REL_ "GenSigTimeoutTime" BU_SG_REL_ BCM_HS SG_ 563 SPMCA_SndPrfMd5Avl 5000;
BA_REL_ "GenSigTimeoutMsg" BU_SG_REL_ BCM_HS SG_ 563 SPMCA_SndPrfMd5Avl 563;
BA_REL_ "GenSigSuprvResp" BU_SG_REL_ BCM_HS SG_ 563 SPMCA_SndPrfMd5Avl 1;
BA_REL_ "GenSigTimeoutTime" BU_SG_REL_ BCM_HS SG_ 563 SPMCA_SndPrfMd4Avl 5000;
BA_REL_ "GenSigTimeoutMsg" BU_SG_REL_ BCM_HS SG_ 563 SPMCA_SndPrfMd4Avl 563;
BA_REL_ "GenSigSuprvResp" BU_SG_REL_ BCM_HS SG_ 563 SPMCA_SndPrfMd4Avl 1;
BA_REL_ "GenSigTimeoutTime" BU_SG_REL_ BCM_HS SG_ 563 SPMCA_SndPrfMd3Avl 5000;
BA_REL_ "GenSigTimeoutMsg" BU_SG_REL_ BCM_HS SG_ 563 SPMCA_SndPrfMd3Avl 563;
BA_REL_ "GenSigSuprvResp" BU_SG_REL_ BCM_HS SG_ 563 SPMCA_SndPrfMd3Avl 1;
BA_REL_ "GenSigTimeoutTime" BU_SG_REL_ BCM_HS SG_ 563 SPMCA_SndPrfMd2Avl 5000;
BA_REL_ "GenSigTimeoutMsg" BU_SG_REL_ BCM_HS SG_ 563 SPMCA_SndPrfMd2Avl 563;
BA_REL_ "GenSigSuprvResp" BU_SG_REL_ BCM_HS SG_ 563 SPMCA_SndPrfMd2Avl 1;
BA_REL_ "GenSigTimeoutTime" BU_SG_REL_ BCM_HS SG_ 563 SPMCA_SndPrfMd1Avl 5000;
BA_REL_ "GenSigTimeoutMsg" BU_SG_REL_ BCM_HS SG_ 563 SPMCA_SndPrfMd1Avl 563;
BA_REL_ "GenSigSuprvResp" BU_SG_REL_ BCM_HS SG_ 563 SPMCA_SndPrfMd1Avl 1;
BA_REL_ "GenSigTimeoutTime" BU_SG_REL_ BCM_HS SG_ 563 DPMCA_DispPrfMd6Avl 5000;
BA_REL_ "GenSigTimeoutMsg" BU_SG_REL_ BCM_HS SG_ 563 DPMCA_DispPrfMd6Avl 563;
BA_REL_ "GenSigSuprvResp" BU_SG_REL_ BCM_HS SG_ 563 DPMCA_DispPrfMd6Avl 1;
BA_REL_ "GenSigTimeoutTime" BU_SG_REL_ BCM_HS SG_ 563 DPMCA_DispPrfMd5Avl 5000;
BA_REL_ "GenSigTimeoutMsg" BU_SG_REL_ BCM_HS SG_ 563 DPMCA_DispPrfMd5Avl 563;
BA_REL_ "GenSigSuprvResp" BU_SG_REL_ BCM_HS SG_ 563 DPMCA_DispPrfMd5Avl 1;
BA_REL_ "GenSigTimeoutTime" BU_SG_REL_ BCM_HS SG_ 563 DPMCA_DispPrfMd4Avl 5000;
BA_REL_ "GenSigTimeoutMsg" BU_SG_REL_ BCM_HS SG_ 563 DPMCA_DispPrfMd4Avl 563;
BA_REL_ "GenSigSuprvResp" BU_SG_REL_ BCM_HS SG_ 563 DPMCA_DispPrfMd4Avl 1;
BA_REL_ "GenSigTimeoutTime" BU_SG_REL_ BCM_HS SG_ 563 DPMCA_DispPrfMd3Avl 5000;
BA_REL_ "GenSigTimeoutMsg" BU_SG_REL_ BCM_HS SG_ 563 DPMCA_DispPrfMd3Avl 563;
BA_REL_ "GenSigSuprvResp" BU_SG_REL_ BCM_HS SG_ 563 DPMCA_DispPrfMd3Avl 1;
BA_REL_ "GenSigTimeoutTime" BU_SG_REL_ BCM_HS SG_ 563 DPMCA_DispPrfMd2Avl 5000;
BA_REL_ "GenSigTimeoutMsg" BU_SG_REL_ BCM_HS SG_ 563 DPMCA_DispPrfMd2Avl 563;
BA_REL_ "GenSigSuprvResp" BU_SG_REL_ BCM_HS SG_ 563 DPMCA_DispPrfMd2Avl 1;
BA_REL_ "GenSigTimeoutTime" BU_SG_REL_ BCM_HS SG_ 563 DPMCA_DispPrfMd1Avl 5000;
BA_REL_ "GenSigTimeoutMsg" BU_SG_REL_ BCM_HS SG_ 563 DPMCA_DispPrfMd1Avl 563;
BA_REL_ "GenSigSuprvResp" BU_SG_REL_ BCM_HS SG_ 563 DPMCA_DispPrfMd1Avl 1;
BA_REL_ "GenSigTimeoutTime" BU_SG_REL_ BCM_HS SG_ 563 DPMCA_DrvlPrfMd6Avl 5000;
BA_REL_ "GenSigTimeoutMsg" BU_SG_REL_ BCM_HS SG_ 563 DPMCA_DrvlPrfMd6Avl 563;
BA_REL_ "GenSigSuprvResp" BU_SG_REL_ BCM_HS SG_ 563 DPMCA_DrvlPrfMd6Avl 1;
BA_REL_ "GenSigTimeoutTime" BU_SG_REL_ BCM_HS SG_ 563 DPMCA_DrvlPrfMd5Avl 5000;
BA_REL_ "GenSigTimeoutMsg" BU_SG_REL_ BCM_HS SG_ 563 DPMCA_DrvlPrfMd5Avl 563;
BA_REL_ "GenSigSuprvResp" BU_SG_REL_ BCM_HS SG_ 563 DPMCA_DrvlPrfMd5Avl 1;
BA_REL_ "GenSigTimeoutTime" BU_SG_REL_ BCM_HS SG_ 563 DPMCA_DrvlPrfMd4Avl 5000;
BA_REL_ "GenSigTimeoutMsg" BU_SG_REL_ BCM_HS SG_ 563 DPMCA_DrvlPrfMd4Avl 563;
BA_REL_ "GenSigSuprvResp" BU_SG_REL_ BCM_HS SG_ 563 DPMCA_DrvlPrfMd4Avl 1;
BA_REL_ "GenSigTimeoutTime" BU_SG_REL_ BCM_HS SG_ 563 DPMCA_DrvlPrfMd3Avl 5000;
BA_REL_ "GenSigTimeoutMsg" BU_SG_REL_ BCM_HS SG_ 563 DPMCA_DrvlPrfMd3Avl 563;
BA_REL_ "GenSigSuprvResp" BU_SG_REL_ BCM_HS SG_ 563 DPMCA_DrvlPrfMd3Avl 1;
BA_REL_ "GenSigTimeoutTime" BU_SG_REL_ BCM_HS SG_ 563 DPMCA_DrvlPrfMd2Avl 5000;
BA_REL_ "GenSigTimeoutMsg" BU_SG_REL_ BCM_HS SG_ 563 DPMCA_DrvlPrfMd2Avl 563;
BA_REL_ "GenSigSuprvResp" BU_SG_REL_ BCM_HS SG_ 563 DPMCA_DrvlPrfMd2Avl 1;
BA_REL_ "GenSigTimeoutTime" BU_SG_REL_ BCM_HS SG_ 563 DPMCA_DrvlPrfMd1Avl 5000;
BA_REL_ "GenSigTimeoutMsg" BU_SG_REL_ BCM_HS SG_ 563 DPMCA_DrvlPrfMd1Avl 563;
BA_REL_ "GenSigSuprvResp" BU_SG_REL_ BCM_HS SG_ 563 DPMCA_DrvlPrfMd1Avl 1;
BA_REL_ "GenSigTimeoutTime" BU_SG_REL_ EBCM_HS SG_ 723 PerfTrcEngSpdRqStat 500;
BA_REL_ "GenSigTimeoutMsg" BU_SG_REL_ EBCM_HS SG_ 723 PerfTrcEngSpdRqStat 723;
BA_REL_ "GenSigSuprvResp" BU_SG_REL_ EBCM_HS SG_ 723 PerfTrcEngSpdRqStat 1;
BA_REL_ "GenSigTimeoutTime" BU_SG_REL_ EBCM_HS SG_ 723 PerfTrcEngSpdLmtStat 500;
BA_REL_ "GenSigTimeoutMsg" BU_SG_REL_ EBCM_HS SG_ 723 PerfTrcEngSpdLmtStat 723;
BA_REL_ "GenSigSuprvResp" BU_SG_REL_ EBCM_HS SG_ 723 PerfTrcEngSpdLmtStat 1;
BA_REL_ "GenSigTimeoutTime" BU_SG_REL_ EBCM_HS SG_ 723 PerfTrcTrqRqStat 500;
BA_REL_ "GenSigTimeoutMsg" BU_SG_REL_ EBCM_HS SG_ 723 PerfTrcTrqRqStat 723;
BA_REL_ "GenSigSuprvResp" BU_SG_REL_ EBCM_HS SG_ 723 PerfTrcTrqRqStat 1;
BA_REL_ "GenSigTimeoutTime" BU_SG_REL_ EBCM_HS SG_ 723 PerfTrcTrqLmtStat 500;
BA_REL_ "GenSigTimeoutMsg" BU_SG_REL_ EBCM_HS SG_ 723 PerfTrcTrqLmtStat 723;
BA_REL_ "GenSigSuprvResp" BU_SG_REL_ EBCM_HS SG_ 723 PerfTrcTrqLmtStat 1;
BA_REL_ "GenSigTimeoutTime" BU_SG_REL_ CGM_HS SG_ 419 ClrCGMLgsDgInf 250;
BA_REL_ "GenSigTimeoutMsg" BU_SG_REL_ CGM_HS SG_ 419 ClrCGMLgsDgInf 419;
BA_REL_ "GenSigSuprvResp" BU_SG_REL_ CGM_HS SG_ 419 ClrCGMLgsDgInf 1;
BA_REL_ "GenSigTimeoutTime" BU_SG_REL_ BCM_HS SG_ 419 EngRunng 250;
BA_REL_ "GenSigTimeoutMsg" BU_SG_REL_ BCM_HS SG_ 419 EngRunng 419;
BA_REL_ "GenSigSuprvResp" BU_SG_REL_ BCM_HS SG_ 419 EngRunng 1;
BA_REL_ "GenSigTimeoutTime" BU_SG_REL_ BCM_HS SG_ 1268 EngAirFltLfRmn 2500;
BA_REL_ "GenSigTimeoutMsg" BU_SG_REL_ BCM_HS SG_ 1268 EngAirFltLfRmn 1268;
BA_REL_ "GenSigSuprvResp" BU_SG_REL_ BCM_HS SG_ 1268 EngAirFltLfRmn 1;
BA_REL_ "GenSigTimeoutTime" BU_SG_REL_ BCM_HS SG_ 1268 EngAirFltMonSt 2500;
BA_REL_ "GenSigTimeoutMsg" BU_SG_REL_ BCM_HS SG_ 1268 EngAirFltMonSt 1268;
BA_REL_ "GenSigSuprvResp" BU_SG_REL_ BCM_HS SG_ 1268 EngAirFltMonSt 1;
BA_REL_ "GenSigTimeoutTime" BU_SG_REL_ EPS_HS SG_ 384 LKATqOvrDltCmdPrtVl 250;
BA_REL_ "GenSigTimeoutMsg" BU_SG_REL_ EPS_HS SG_ 384 LKATqOvrDltCmdPrtVl 384;
BA_REL_ "GenSigSuprvResp" BU_SG_REL_ EPS_HS SG_ 384 LKATqOvrDltCmdPrtVl 1;
BA_REL_ "GenSigTimeoutTime" BU_SG_REL_ EPS_HS SG_ 384 LKATqOvrDltCmdRC 250;
BA_REL_ "GenSigTimeoutMsg" BU_SG_REL_ EPS_HS SG_ 384 LKATqOvrDltCmdRC 384;
BA_REL_ "GenSigSuprvResp" BU_SG_REL_ EPS_HS SG_ 384 LKATqOvrDltCmdRC 1;
BA_REL_ "GenSigTimeoutTime" BU_SG_REL_ EPS_HS SG_ 384 LKATODC_TrqVl 250;
BA_REL_ "GenSigTimeoutMsg" BU_SG_REL_ EPS_HS SG_ 384 LKATODC_TrqVl 384;
BA_REL_ "GenSigSuprvResp" BU_SG_REL_ EPS_HS SG_ 384 LKATODC_TrqVl 1;
BA_REL_ "GenSigTimeoutTime" BU_SG_REL_ BCM_HS SG_ 384 LKATODC_TrqVl 250;
BA_REL_ "GenSigTimeoutMsg" BU_SG_REL_ BCM_HS SG_ 384 LKATODC_TrqVl 384;
BA_REL_ "GenSigSuprvResp" BU_SG_REL_ BCM_HS SG_ 384 LKATODC_TrqVl 1;
BA_REL_ "GenSigTimeoutTime" BU_SG_REL_ EPS_HS SG_ 384 LKATODC_TrqRqAct 250;
BA_REL_ "GenSigTimeoutMsg" BU_SG_REL_ EPS_HS SG_ 384 LKATODC_TrqRqAct 384;
BA_REL_ "GenSigSuprvResp" BU_SG_REL_ EPS_HS SG_ 384 LKATODC_TrqRqAct 1;
BA_REL_ "GenSigTimeoutTime" BU_SG_REL_ BCM_HS SG_ 384 LKATODC_TrqRqAct 250;
BA_REL_ "GenSigTimeoutMsg" BU_SG_REL_ BCM_HS SG_ 384 LKATODC_TrqRqAct 384;
BA_REL_ "GenSigSuprvResp" BU_SG_REL_ BCM_HS SG_ 384 LKATODC_TrqRqAct 1;
BA_REL_ "GenSigTimeoutTime" BU_SG_REL_ BSM_HS SG_ 866 RegenBrkAxTrqAch 500;
BA_REL_ "GenSigTimeoutMsg" BU_SG_REL_ BSM_HS SG_ 866 RegenBrkAxTrqAch 866;
BA_REL_ "GenSigSuprvResp" BU_SG_REL_ BSM_HS SG_ 866 RegenBrkAxTrqAch 1;
BA_REL_ "GenSigTimeoutTime" BU_SG_REL_ EBCM_HS SG_ 479 PTAVHEnbld 250;
BA_REL_ "GenSigTimeoutMsg" BU_SG_REL_ EBCM_HS SG_ 479 PTAVHEnbld 479;
BA_REL_ "GenSigSuprvResp" BU_SG_REL_ EBCM_HS SG_ 479 PTAVHEnbld 1;
BA_REL_ "GenSigTimeoutTime" BU_SG_REL_ EBCM_HS SG_ 479 PTAVHActv 250;
BA_REL_ "GenSigTimeoutMsg" BU_SG_REL_ EBCM_HS SG_ 479 PTAVHActv 479;
BA_REL_ "GenSigSuprvResp" BU_SG_REL_ EBCM_HS SG_ 479 PTAVHActv 1;
BA_REL_ "GenSigTimeoutTime" BU_SG_REL_ CGM_HS SG_ 479 PrplsnSysAtv 250;
BA_REL_ "GenSigTimeoutMsg" BU_SG_REL_ CGM_HS SG_ 479 PrplsnSysAtv 479;
BA_REL_ "GenSigSuprvResp" BU_SG_REL_ CGM_HS SG_ 479 PrplsnSysAtv 1;
BA_REL_ "GenSigTimeoutTime" BU_SG_REL_ RDCM_HS SG_ 479 PrplsnSysAtv 250;
BA_REL_ "GenSigTimeoutMsg" BU_SG_REL_ RDCM_HS SG_ 479 PrplsnSysAtv 479;
BA_REL_ "GenSigSuprvResp" BU_SG_REL_ RDCM_HS SG_ 479 PrplsnSysAtv 1;
BA_REL_ "GenSigTimeoutTime" BU_SG_REL_ EBCM_HS SG_ 479 PrplsnSysAtv 250;
BA_REL_ "GenSigTimeoutMsg" BU_SG_REL_ EBCM_HS SG_ 479 PrplsnSysAtv 479;
BA_REL_ "GenSigSuprvResp" BU_SG_REL_ EBCM_HS SG_ 479 PrplsnSysAtv 1;
BA_REL_ "GenSigTimeoutTime" BU_SG_REL_ BSM_HS SG_ 479 PrplsnSysAtv 500;
BA_REL_ "GenSigTimeoutMsg" BU_SG_REL_ BSM_HS SG_ 479 PrplsnSysAtv 479;
BA_REL_ "GenSigSuprvResp" BU_SG_REL_ BSM_HS SG_ 479 PrplsnSysAtv 1;
BA_REL_ "GenSigTimeoutTime" BU_SG_REL_ TCM_HS SG_ 479 EngAutoStpNotProb 250;
BA_REL_ "GenSigTimeoutMsg" BU_SG_REL_ TCM_HS SG_ 479 EngAutoStpNotProb 479;
BA_REL_ "GenSigSuprvResp" BU_SG_REL_ TCM_HS SG_ 479 EngAutoStpNotProb 1;
BA_REL_ "GenSigTimeoutTime" BU_SG_REL_ ECM_HS SG_ 479 EngAutoStpNotProb 250;
BA_REL_ "GenSigTimeoutMsg" BU_SG_REL_ ECM_HS SG_ 479 EngAutoStpNotProb 479;
BA_REL_ "GenSigSuprvResp" BU_SG_REL_ ECM_HS SG_ 479 EngAutoStpNotProb 1;
BA_REL_ "GenSigTimeoutTime" BU_SG_REL_ BCM_HS SG_ 479 EngAutoStpNotProb 62;
BA_REL_ "GenSigTimeoutMsg" BU_SG_REL_ BCM_HS SG_ 479 EngAutoStpNotProb 479;
BA_REL_ "GenSigSuprvResp" BU_SG_REL_ BCM_HS SG_ 479 EngAutoStpNotProb 1;
BA_REL_ "GenSigTimeoutTime" BU_SG_REL_ TCM_HS SG_ 479 EASSI_UnsdRsrvd2 250;
BA_REL_ "GenSigTimeoutMsg" BU_SG_REL_ TCM_HS SG_ 479 EASSI_UnsdRsrvd2 479;
BA_REL_ "GenSigSuprvResp" BU_SG_REL_ TCM_HS SG_ 479 EASSI_UnsdRsrvd2 1;
BA_REL_ "GenSigTimeoutTime" BU_SG_REL_ EBCM_HS SG_ 479 EASSI_UnsdRsrvd2 250;
BA_REL_ "GenSigTimeoutMsg" BU_SG_REL_ EBCM_HS SG_ 479 EASSI_UnsdRsrvd2 479;
BA_REL_ "GenSigSuprvResp" BU_SG_REL_ EBCM_HS SG_ 479 EASSI_UnsdRsrvd2 1;
BA_REL_ "GenSigTimeoutTime" BU_SG_REL_ ECM_HS SG_ 479 EASSI_UnsdRsrvd2 250;
BA_REL_ "GenSigTimeoutMsg" BU_SG_REL_ ECM_HS SG_ 479 EASSI_UnsdRsrvd2 479;
BA_REL_ "GenSigSuprvResp" BU_SG_REL_ ECM_HS SG_ 479 EASSI_UnsdRsrvd2 1;
BA_REL_ "GenSigTimeoutTime" BU_SG_REL_ BCM_HS SG_ 479 EASSI_UnsdRsrvd2 62;
BA_REL_ "GenSigTimeoutMsg" BU_SG_REL_ BCM_HS SG_ 479 EASSI_UnsdRsrvd2 479;
BA_REL_ "GenSigSuprvResp" BU_SG_REL_ BCM_HS SG_ 479 EASSI_UnsdRsrvd2 1;
BA_REL_ "GenSigTimeoutTime" BU_SG_REL_ TCM_HS SG_ 479 EASSI_StlDetd 250;
BA_REL_ "GenSigTimeoutMsg" BU_SG_REL_ TCM_HS SG_ 479 EASSI_StlDetd 479;
BA_REL_ "GenSigSuprvResp" BU_SG_REL_ TCM_HS SG_ 479 EASSI_StlDetd 1;
BA_REL_ "GenSigTimeoutTime" BU_SG_REL_ EBCM_HS SG_ 479 EASSI_StlDetd 250;
BA_REL_ "GenSigTimeoutMsg" BU_SG_REL_ EBCM_HS SG_ 479 EASSI_StlDetd 479;
BA_REL_ "GenSigSuprvResp" BU_SG_REL_ EBCM_HS SG_ 479 EASSI_StlDetd 1;
BA_REL_ "GenSigTimeoutTime" BU_SG_REL_ ECM_HS SG_ 479 EASSI_StlDetd 250;
BA_REL_ "GenSigTimeoutMsg" BU_SG_REL_ ECM_HS SG_ 479 EASSI_StlDetd 479;
BA_REL_ "GenSigSuprvResp" BU_SG_REL_ ECM_HS SG_ 479 EASSI_StlDetd 1;
BA_REL_ "GenSigTimeoutTime" BU_SG_REL_ BCM_HS SG_ 479 EASSI_StlDetd 62;
BA_REL_ "GenSigTimeoutMsg" BU_SG_REL_ BCM_HS SG_ 479 EASSI_StlDetd 479;
BA_REL_ "GenSigSuprvResp" BU_SG_REL_ BCM_HS SG_ 479 EASSI_StlDetd 1;
BA_REL_ "GenSigTimeoutTime" BU_SG_REL_ TCM_HS SG_ 479 EASSI_TrqDetd 250;
BA_REL_ "GenSigTimeoutMsg" BU_SG_REL_ TCM_HS SG_ 479 EASSI_TrqDetd 479;
BA_REL_ "GenSigSuprvResp" BU_SG_REL_ TCM_HS SG_ 479 EASSI_TrqDetd 1;
BA_REL_ "GenSigTimeoutTime" BU_SG_REL_ EBCM_HS SG_ 479 EASSI_TrqDetd 250;
BA_REL_ "GenSigTimeoutMsg" BU_SG_REL_ EBCM_HS SG_ 479 EASSI_TrqDetd 479;
BA_REL_ "GenSigSuprvResp" BU_SG_REL_ EBCM_HS SG_ 479 EASSI_TrqDetd 1;
BA_REL_ "GenSigTimeoutTime" BU_SG_REL_ ECM_HS SG_ 479 EASSI_TrqDetd 250;
BA_REL_ "GenSigTimeoutMsg" BU_SG_REL_ ECM_HS SG_ 479 EASSI_TrqDetd 479;
BA_REL_ "GenSigSuprvResp" BU_SG_REL_ ECM_HS SG_ 479 EASSI_TrqDetd 1;
BA_REL_ "GenSigTimeoutTime" BU_SG_REL_ BCM_HS SG_ 479 EASSI_TrqDetd 62;
BA_REL_ "GenSigTimeoutMsg" BU_SG_REL_ BCM_HS SG_ 479 EASSI_TrqDetd 479;
BA_REL_ "GenSigSuprvResp" BU_SG_REL_ BCM_HS SG_ 479 EASSI_TrqDetd 1;
BA_REL_ "GenSigTimeoutTime" BU_SG_REL_ TCM_HS SG_ 479 EASSI_FuelReqOn 250;
BA_REL_ "GenSigTimeoutMsg" BU_SG_REL_ TCM_HS SG_ 479 EASSI_FuelReqOn 479;
BA_REL_ "GenSigSuprvResp" BU_SG_REL_ TCM_HS SG_ 479 EASSI_FuelReqOn 1;
BA_REL_ "GenSigTimeoutTime" BU_SG_REL_ EBCM_HS SG_ 479 EASSI_FuelReqOn 250;
BA_REL_ "GenSigTimeoutMsg" BU_SG_REL_ EBCM_HS SG_ 479 EASSI_FuelReqOn 479;
BA_REL_ "GenSigSuprvResp" BU_SG_REL_ EBCM_HS SG_ 479 EASSI_FuelReqOn 1;
BA_REL_ "GenSigTimeoutTime" BU_SG_REL_ ECM_HS SG_ 479 EASSI_FuelReqOn 250;
BA_REL_ "GenSigTimeoutMsg" BU_SG_REL_ ECM_HS SG_ 479 EASSI_FuelReqOn 479;
BA_REL_ "GenSigSuprvResp" BU_SG_REL_ ECM_HS SG_ 479 EASSI_FuelReqOn 1;
BA_REL_ "GenSigTimeoutTime" BU_SG_REL_ BCM_HS SG_ 479 EASSI_FuelReqOn 62;
BA_REL_ "GenSigTimeoutMsg" BU_SG_REL_ BCM_HS SG_ 479 EASSI_FuelReqOn 479;
BA_REL_ "GenSigSuprvResp" BU_SG_REL_ BCM_HS SG_ 479 EASSI_FuelReqOn 1;
BA_REL_ "GenSigTimeoutTime" BU_SG_REL_ TCM_HS SG_ 479 EASSI_StrtTyp 250;
BA_REL_ "GenSigTimeoutMsg" BU_SG_REL_ TCM_HS SG_ 479 EASSI_StrtTyp 479;
BA_REL_ "GenSigSuprvResp" BU_SG_REL_ TCM_HS SG_ 479 EASSI_StrtTyp 1;
BA_REL_ "GenSigTimeoutTime" BU_SG_REL_ EBCM_HS SG_ 479 EASSI_StrtTyp 250;
BA_REL_ "GenSigTimeoutMsg" BU_SG_REL_ EBCM_HS SG_ 479 EASSI_StrtTyp 479;
BA_REL_ "GenSigSuprvResp" BU_SG_REL_ EBCM_HS SG_ 479 EASSI_StrtTyp 1;
BA_REL_ "GenSigTimeoutTime" BU_SG_REL_ ECM_HS SG_ 479 EASSI_StrtTyp 250;
BA_REL_ "GenSigTimeoutMsg" BU_SG_REL_ ECM_HS SG_ 479 EASSI_StrtTyp 479;
BA_REL_ "GenSigSuprvResp" BU_SG_REL_ ECM_HS SG_ 479 EASSI_StrtTyp 1;
BA_REL_ "GenSigTimeoutTime" BU_SG_REL_ BCM_HS SG_ 479 EASSI_StrtTyp 62;
BA_REL_ "GenSigTimeoutMsg" BU_SG_REL_ BCM_HS SG_ 479 EASSI_StrtTyp 479;
BA_REL_ "GenSigSuprvResp" BU_SG_REL_ BCM_HS SG_ 479 EASSI_StrtTyp 1;
BA_REL_ "GenSigTimeoutTime" BU_SG_REL_ TCM_HS SG_ 479 EASSI_StrtStpSt 250;
BA_REL_ "GenSigTimeoutMsg" BU_SG_REL_ TCM_HS SG_ 479 EASSI_StrtStpSt 479;
BA_REL_ "GenSigSuprvResp" BU_SG_REL_ TCM_HS SG_ 479 EASSI_StrtStpSt 1;
BA_REL_ "GenSigTimeoutTime" BU_SG_REL_ ECM_HS SG_ 479 EASSI_StrtStpSt 250;
BA_REL_ "GenSigTimeoutMsg" BU_SG_REL_ ECM_HS SG_ 479 EASSI_StrtStpSt 479;
BA_REL_ "GenSigSuprvResp" BU_SG_REL_ ECM_HS SG_ 479 EASSI_StrtStpSt 1;
BA_REL_ "GenSigTimeoutTime" BU_SG_REL_ EBCM_HS SG_ 479 EASSI_StrtStpSt 250;
BA_REL_ "GenSigTimeoutMsg" BU_SG_REL_ EBCM_HS SG_ 479 EASSI_StrtStpSt 479;
BA_REL_ "GenSigSuprvResp" BU_SG_REL_ EBCM_HS SG_ 479 EASSI_StrtStpSt 1;
BA_REL_ "GenSigTimeoutTime" BU_SG_REL_ BCM_HS SG_ 479 EASSI_StrtStpSt 62;
BA_REL_ "GenSigTimeoutMsg" BU_SG_REL_ BCM_HS SG_ 479 EASSI_StrtStpSt 479;
BA_REL_ "GenSigSuprvResp" BU_SG_REL_ BCM_HS SG_ 479 EASSI_StrtStpSt 1;
BA_REL_ "GenSigTimeoutTime" BU_SG_REL_ TCM_HS SG_ 479 EASSI_TorqDetdIndet 250;
BA_REL_ "GenSigTimeoutMsg" BU_SG_REL_ TCM_HS SG_ 479 EASSI_TorqDetdIndet 479;
BA_REL_ "GenSigSuprvResp" BU_SG_REL_ TCM_HS SG_ 479 EASSI_TorqDetdIndet 1;
BA_REL_ "GenSigTimeoutTime" BU_SG_REL_ ECM_HS SG_ 479 EASSI_TorqDetdIndet 250;
BA_REL_ "GenSigTimeoutMsg" BU_SG_REL_ ECM_HS SG_ 479 EASSI_TorqDetdIndet 479;
BA_REL_ "GenSigSuprvResp" BU_SG_REL_ ECM_HS SG_ 479 EASSI_TorqDetdIndet 1;
BA_REL_ "GenSigTimeoutTime" BU_SG_REL_ EBCM_HS SG_ 479 EASSI_TorqDetdIndet 250;
BA_REL_ "GenSigTimeoutMsg" BU_SG_REL_ EBCM_HS SG_ 479 EASSI_TorqDetdIndet 479;
BA_REL_ "GenSigSuprvResp" BU_SG_REL_ EBCM_HS SG_ 479 EASSI_TorqDetdIndet 1;
BA_REL_ "GenSigTimeoutTime" BU_SG_REL_ BCM_HS SG_ 479 EASSI_TorqDetdIndet 62;
BA_REL_ "GenSigTimeoutMsg" BU_SG_REL_ BCM_HS SG_ 479 EASSI_TorqDetdIndet 479;
BA_REL_ "GenSigSuprvResp" BU_SG_REL_ BCM_HS SG_ 479 EASSI_TorqDetdIndet 1;
BA_REL_ "GenSigTimeoutTime" BU_SG_REL_ BCM_HS SG_ 479 ASIRI_Indication08 62;
BA_REL_ "GenSigTimeoutMsg" BU_SG_REL_ BCM_HS SG_ 479 ASIRI_Indication08 479;
BA_REL_ "GenSigSuprvResp" BU_SG_REL_ BCM_HS SG_ 479 ASIRI_Indication08 1;
BA_REL_ "GenSigTimeoutTime" BU_SG_REL_ BCM_HS SG_ 479 ASIRI_Indication07 62;
BA_REL_ "GenSigTimeoutMsg" BU_SG_REL_ BCM_HS SG_ 479 ASIRI_Indication07 479;
BA_REL_ "GenSigSuprvResp" BU_SG_REL_ BCM_HS SG_ 479 ASIRI_Indication07 1;
BA_REL_ "GenSigTimeoutTime" BU_SG_REL_ BCM_HS SG_ 479 ASIRI_Indication06 62;
BA_REL_ "GenSigTimeoutMsg" BU_SG_REL_ BCM_HS SG_ 479 ASIRI_Indication06 479;
BA_REL_ "GenSigSuprvResp" BU_SG_REL_ BCM_HS SG_ 479 ASIRI_Indication06 1;
BA_REL_ "GenSigTimeoutTime" BU_SG_REL_ BCM_HS SG_ 479 ASIRI_Indication05 62;
BA_REL_ "GenSigTimeoutMsg" BU_SG_REL_ BCM_HS SG_ 479 ASIRI_Indication05 479;
BA_REL_ "GenSigSuprvResp" BU_SG_REL_ BCM_HS SG_ 479 ASIRI_Indication05 1;
BA_REL_ "GenSigTimeoutTime" BU_SG_REL_ BCM_HS SG_ 479 ASIRI_Indication04 62;
BA_REL_ "GenSigTimeoutMsg" BU_SG_REL_ BCM_HS SG_ 479 ASIRI_Indication04 479;
BA_REL_ "GenSigSuprvResp" BU_SG_REL_ BCM_HS SG_ 479 ASIRI_Indication04 1;
BA_REL_ "GenSigTimeoutTime" BU_SG_REL_ BCM_HS SG_ 479 ASIRI_Indication03 62;
BA_REL_ "GenSigTimeoutMsg" BU_SG_REL_ BCM_HS SG_ 479 ASIRI_Indication03 479;
BA_REL_ "GenSigSuprvResp" BU_SG_REL_ BCM_HS SG_ 479 ASIRI_Indication03 1;
BA_REL_ "GenSigTimeoutTime" BU_SG_REL_ BCM_HS SG_ 479 ASIRI_Indication02 62;
BA_REL_ "GenSigTimeoutMsg" BU_SG_REL_ BCM_HS SG_ 479 ASIRI_Indication02 479;
BA_REL_ "GenSigSuprvResp" BU_SG_REL_ BCM_HS SG_ 479 ASIRI_Indication02 1;
BA_REL_ "GenSigTimeoutTime" BU_SG_REL_ BCM_HS SG_ 479 ASIRI_Indication01 62;
BA_REL_ "GenSigTimeoutMsg" BU_SG_REL_ BCM_HS SG_ 479 ASIRI_Indication01 479;
BA_REL_ "GenSigSuprvResp" BU_SG_REL_ BCM_HS SG_ 479 ASIRI_Indication01 1;
BA_REL_ "GenSigTimeoutTime" BU_SG_REL_ BCM_HS SG_ 479 PTWrmgWtToShftIO 62;
BA_REL_ "GenSigTimeoutMsg" BU_SG_REL_ BCM_HS SG_ 479 PTWrmgWtToShftIO 479;
BA_REL_ "GenSigSuprvResp" BU_SG_REL_ BCM_HS SG_ 479 PTWrmgWtToShftIO 1;
BA_REL_ "GenSigTimeoutTime" BU_SG_REL_ BCM_HS SG_ 479 PTShftLvrLckRqd 62;
BA_REL_ "GenSigTimeoutMsg" BU_SG_REL_ BCM_HS SG_ 479 PTShftLvrLckRqd 479;
BA_REL_ "GenSigSuprvResp" BU_SG_REL_ BCM_HS SG_ 479 PTShftLvrLckRqd 1;
BA_REL_ "GenSigTimeoutTime" BU_SG_REL_ CGM_HS SG_ 1020 OtsAirTmpEmsnsRel 625;
BA_REL_ "GenSigTimeoutMsg" BU_SG_REL_ CGM_HS SG_ 1020 OtsAirTmpEmsnsRel 1020;
BA_REL_ "GenSigSuprvResp" BU_SG_REL_ CGM_HS SG_ 1020 OtsAirTmpEmsnsRel 1;
BA_REL_ "GenSigTimeoutTime" BU_SG_REL_ BSM_HS SG_ 1020 OtsAirTmpEmsnsRel 625;
BA_REL_ "GenSigTimeoutMsg" BU_SG_REL_ BSM_HS SG_ 1020 OtsAirTmpEmsnsRel 1020;
BA_REL_ "GenSigSuprvResp" BU_SG_REL_ BSM_HS SG_ 1020 OtsAirTmpEmsnsRel 1;
BA_REL_ "GenSigTimeoutTime" BU_SG_REL_ CGM_HS SG_ 1020 OATEmsnsRelCrVal 625;
BA_REL_ "GenSigTimeoutMsg" BU_SG_REL_ CGM_HS SG_ 1020 OATEmsnsRelCrVal 1020;
BA_REL_ "GenSigSuprvResp" BU_SG_REL_ CGM_HS SG_ 1020 OATEmsnsRelCrVal 1;
BA_REL_ "GenSigTimeoutTime" BU_SG_REL_ BSM_HS SG_ 1020 OATEmsnsRelCrVal 625;
BA_REL_ "GenSigTimeoutMsg" BU_SG_REL_ BSM_HS SG_ 1020 OATEmsnsRelCrVal 1020;
BA_REL_ "GenSigSuprvResp" BU_SG_REL_ BSM_HS SG_ 1020 OATEmsnsRelCrVal 1;
BA_REL_ "GenSigTimeoutTime" BU_SG_REL_ CGM_HS SG_ 1020 CatlystOutGasTempEst 625;
BA_REL_ "GenSigTimeoutMsg" BU_SG_REL_ CGM_HS SG_ 1020 CatlystOutGasTempEst 1020;
BA_REL_ "GenSigSuprvResp" BU_SG_REL_ CGM_HS SG_ 1020 CatlystOutGasTempEst 1;
BA_REL_ "GenSigTimeoutTime" BU_SG_REL_ BSM_HS SG_ 1020 CatlystOutGasTempEst 625;
BA_REL_ "GenSigTimeoutMsg" BU_SG_REL_ BSM_HS SG_ 1020 CatlystOutGasTempEst 1020;
BA_REL_ "GenSigSuprvResp" BU_SG_REL_ BSM_HS SG_ 1020 CatlystOutGasTempEst 1;
BA_REL_ "GenSigTimeoutTime" BU_SG_REL_ TCM_HS SG_ 1020 OtsAirTmpCrVal 625;
BA_REL_ "GenSigTimeoutMsg" BU_SG_REL_ TCM_HS SG_ 1020 OtsAirTmpCrVal 1020;
BA_REL_ "GenSigSuprvResp" BU_SG_REL_ TCM_HS SG_ 1020 OtsAirTmpCrVal 1;
BA_REL_ "GenSigTimeoutTime" BU_SG_REL_ BSM_HS SG_ 1020 OtsAirTmpCrVal 625;
BA_REL_ "GenSigTimeoutMsg" BU_SG_REL_ BSM_HS SG_ 1020 OtsAirTmpCrVal 1020;
BA_REL_ "GenSigSuprvResp" BU_SG_REL_ BSM_HS SG_ 1020 OtsAirTmpCrVal 1;
BA_REL_ "GenSigTimeoutTime" BU_SG_REL_ CGM_HS SG_ 1020 OtsAirTmp 625;
BA_REL_ "GenSigTimeoutMsg" BU_SG_REL_ CGM_HS SG_ 1020 OtsAirTmp 1020;
BA_REL_ "GenSigSuprvResp" BU_SG_REL_ CGM_HS SG_ 1020 OtsAirTmp 1;
BA_REL_ "GenSigTimeoutTime" BU_SG_REL_ BSM_HS SG_ 1020 OtsAirTmp 625;
BA_REL_ "GenSigTimeoutMsg" BU_SG_REL_ BSM_HS SG_ 1020 OtsAirTmp 1020;
BA_REL_ "GenSigSuprvResp" BU_SG_REL_ BSM_HS SG_ 1020 OtsAirTmp 1;
BA_REL_ "GenSigTimeoutTime" BU_SG_REL_ CGM_HS SG_ 1020 EngInltSpcfcHmdty 625;
BA_REL_ "GenSigTimeoutMsg" BU_SG_REL_ CGM_HS SG_ 1020 EngInltSpcfcHmdty 1020;
BA_REL_ "GenSigSuprvResp" BU_SG_REL_ CGM_HS SG_ 1020 EngInltSpcfcHmdty 1;
BA_REL_ "GenSigTimeoutTime" BU_SG_REL_ EBCM_HS SG_ 1020 EngInltSpcfcHmdty 625;
BA_REL_ "GenSigTimeoutMsg" BU_SG_REL_ EBCM_HS SG_ 1020 EngInltSpcfcHmdty 1020;
BA_REL_ "GenSigSuprvResp" BU_SG_REL_ EBCM_HS SG_ 1020 EngInltSpcfcHmdty 1;
BA_REL_ "GenSigTimeoutTime" BU_SG_REL_ BSM_HS SG_ 1020 EngInltSpcfcHmdty 625;
BA_REL_ "GenSigTimeoutMsg" BU_SG_REL_ BSM_HS SG_ 1020 EngInltSpcfcHmdty 1020;
BA_REL_ "GenSigSuprvResp" BU_SG_REL_ BSM_HS SG_ 1020 EngInltSpcfcHmdty 1;
BA_REL_ "GenSigTimeoutTime" BU_SG_REL_ ECM_HS SG_ 567 LnchCtrlMdStat 625;
BA_REL_ "GenSigTimeoutMsg" BU_SG_REL_ ECM_HS SG_ 567 LnchCtrlMdStat 567;
BA_REL_ "GenSigSuprvResp" BU_SG_REL_ ECM_HS SG_ 567 LnchCtrlMdStat 1;
BA_REL_ "GenSigTimeoutTime" BU_SG_REL_ BCM_HS SG_ 567 DrvStyPerfMdCsCrStVal 625;
BA_REL_ "GenSigTimeoutMsg" BU_SG_REL_ BCM_HS SG_ 567 DrvStyPerfMdCsCrStVal 567;
BA_REL_ "GenSigSuprvResp" BU_SG_REL_ BCM_HS SG_ 567 DrvStyPerfMdCsCrStVal 1;
BA_REL_ "GenSigTimeoutTime" BU_SG_REL_ BCM_HS SG_ 567 DrvStyPerfMdCsStAvl 625;
BA_REL_ "GenSigTimeoutMsg" BU_SG_REL_ BCM_HS SG_ 567 DrvStyPerfMdCsStAvl 567;
BA_REL_ "GenSigSuprvResp" BU_SG_REL_ BCM_HS SG_ 567 DrvStyPerfMdCsStAvl 1;
BA_REL_ "GenSigTimeoutTime" BU_SG_REL_ BCM_HS SG_ 567 PsngStPerfMdCsCrStVal 625;
BA_REL_ "GenSigTimeoutMsg" BU_SG_REL_ BCM_HS SG_ 567 PsngStPerfMdCsCrStVal 567;
BA_REL_ "GenSigSuprvResp" BU_SG_REL_ BCM_HS SG_ 567 PsngStPerfMdCsCrStVal 1;
BA_REL_ "GenSigTimeoutTime" BU_SG_REL_ BCM_HS SG_ 567 PsngStPerfMdCsStAvl 625;
BA_REL_ "GenSigTimeoutMsg" BU_SG_REL_ BCM_HS SG_ 567 PsngStPerfMdCsStAvl 567;
BA_REL_ "GenSigSuprvResp" BU_SG_REL_ BCM_HS SG_ 567 PsngStPerfMdCsStAvl 1;
BA_REL_ "GenSigTimeoutTime" BU_SG_REL_ BCM_HS SG_ 567 DrvrStPerfMdCsCrStVal 625;
BA_REL_ "GenSigTimeoutMsg" BU_SG_REL_ BCM_HS SG_ 567 DrvrStPerfMdCsCrStVal 567;
BA_REL_ "GenSigSuprvResp" BU_SG_REL_ BCM_HS SG_ 567 DrvrStPerfMdCsCrStVal 1;
BA_REL_ "GenSigTimeoutTime" BU_SG_REL_ BCM_HS SG_ 567 DrvrStPerfMdCsStAvl 625;
BA_REL_ "GenSigTimeoutMsg" BU_SG_REL_ BCM_HS SG_ 567 DrvrStPerfMdCsStAvl 567;
BA_REL_ "GenSigSuprvResp" BU_SG_REL_ BCM_HS SG_ 567 DrvrStPerfMdCsStAvl 1;
BA_REL_ "GenSigTimeoutTime" BU_SG_REL_ BCM_HS SG_ 567 ACCPerfMdCsCrStVal 625;
BA_REL_ "GenSigTimeoutMsg" BU_SG_REL_ BCM_HS SG_ 567 ACCPerfMdCsCrStVal 567;
BA_REL_ "GenSigSuprvResp" BU_SG_REL_ BCM_HS SG_ 567 ACCPerfMdCsCrStVal 1;
BA_REL_ "GenSigTimeoutTime" BU_SG_REL_ BCM_HS SG_ 567 ACCPerfMdCsStAvl 625;
BA_REL_ "GenSigTimeoutMsg" BU_SG_REL_ BCM_HS SG_ 567 ACCPerfMdCsStAvl 567;
BA_REL_ "GenSigSuprvResp" BU_SG_REL_ BCM_HS SG_ 567 ACCPerfMdCsStAvl 1;
BA_REL_ "GenSigTimeoutTime" BU_SG_REL_ BCM_HS SG_ 1219 DslExhFldDiagWrnIdRq 2500;
BA_REL_ "GenSigTimeoutMsg" BU_SG_REL_ BCM_HS SG_ 1219 DslExhFldDiagWrnIdRq 1219;
BA_REL_ "GenSigSuprvResp" BU_SG_REL_ BCM_HS SG_ 1219 DslExhFldDiagWrnIdRq 1;
BA_REL_ "GenSigTimeoutTime" BU_SG_REL_ BCM_HS SG_ 1219 DslEmnsOBDMrkt 2500;
BA_REL_ "GenSigTimeoutMsg" BU_SG_REL_ BCM_HS SG_ 1219 DslEmnsOBDMrkt 1219;
BA_REL_ "GenSigSuprvResp" BU_SG_REL_ BCM_HS SG_ 1219 DslEmnsOBDMrkt 1;
BA_REL_ "GenSigTimeoutTime" BU_SG_REL_ BCM_HS SG_ 565 PerfMdMainMenuType 5000;
BA_REL_ "GenSigTimeoutMsg" BU_SG_REL_ BCM_HS SG_ 565 PerfMdMainMenuType 565;
BA_REL_ "GenSigSuprvResp" BU_SG_REL_ BCM_HS SG_ 565 PerfMdMainMenuType 1;
BA_REL_ "GenSigTimeoutTime" BU_SG_REL_ BCM_HS SG_ 565 PSPMCA_PsngStPrfMd6Avl 5000;
BA_REL_ "GenSigTimeoutMsg" BU_SG_REL_ BCM_HS SG_ 565 PSPMCA_PsngStPrfMd6Avl 565;
BA_REL_ "GenSigSuprvResp" BU_SG_REL_ BCM_HS SG_ 565 PSPMCA_PsngStPrfMd6Avl 1;
BA_REL_ "GenSigTimeoutTime" BU_SG_REL_ BCM_HS SG_ 565 PSPMCA_PsngStPrfMd5Avl 5000;
BA_REL_ "GenSigTimeoutMsg" BU_SG_REL_ BCM_HS SG_ 565 PSPMCA_PsngStPrfMd5Avl 565;
BA_REL_ "GenSigSuprvResp" BU_SG_REL_ BCM_HS SG_ 565 PSPMCA_PsngStPrfMd5Avl 1;
BA_REL_ "GenSigTimeoutTime" BU_SG_REL_ BCM_HS SG_ 565 PSPMCA_PsngStPrfMd4Avl 5000;
BA_REL_ "GenSigTimeoutMsg" BU_SG_REL_ BCM_HS SG_ 565 PSPMCA_PsngStPrfMd4Avl 565;
BA_REL_ "GenSigSuprvResp" BU_SG_REL_ BCM_HS SG_ 565 PSPMCA_PsngStPrfMd4Avl 1;
BA_REL_ "GenSigTimeoutTime" BU_SG_REL_ BCM_HS SG_ 565 PSPMCA_PsngStPrfMd3Avl 5000;
BA_REL_ "GenSigTimeoutMsg" BU_SG_REL_ BCM_HS SG_ 565 PSPMCA_PsngStPrfMd3Avl 565;
BA_REL_ "GenSigSuprvResp" BU_SG_REL_ BCM_HS SG_ 565 PSPMCA_PsngStPrfMd3Avl 1;
BA_REL_ "GenSigTimeoutTime" BU_SG_REL_ BCM_HS SG_ 565 PSPMCA_PsngStPrfMd2Avl 5000;
BA_REL_ "GenSigTimeoutMsg" BU_SG_REL_ BCM_HS SG_ 565 PSPMCA_PsngStPrfMd2Avl 565;
BA_REL_ "GenSigSuprvResp" BU_SG_REL_ BCM_HS SG_ 565 PSPMCA_PsngStPrfMd2Avl 1;
BA_REL_ "GenSigTimeoutTime" BU_SG_REL_ BCM_HS SG_ 565 PSPMCA_PsngStPrfMd1Avl 5000;
BA_REL_ "GenSigTimeoutMsg" BU_SG_REL_ BCM_HS SG_ 565 PSPMCA_PsngStPrfMd1Avl 565;
BA_REL_ "GenSigSuprvResp" BU_SG_REL_ BCM_HS SG_ 565 PSPMCA_PsngStPrfMd1Avl 1;
BA_REL_ "GenSigTimeoutTime" BU_SG_REL_ BCM_HS SG_ 565 DSPMCA_DrvStyPrfMd7Avl 5000;
BA_REL_ "GenSigTimeoutMsg" BU_SG_REL_ BCM_HS SG_ 565 DSPMCA_DrvStyPrfMd7Avl 565;
BA_REL_ "GenSigSuprvResp" BU_SG_REL_ BCM_HS SG_ 565 DSPMCA_DrvStyPrfMd7Avl 1;
BA_REL_ "GenSigTimeoutTime" BU_SG_REL_ BCM_HS SG_ 565 DSPMCA_DrvStyPrfMd6Avl 5000;
BA_REL_ "GenSigTimeoutMsg" BU_SG_REL_ BCM_HS SG_ 565 DSPMCA_DrvStyPrfMd6Avl 565;
BA_REL_ "GenSigSuprvResp" BU_SG_REL_ BCM_HS SG_ 565 DSPMCA_DrvStyPrfMd6Avl 1;
BA_REL_ "GenSigTimeoutTime" BU_SG_REL_ BCM_HS SG_ 565 DSPMCA_DrvStyPrfMd5Avl 5000;
BA_REL_ "GenSigTimeoutMsg" BU_SG_REL_ BCM_HS SG_ 565 DSPMCA_DrvStyPrfMd5Avl 565;
BA_REL_ "GenSigSuprvResp" BU_SG_REL_ BCM_HS SG_ 565 DSPMCA_DrvStyPrfMd5Avl 1;
BA_REL_ "GenSigTimeoutTime" BU_SG_REL_ BCM_HS SG_ 565 DSPMCA_DrvStyPrfMd4Avl 5000;
BA_REL_ "GenSigTimeoutMsg" BU_SG_REL_ BCM_HS SG_ 565 DSPMCA_DrvStyPrfMd4Avl 565;
BA_REL_ "GenSigSuprvResp" BU_SG_REL_ BCM_HS SG_ 565 DSPMCA_DrvStyPrfMd4Avl 1;
BA_REL_ "GenSigTimeoutTime" BU_SG_REL_ BCM_HS SG_ 565 DSPMCA_DrvStyPrfMd3Avl 5000;
BA_REL_ "GenSigTimeoutMsg" BU_SG_REL_ BCM_HS SG_ 565 DSPMCA_DrvStyPrfMd3Avl 565;
BA_REL_ "GenSigSuprvResp" BU_SG_REL_ BCM_HS SG_ 565 DSPMCA_DrvStyPrfMd3Avl 1;
BA_REL_ "GenSigTimeoutTime" BU_SG_REL_ BCM_HS SG_ 565 DSPMCA_DrvStyPrfMd2Avl 5000;
BA_REL_ "GenSigTimeoutMsg" BU_SG_REL_ BCM_HS SG_ 565 DSPMCA_DrvStyPrfMd2Avl 565;
BA_REL_ "GenSigSuprvResp" BU_SG_REL_ BCM_HS SG_ 565 DSPMCA_DrvStyPrfMd2Avl 1;
BA_REL_ "GenSigTimeoutTime" BU_SG_REL_ BCM_HS SG_ 565 DSPMCA_DrvStyPrfMd1Avl 5000;
BA_REL_ "GenSigTimeoutMsg" BU_SG_REL_ BCM_HS SG_ 565 DSPMCA_DrvStyPrfMd1Avl 565;
BA_REL_ "GenSigSuprvResp" BU_SG_REL_ BCM_HS SG_ 565 DSPMCA_DrvStyPrfMd1Avl 1;
BA_REL_ "GenSigTimeoutTime" BU_SG_REL_ BCM_HS SG_ 565 DSPMCA_DrvrStPrfMd6Avl 5000;
BA_REL_ "GenSigTimeoutMsg" BU_SG_REL_ BCM_HS SG_ 565 DSPMCA_DrvrStPrfMd6Avl 565;
BA_REL_ "GenSigSuprvResp" BU_SG_REL_ BCM_HS SG_ 565 DSPMCA_DrvrStPrfMd6Avl 1;
BA_REL_ "GenSigTimeoutTime" BU_SG_REL_ BCM_HS SG_ 565 DSPMCA_DrvrStPrfMd5Avl 5000;
BA_REL_ "GenSigTimeoutMsg" BU_SG_REL_ BCM_HS SG_ 565 DSPMCA_DrvrStPrfMd5Avl 565;
BA_REL_ "GenSigSuprvResp" BU_SG_REL_ BCM_HS SG_ 565 DSPMCA_DrvrStPrfMd5Avl 1;
BA_REL_ "GenSigTimeoutTime" BU_SG_REL_ BCM_HS SG_ 565 DSPMCA_DrvrStPrfMd4Avl 5000;
BA_REL_ "GenSigTimeoutMsg" BU_SG_REL_ BCM_HS SG_ 565 DSPMCA_DrvrStPrfMd4Avl 565;
BA_REL_ "GenSigSuprvResp" BU_SG_REL_ BCM_HS SG_ 565 DSPMCA_DrvrStPrfMd4Avl 1;
BA_REL_ "GenSigTimeoutTime" BU_SG_REL_ BCM_HS SG_ 565 DSPMCA_DrvrStPrfMd3Avl 5000;
BA_REL_ "GenSigTimeoutMsg" BU_SG_REL_ BCM_HS SG_ 565 DSPMCA_DrvrStPrfMd3Avl 565;
BA_REL_ "GenSigSuprvResp" BU_SG_REL_ BCM_HS SG_ 565 DSPMCA_DrvrStPrfMd3Avl 1;
BA_REL_ "GenSigTimeoutTime" BU_SG_REL_ BCM_HS SG_ 565 DSPMCA_DrvrStPrfMd2Avl 5000;
BA_REL_ "GenSigTimeoutMsg" BU_SG_REL_ BCM_HS SG_ 565 DSPMCA_DrvrStPrfMd2Avl 565;
BA_REL_ "GenSigSuprvResp" BU_SG_REL_ BCM_HS SG_ 565 DSPMCA_DrvrStPrfMd2Avl 1;
BA_REL_ "GenSigTimeoutTime" BU_SG_REL_ BCM_HS SG_ 565 DSPMCA_DrvrStPrfMd1Avl 5000;
BA_REL_ "GenSigTimeoutMsg" BU_SG_REL_ BCM_HS SG_ 565 DSPMCA_DrvrStPrfMd1Avl 565;
BA_REL_ "GenSigSuprvResp" BU_SG_REL_ BCM_HS SG_ 565 DSPMCA_DrvrStPrfMd1Avl 1;
BA_REL_ "GenSigTimeoutTime" BU_SG_REL_ BCM_HS SG_ 565 ACCPMCA_ACCPrfMd6Avl 5000;
BA_REL_ "GenSigTimeoutMsg" BU_SG_REL_ BCM_HS SG_ 565 ACCPMCA_ACCPrfMd6Avl 565;
BA_REL_ "GenSigSuprvResp" BU_SG_REL_ BCM_HS SG_ 565 ACCPMCA_ACCPrfMd6Avl 1;
BA_REL_ "GenSigTimeoutTime" BU_SG_REL_ BCM_HS SG_ 565 ACCPMCA_ACCPrfMd5Avl 5000;
BA_REL_ "GenSigTimeoutMsg" BU_SG_REL_ BCM_HS SG_ 565 ACCPMCA_ACCPrfMd5Avl 565;
BA_REL_ "GenSigSuprvResp" BU_SG_REL_ BCM_HS SG_ 565 ACCPMCA_ACCPrfMd5Avl 1;
BA_REL_ "GenSigTimeoutTime" BU_SG_REL_ BCM_HS SG_ 565 ACCPMCA_ACCPrfMd4Avl 5000;
BA_REL_ "GenSigTimeoutMsg" BU_SG_REL_ BCM_HS SG_ 565 ACCPMCA_ACCPrfMd4Avl 565;
BA_REL_ "GenSigSuprvResp" BU_SG_REL_ BCM_HS SG_ 565 ACCPMCA_ACCPrfMd4Avl 1;
BA_REL_ "GenSigTimeoutTime" BU_SG_REL_ BCM_HS SG_ 565 ACCPMCA_ACCPrfMd3Avl 5000;
BA_REL_ "GenSigTimeoutMsg" BU_SG_REL_ BCM_HS SG_ 565 ACCPMCA_ACCPrfMd3Avl 565;
BA_REL_ "GenSigSuprvResp" BU_SG_REL_ BCM_HS SG_ 565 ACCPMCA_ACCPrfMd3Avl 1;
BA_REL_ "GenSigTimeoutTime" BU_SG_REL_ BCM_HS SG_ 565 ACCPMCA_ACCPrfMd2Avl 5000;
BA_REL_ "GenSigTimeoutMsg" BU_SG_REL_ BCM_HS SG_ 565 ACCPMCA_ACCPrfMd2Avl 565;
BA_REL_ "GenSigSuprvResp" BU_SG_REL_ BCM_HS SG_ 565 ACCPMCA_ACCPrfMd2Avl 1;
BA_REL_ "GenSigTimeoutTime" BU_SG_REL_ BCM_HS SG_ 565 ACCPMCA_ACCPrfMd1Avl 5000;
BA_REL_ "GenSigTimeoutMsg" BU_SG_REL_ BCM_HS SG_ 565 ACCPMCA_ACCPrfMd1Avl 565;
BA_REL_ "GenSigSuprvResp" BU_SG_REL_ BCM_HS SG_ 565 ACCPMCA_ACCPrfMd1Avl 1;
BA_REL_ "GenSigTimeoutTime" BU_SG_REL_ EBCM_HS SG_ 500 EnhDrvMdSwChUseAct 250;
BA_REL_ "GenSigTimeoutMsg" BU_SG_REL_ EBCM_HS SG_ 500 EnhDrvMdSwChUseAct 500;
BA_REL_ "GenSigSuprvResp" BU_SG_REL_ EBCM_HS SG_ 500 EnhDrvMdSwChUseAct 1;
BA_REL_ "GenSigTimeoutTime" BU_SG_REL_ EBCM_HS SG_ 500 EnhDrvSelMdSwStat 250;
BA_REL_ "GenSigTimeoutMsg" BU_SG_REL_ EBCM_HS SG_ 500 EnhDrvSelMdSwStat 500;
BA_REL_ "GenSigSuprvResp" BU_SG_REL_ EBCM_HS SG_ 500 EnhDrvSelMdSwStat 1;
BA_REL_ "GenSigTimeoutTime" BU_SG_REL_ RDCM_HS SG_ 500 DrvSelMd8Stat 250;
BA_REL_ "GenSigTimeoutMsg" BU_SG_REL_ RDCM_HS SG_ 500 DrvSelMd8Stat 500;
BA_REL_ "GenSigSuprvResp" BU_SG_REL_ RDCM_HS SG_ 500 DrvSelMd8Stat 1;
BA_REL_ "GenSigTimeoutTime" BU_SG_REL_ EBCM_HS SG_ 500 DrvSelMd8Stat 250;
BA_REL_ "GenSigTimeoutMsg" BU_SG_REL_ EBCM_HS SG_ 500 DrvSelMd8Stat 500;
BA_REL_ "GenSigSuprvResp" BU_SG_REL_ EBCM_HS SG_ 500 DrvSelMd8Stat 1;
BA_REL_ "GenSigTimeoutTime" BU_SG_REL_ RDCM_HS SG_ 500 DrvSelMd8ReqDnd 250;
BA_REL_ "GenSigTimeoutMsg" BU_SG_REL_ RDCM_HS SG_ 500 DrvSelMd8ReqDnd 500;
BA_REL_ "GenSigSuprvResp" BU_SG_REL_ RDCM_HS SG_ 500 DrvSelMd8ReqDnd 1;
BA_REL_ "GenSigTimeoutTime" BU_SG_REL_ RDCM_HS SG_ 500 DrvSelMd7Stat 250;
BA_REL_ "GenSigTimeoutMsg" BU_SG_REL_ RDCM_HS SG_ 500 DrvSelMd7Stat 500;
BA_REL_ "GenSigSuprvResp" BU_SG_REL_ RDCM_HS SG_ 500 DrvSelMd7Stat 1;
BA_REL_ "GenSigTimeoutTime" BU_SG_REL_ EBCM_HS SG_ 500 DrvSelMd7Stat 250;
BA_REL_ "GenSigTimeoutMsg" BU_SG_REL_ EBCM_HS SG_ 500 DrvSelMd7Stat 500;
BA_REL_ "GenSigSuprvResp" BU_SG_REL_ EBCM_HS SG_ 500 DrvSelMd7Stat 1;
BA_REL_ "GenSigTimeoutTime" BU_SG_REL_ RDCM_HS SG_ 500 DrvSelMd7ReqDnd 250;
BA_REL_ "GenSigTimeoutMsg" BU_SG_REL_ RDCM_HS SG_ 500 DrvSelMd7ReqDnd 500;
BA_REL_ "GenSigSuprvResp" BU_SG_REL_ RDCM_HS SG_ 500 DrvSelMd7ReqDnd 1;
BA_REL_ "GenSigTimeoutTime" BU_SG_REL_ RDCM_HS SG_ 500 DrvSelMd6Stat 250;
BA_REL_ "GenSigTimeoutMsg" BU_SG_REL_ RDCM_HS SG_ 500 DrvSelMd6Stat 500;
BA_REL_ "GenSigSuprvResp" BU_SG_REL_ RDCM_HS SG_ 500 DrvSelMd6Stat 1;
BA_REL_ "GenSigTimeoutTime" BU_SG_REL_ EBCM_HS SG_ 500 DrvSelMd6Stat 250;
BA_REL_ "GenSigTimeoutMsg" BU_SG_REL_ EBCM_HS SG_ 500 DrvSelMd6Stat 500;
BA_REL_ "GenSigSuprvResp" BU_SG_REL_ EBCM_HS SG_ 500 DrvSelMd6Stat 1;
BA_REL_ "GenSigTimeoutTime" BU_SG_REL_ RDCM_HS SG_ 500 DrvSelMd6ReqDnd 250;
BA_REL_ "GenSigTimeoutMsg" BU_SG_REL_ RDCM_HS SG_ 500 DrvSelMd6ReqDnd 500;
BA_REL_ "GenSigSuprvResp" BU_SG_REL_ RDCM_HS SG_ 500 DrvSelMd6ReqDnd 1;
BA_REL_ "GenSigTimeoutTime" BU_SG_REL_ RDCM_HS SG_ 500 DrvSelMd5Stat 250;
BA_REL_ "GenSigTimeoutMsg" BU_SG_REL_ RDCM_HS SG_ 500 DrvSelMd5Stat 500;
BA_REL_ "GenSigSuprvResp" BU_SG_REL_ RDCM_HS SG_ 500 DrvSelMd5Stat 1;
BA_REL_ "GenSigTimeoutTime" BU_SG_REL_ EBCM_HS SG_ 500 DrvSelMd5Stat 250;
BA_REL_ "GenSigTimeoutMsg" BU_SG_REL_ EBCM_HS SG_ 500 DrvSelMd5Stat 500;
BA_REL_ "GenSigSuprvResp" BU_SG_REL_ EBCM_HS SG_ 500 DrvSelMd5Stat 1;
BA_REL_ "GenSigTimeoutTime" BU_SG_REL_ RDCM_HS SG_ 500 DrvSelMd5ReqDnd 250;
BA_REL_ "GenSigTimeoutMsg" BU_SG_REL_ RDCM_HS SG_ 500 DrvSelMd5ReqDnd 500;
BA_REL_ "GenSigSuprvResp" BU_SG_REL_ RDCM_HS SG_ 500 DrvSelMd5ReqDnd 1;
BA_REL_ "GenSigTimeoutTime" BU_SG_REL_ RDCM_HS SG_ 500 DrvSelMd4Stat 250;
BA_REL_ "GenSigTimeoutMsg" BU_SG_REL_ RDCM_HS SG_ 500 DrvSelMd4Stat 500;
BA_REL_ "GenSigSuprvResp" BU_SG_REL_ RDCM_HS SG_ 500 DrvSelMd4Stat 1;
BA_REL_ "GenSigTimeoutTime" BU_SG_REL_ EBCM_HS SG_ 500 DrvSelMd4Stat 250;
BA_REL_ "GenSigTimeoutMsg" BU_SG_REL_ EBCM_HS SG_ 500 DrvSelMd4Stat 500;
BA_REL_ "GenSigSuprvResp" BU_SG_REL_ EBCM_HS SG_ 500 DrvSelMd4Stat 1;
BA_REL_ "GenSigTimeoutTime" BU_SG_REL_ RDCM_HS SG_ 500 DrvSelMd4ReqDnd 250;
BA_REL_ "GenSigTimeoutMsg" BU_SG_REL_ RDCM_HS SG_ 500 DrvSelMd4ReqDnd 500;
BA_REL_ "GenSigSuprvResp" BU_SG_REL_ RDCM_HS SG_ 500 DrvSelMd4ReqDnd 1;
BA_REL_ "GenSigTimeoutTime" BU_SG_REL_ RDCM_HS SG_ 500 DrvSelMd3Stat 250;
BA_REL_ "GenSigTimeoutMsg" BU_SG_REL_ RDCM_HS SG_ 500 DrvSelMd3Stat 500;
BA_REL_ "GenSigSuprvResp" BU_SG_REL_ RDCM_HS SG_ 500 DrvSelMd3Stat 1;
BA_REL_ "GenSigTimeoutTime" BU_SG_REL_ EBCM_HS SG_ 500 DrvSelMd3Stat 250;
BA_REL_ "GenSigTimeoutMsg" BU_SG_REL_ EBCM_HS SG_ 500 DrvSelMd3Stat 500;
BA_REL_ "GenSigSuprvResp" BU_SG_REL_ EBCM_HS SG_ 500 DrvSelMd3Stat 1;
BA_REL_ "GenSigTimeoutTime" BU_SG_REL_ RDCM_HS SG_ 500 DrvSelMd3ReqDnd 250;
BA_REL_ "GenSigTimeoutMsg" BU_SG_REL_ RDCM_HS SG_ 500 DrvSelMd3ReqDnd 500;
BA_REL_ "GenSigSuprvResp" BU_SG_REL_ RDCM_HS SG_ 500 DrvSelMd3ReqDnd 1;
BA_REL_ "GenSigTimeoutTime" BU_SG_REL_ EBCM_HS SG_ 500 DrvSelMd3ReqDnd 250;
BA_REL_ "GenSigTimeoutMsg" BU_SG_REL_ EBCM_HS SG_ 500 DrvSelMd3ReqDnd 500;
BA_REL_ "GenSigSuprvResp" BU_SG_REL_ EBCM_HS SG_ 500 DrvSelMd3ReqDnd 1;
BA_REL_ "GenSigTimeoutTime" BU_SG_REL_ RDCM_HS SG_ 500 DrvSelMd2Stat 250;
BA_REL_ "GenSigTimeoutMsg" BU_SG_REL_ RDCM_HS SG_ 500 DrvSelMd2Stat 500;
BA_REL_ "GenSigSuprvResp" BU_SG_REL_ RDCM_HS SG_ 500 DrvSelMd2Stat 1;
BA_REL_ "GenSigTimeoutTime" BU_SG_REL_ EBCM_HS SG_ 500 DrvSelMd2Stat 250;
BA_REL_ "GenSigTimeoutMsg" BU_SG_REL_ EBCM_HS SG_ 500 DrvSelMd2Stat 500;
BA_REL_ "GenSigSuprvResp" BU_SG_REL_ EBCM_HS SG_ 500 DrvSelMd2Stat 1;
BA_REL_ "GenSigTimeoutTime" BU_SG_REL_ RDCM_HS SG_ 500 DrvSelMd2ReqDnd 250;
BA_REL_ "GenSigTimeoutMsg" BU_SG_REL_ RDCM_HS SG_ 500 DrvSelMd2ReqDnd 500;
BA_REL_ "GenSigSuprvResp" BU_SG_REL_ RDCM_HS SG_ 500 DrvSelMd2ReqDnd 1;
BA_REL_ "GenSigTimeoutTime" BU_SG_REL_ RDCM_HS SG_ 500 DSMSS_DrvSelMd0Pn 250;
BA_REL_ "GenSigTimeoutMsg" BU_SG_REL_ RDCM_HS SG_ 500 DSMSS_DrvSelMd0Pn 500;
BA_REL_ "GenSigSuprvResp" BU_SG_REL_ RDCM_HS SG_ 500 DSMSS_DrvSelMd0Pn 1;
BA_REL_ "GenSigTimeoutTime" BU_SG_REL_ EBCM_HS SG_ 500 DSMSS_DrvSelMd0Pn 250;
BA_REL_ "GenSigTimeoutMsg" BU_SG_REL_ EBCM_HS SG_ 500 DSMSS_DrvSelMd0Pn 500;
BA_REL_ "GenSigSuprvResp" BU_SG_REL_ EBCM_HS SG_ 500 DSMSS_DrvSelMd0Pn 1;
BA_REL_ "GenSigTimeoutTime" BU_SG_REL_ RDCM_HS SG_ 500 DSMSS_DrvSelMd8Pn 250;
BA_REL_ "GenSigTimeoutMsg" BU_SG_REL_ RDCM_HS SG_ 500 DSMSS_DrvSelMd8Pn 500;
BA_REL_ "GenSigSuprvResp" BU_SG_REL_ RDCM_HS SG_ 500 DSMSS_DrvSelMd8Pn 1;
BA_REL_ "GenSigTimeoutTime" BU_SG_REL_ EBCM_HS SG_ 500 DSMSS_DrvSelMd8Pn 250;
BA_REL_ "GenSigTimeoutMsg" BU_SG_REL_ EBCM_HS SG_ 500 DSMSS_DrvSelMd8Pn 500;
BA_REL_ "GenSigSuprvResp" BU_SG_REL_ EBCM_HS SG_ 500 DSMSS_DrvSelMd8Pn 1;
BA_REL_ "GenSigTimeoutTime" BU_SG_REL_ RDCM_HS SG_ 500 DSMSS_DrvSelMd7Pn 250;
BA_REL_ "GenSigTimeoutMsg" BU_SG_REL_ RDCM_HS SG_ 500 DSMSS_DrvSelMd7Pn 500;
BA_REL_ "GenSigSuprvResp" BU_SG_REL_ RDCM_HS SG_ 500 DSMSS_DrvSelMd7Pn 1;
BA_REL_ "GenSigTimeoutTime" BU_SG_REL_ EBCM_HS SG_ 500 DSMSS_DrvSelMd7Pn 250;
BA_REL_ "GenSigTimeoutMsg" BU_SG_REL_ EBCM_HS SG_ 500 DSMSS_DrvSelMd7Pn 500;
BA_REL_ "GenSigSuprvResp" BU_SG_REL_ EBCM_HS SG_ 500 DSMSS_DrvSelMd7Pn 1;
BA_REL_ "GenSigTimeoutTime" BU_SG_REL_ RDCM_HS SG_ 500 DSMSS_DrvSelMd6Pn 250;
BA_REL_ "GenSigTimeoutMsg" BU_SG_REL_ RDCM_HS SG_ 500 DSMSS_DrvSelMd6Pn 500;
BA_REL_ "GenSigSuprvResp" BU_SG_REL_ RDCM_HS SG_ 500 DSMSS_DrvSelMd6Pn 1;
BA_REL_ "GenSigTimeoutTime" BU_SG_REL_ EBCM_HS SG_ 500 DSMSS_DrvSelMd6Pn 250;
BA_REL_ "GenSigTimeoutMsg" BU_SG_REL_ EBCM_HS SG_ 500 DSMSS_DrvSelMd6Pn 500;
BA_REL_ "GenSigSuprvResp" BU_SG_REL_ EBCM_HS SG_ 500 DSMSS_DrvSelMd6Pn 1;
BA_REL_ "GenSigTimeoutTime" BU_SG_REL_ RDCM_HS SG_ 500 DSMSS_DrvSelMd5Pn 250;
BA_REL_ "GenSigTimeoutMsg" BU_SG_REL_ RDCM_HS SG_ 500 DSMSS_DrvSelMd5Pn 500;
BA_REL_ "GenSigSuprvResp" BU_SG_REL_ RDCM_HS SG_ 500 DSMSS_DrvSelMd5Pn 1;
BA_REL_ "GenSigTimeoutTime" BU_SG_REL_ EBCM_HS SG_ 500 DSMSS_DrvSelMd5Pn 250;
BA_REL_ "GenSigTimeoutMsg" BU_SG_REL_ EBCM_HS SG_ 500 DSMSS_DrvSelMd5Pn 500;
BA_REL_ "GenSigSuprvResp" BU_SG_REL_ EBCM_HS SG_ 500 DSMSS_DrvSelMd5Pn 1;
BA_REL_ "GenSigTimeoutTime" BU_SG_REL_ RDCM_HS SG_ 500 DSMSS_DrvSelMd4Pn 250;
BA_REL_ "GenSigTimeoutMsg" BU_SG_REL_ RDCM_HS SG_ 500 DSMSS_DrvSelMd4Pn 500;
BA_REL_ "GenSigSuprvResp" BU_SG_REL_ RDCM_HS SG_ 500 DSMSS_DrvSelMd4Pn 1;
BA_REL_ "GenSigTimeoutTime" BU_SG_REL_ EBCM_HS SG_ 500 DSMSS_DrvSelMd4Pn 250;
BA_REL_ "GenSigTimeoutMsg" BU_SG_REL_ EBCM_HS SG_ 500 DSMSS_DrvSelMd4Pn 500;
BA_REL_ "GenSigSuprvResp" BU_SG_REL_ EBCM_HS SG_ 500 DSMSS_DrvSelMd4Pn 1;
BA_REL_ "GenSigTimeoutTime" BU_SG_REL_ RDCM_HS SG_ 500 DSMSS_DrvSelMd3Pn 250;
BA_REL_ "GenSigTimeoutMsg" BU_SG_REL_ RDCM_HS SG_ 500 DSMSS_DrvSelMd3Pn 500;
BA_REL_ "GenSigSuprvResp" BU_SG_REL_ RDCM_HS SG_ 500 DSMSS_DrvSelMd3Pn 1;
BA_REL_ "GenSigTimeoutTime" BU_SG_REL_ EBCM_HS SG_ 500 DSMSS_DrvSelMd3Pn 250;
BA_REL_ "GenSigTimeoutMsg" BU_SG_REL_ EBCM_HS SG_ 500 DSMSS_DrvSelMd3Pn 500;
BA_REL_ "GenSigSuprvResp" BU_SG_REL_ EBCM_HS SG_ 500 DSMSS_DrvSelMd3Pn 1;
BA_REL_ "GenSigTimeoutTime" BU_SG_REL_ RDCM_HS SG_ 500 DSMSS_DrvSelMd2Pn 250;
BA_REL_ "GenSigTimeoutMsg" BU_SG_REL_ RDCM_HS SG_ 500 DSMSS_DrvSelMd2Pn 500;
BA_REL_ "GenSigSuprvResp" BU_SG_REL_ RDCM_HS SG_ 500 DSMSS_DrvSelMd2Pn 1;
BA_REL_ "GenSigTimeoutTime" BU_SG_REL_ EBCM_HS SG_ 500 DSMSS_DrvSelMd2Pn 250;
BA_REL_ "GenSigTimeoutMsg" BU_SG_REL_ EBCM_HS SG_ 500 DSMSS_DrvSelMd2Pn 500;
BA_REL_ "GenSigSuprvResp" BU_SG_REL_ EBCM_HS SG_ 500 DSMSS_DrvSelMd2Pn 1;
BA_REL_ "GenSigTimeoutTime" BU_SG_REL_ RDCM_HS SG_ 500 DSMSS_DrvSelMd1Pn 250;
BA_REL_ "GenSigTimeoutMsg" BU_SG_REL_ RDCM_HS SG_ 500 DSMSS_DrvSelMd1Pn 500;
BA_REL_ "GenSigSuprvResp" BU_SG_REL_ RDCM_HS SG_ 500 DSMSS_DrvSelMd1Pn 1;
BA_REL_ "GenSigTimeoutTime" BU_SG_REL_ EBCM_HS SG_ 500 DSMSS_DrvSelMd1Pn 250;
BA_REL_ "GenSigTimeoutMsg" BU_SG_REL_ EBCM_HS SG_ 500 DSMSS_DrvSelMd1Pn 500;
BA_REL_ "GenSigSuprvResp" BU_SG_REL_ EBCM_HS SG_ 500 DSMSS_DrvSelMd1Pn 1;
BA_REL_ "GenSigTimeoutTime" BU_SG_REL_ RDCM_HS SG_ 500 DSMSS_DrvSelMd8Un 250;
BA_REL_ "GenSigTimeoutMsg" BU_SG_REL_ RDCM_HS SG_ 500 DSMSS_DrvSelMd8Un 500;
BA_REL_ "GenSigSuprvResp" BU_SG_REL_ RDCM_HS SG_ 500 DSMSS_DrvSelMd8Un 1;
BA_REL_ "GenSigTimeoutTime" BU_SG_REL_ EBCM_HS SG_ 500 DSMSS_DrvSelMd8Un 250;
BA_REL_ "GenSigTimeoutMsg" BU_SG_REL_ EBCM_HS SG_ 500 DSMSS_DrvSelMd8Un 500;
BA_REL_ "GenSigSuprvResp" BU_SG_REL_ EBCM_HS SG_ 500 DSMSS_DrvSelMd8Un 1;
BA_REL_ "GenSigTimeoutTime" BU_SG_REL_ RDCM_HS SG_ 500 DSMSS_DrvSelMd7Un 250;
BA_REL_ "GenSigTimeoutMsg" BU_SG_REL_ RDCM_HS SG_ 500 DSMSS_DrvSelMd7Un 500;
BA_REL_ "GenSigSuprvResp" BU_SG_REL_ RDCM_HS SG_ 500 DSMSS_DrvSelMd7Un 1;
BA_REL_ "GenSigTimeoutTime" BU_SG_REL_ EBCM_HS SG_ 500 DSMSS_DrvSelMd7Un 250;
BA_REL_ "GenSigTimeoutMsg" BU_SG_REL_ EBCM_HS SG_ 500 DSMSS_DrvSelMd7Un 500;
BA_REL_ "GenSigSuprvResp" BU_SG_REL_ EBCM_HS SG_ 500 DSMSS_DrvSelMd7Un 1;
BA_REL_ "GenSigTimeoutTime" BU_SG_REL_ RDCM_HS SG_ 500 DSMSS_DrvSelMd6Un 250;
BA_REL_ "GenSigTimeoutMsg" BU_SG_REL_ RDCM_HS SG_ 500 DSMSS_DrvSelMd6Un 500;
BA_REL_ "GenSigSuprvResp" BU_SG_REL_ RDCM_HS SG_ 500 DSMSS_DrvSelMd6Un 1;
BA_REL_ "GenSigTimeoutTime" BU_SG_REL_ EBCM_HS SG_ 500 DSMSS_DrvSelMd6Un 250;
BA_REL_ "GenSigTimeoutMsg" BU_SG_REL_ EBCM_HS SG_ 500 DSMSS_DrvSelMd6Un 500;
BA_REL_ "GenSigSuprvResp" BU_SG_REL_ EBCM_HS SG_ 500 DSMSS_DrvSelMd6Un 1;
BA_REL_ "GenSigTimeoutTime" BU_SG_REL_ RDCM_HS SG_ 500 DSMSS_DrvSelMd5Un 250;
BA_REL_ "GenSigTimeoutMsg" BU_SG_REL_ RDCM_HS SG_ 500 DSMSS_DrvSelMd5Un 500;
BA_REL_ "GenSigSuprvResp" BU_SG_REL_ RDCM_HS SG_ 500 DSMSS_DrvSelMd5Un 1;
BA_REL_ "GenSigTimeoutTime" BU_SG_REL_ EBCM_HS SG_ 500 DSMSS_DrvSelMd5Un 250;
BA_REL_ "GenSigTimeoutMsg" BU_SG_REL_ EBCM_HS SG_ 500 DSMSS_DrvSelMd5Un 500;
BA_REL_ "GenSigSuprvResp" BU_SG_REL_ EBCM_HS SG_ 500 DSMSS_DrvSelMd5Un 1;
BA_REL_ "GenSigTimeoutTime" BU_SG_REL_ RDCM_HS SG_ 500 DSMSS_DrvSelMd4Un 250;
BA_REL_ "GenSigTimeoutMsg" BU_SG_REL_ RDCM_HS SG_ 500 DSMSS_DrvSelMd4Un 500;
BA_REL_ "GenSigSuprvResp" BU_SG_REL_ RDCM_HS SG_ 500 DSMSS_DrvSelMd4Un 1;
BA_REL_ "GenSigTimeoutTime" BU_SG_REL_ EBCM_HS SG_ 500 DSMSS_DrvSelMd4Un 250;
BA_REL_ "GenSigTimeoutMsg" BU_SG_REL_ EBCM_HS SG_ 500 DSMSS_DrvSelMd4Un 500;
BA_REL_ "GenSigSuprvResp" BU_SG_REL_ EBCM_HS SG_ 500 DSMSS_DrvSelMd4Un 1;
BA_REL_ "GenSigTimeoutTime" BU_SG_REL_ RDCM_HS SG_ 500 DSMSS_DrvSelMd3Un 250;
BA_REL_ "GenSigTimeoutMsg" BU_SG_REL_ RDCM_HS SG_ 500 DSMSS_DrvSelMd3Un 500;
BA_REL_ "GenSigSuprvResp" BU_SG_REL_ RDCM_HS SG_ 500 DSMSS_DrvSelMd3Un 1;
BA_REL_ "GenSigTimeoutTime" BU_SG_REL_ EBCM_HS SG_ 500 DSMSS_DrvSelMd3Un 250;
BA_REL_ "GenSigTimeoutMsg" BU_SG_REL_ EBCM_HS SG_ 500 DSMSS_DrvSelMd3Un 500;
BA_REL_ "GenSigSuprvResp" BU_SG_REL_ EBCM_HS SG_ 500 DSMSS_DrvSelMd3Un 1;
BA_REL_ "GenSigTimeoutTime" BU_SG_REL_ RDCM_HS SG_ 500 DSMSS_DrvSelMd2Un 250;
BA_REL_ "GenSigTimeoutMsg" BU_SG_REL_ RDCM_HS SG_ 500 DSMSS_DrvSelMd2Un 500;
BA_REL_ "GenSigSuprvResp" BU_SG_REL_ RDCM_HS SG_ 500 DSMSS_DrvSelMd2Un 1;
BA_REL_ "GenSigTimeoutTime" BU_SG_REL_ EBCM_HS SG_ 500 DSMSS_DrvSelMd2Un 250;
BA_REL_ "GenSigTimeoutMsg" BU_SG_REL_ EBCM_HS SG_ 500 DSMSS_DrvSelMd2Un 500;
BA_REL_ "GenSigSuprvResp" BU_SG_REL_ EBCM_HS SG_ 500 DSMSS_DrvSelMd2Un 1;
BA_REL_ "GenSigTimeoutTime" BU_SG_REL_ RDCM_HS SG_ 500 DSMSS_DrvSelMd1Un 250;
BA_REL_ "GenSigTimeoutMsg" BU_SG_REL_ RDCM_HS SG_ 500 DSMSS_DrvSelMd1Un 500;
BA_REL_ "GenSigSuprvResp" BU_SG_REL_ RDCM_HS SG_ 500 DSMSS_DrvSelMd1Un 1;
BA_REL_ "GenSigTimeoutTime" BU_SG_REL_ EBCM_HS SG_ 500 DSMSS_DrvSelMd1Un 250;
BA_REL_ "GenSigTimeoutMsg" BU_SG_REL_ EBCM_HS SG_ 500 DSMSS_DrvSelMd1Un 500;
BA_REL_ "GenSigSuprvResp" BU_SG_REL_ EBCM_HS SG_ 500 DSMSS_DrvSelMd1Un 1;
BA_REL_ "GenSigTimeoutTime" BU_SG_REL_ RDCM_HS SG_ 500 DrvSelMd1ReqDnd 250;
BA_REL_ "GenSigTimeoutMsg" BU_SG_REL_ RDCM_HS SG_ 500 DrvSelMd1ReqDnd 500;
BA_REL_ "GenSigSuprvResp" BU_SG_REL_ RDCM_HS SG_ 500 DrvSelMd1ReqDnd 1;
BA_REL_ "GenSigTimeoutTime" BU_SG_REL_ RDCM_HS SG_ 500 DrvSelMd1Stat 250;
BA_REL_ "GenSigTimeoutMsg" BU_SG_REL_ RDCM_HS SG_ 500 DrvSelMd1Stat 500;
BA_REL_ "GenSigSuprvResp" BU_SG_REL_ RDCM_HS SG_ 500 DrvSelMd1Stat 1;
BA_REL_ "GenSigTimeoutTime" BU_SG_REL_ EBCM_HS SG_ 500 DrvSelMd1Stat 250;
BA_REL_ "GenSigTimeoutMsg" BU_SG_REL_ EBCM_HS SG_ 500 DrvSelMd1Stat 500;
BA_REL_ "GenSigSuprvResp" BU_SG_REL_ EBCM_HS SG_ 500 DrvSelMd1Stat 1;
BA_REL_ "GenSigTimeoutTime" BU_SG_REL_ ECM_HS SG_ 407 TransStCrwlMdOvrrd 250;
BA_REL_ "GenSigTimeoutMsg" BU_SG_REL_ ECM_HS SG_ 407 TransStCrwlMdOvrrd 407;
BA_REL_ "GenSigSuprvResp" BU_SG_REL_ ECM_HS SG_ 407 TransStCrwlMdOvrrd 1;
BA_REL_ "GenSigTimeoutTime" BU_SG_REL_ ECM_HS SG_ 407 TEPI_TrnsEngdPrFlwStV 250;
BA_REL_ "GenSigTimeoutMsg" BU_SG_REL_ ECM_HS SG_ 407 TEPI_TrnsEngdPrFlwStV 407;
BA_REL_ "GenSigSuprvResp" BU_SG_REL_ ECM_HS SG_ 407 TEPI_TrnsEngdPrFlwStV 1;
BA_REL_ "GenSigTimeoutTime" BU_SG_REL_ ECM_HS SG_ 407 TEPI_TrnsEngdPrFlwSt 250;
BA_REL_ "GenSigTimeoutMsg" BU_SG_REL_ ECM_HS SG_ 407 TEPI_TrnsEngdPrFlwSt 407;
BA_REL_ "GenSigSuprvResp" BU_SG_REL_ ECM_HS SG_ 407 TEPI_TrnsEngdPrFlwSt 1;
BA_REL_ "GenSigTimeoutTime" BU_SG_REL_ ECM_HS SG_ 407 TransRatio 250;
BA_REL_ "GenSigTimeoutMsg" BU_SG_REL_ ECM_HS SG_ 407 TransRatio 407;
BA_REL_ "GenSigSuprvResp" BU_SG_REL_ ECM_HS SG_ 407 TransRatio 1;
BA_REL_ "GenSigTimeoutTime" BU_SG_REL_ ECM_HS SG_ 407 TARS_TransActRngV 250;
BA_REL_ "GenSigTimeoutMsg" BU_SG_REL_ ECM_HS SG_ 407 TARS_TransActRngV 407;
BA_REL_ "GenSigSuprvResp" BU_SG_REL_ ECM_HS SG_ 407 TARS_TransActRngV 1;
BA_REL_ "GenSigTimeoutTime" BU_SG_REL_ BSM_HS SG_ 407 TARS_TransActRngV 250;
BA_REL_ "GenSigTimeoutMsg" BU_SG_REL_ BSM_HS SG_ 407 TARS_TransActRngV 407;
BA_REL_ "GenSigSuprvResp" BU_SG_REL_ BSM_HS SG_ 407 TARS_TransActRngV 1;
BA_REL_ "GenSigTimeoutTime" BU_SG_REL_ BCM_HS SG_ 407 TARS_TransActRngV 250;
BA_REL_ "GenSigTimeoutMsg" BU_SG_REL_ BCM_HS SG_ 407 TARS_TransActRngV 407;
BA_REL_ "GenSigSuprvResp" BU_SG_REL_ BCM_HS SG_ 407 TARS_TransActRngV 1;
BA_REL_ "GenSigTimeoutTime" BU_SG_REL_ ECM_HS SG_ 407 TARS_TransActRngM 250;
BA_REL_ "GenSigTimeoutMsg" BU_SG_REL_ ECM_HS SG_ 407 TARS_TransActRngM 407;
BA_REL_ "GenSigSuprvResp" BU_SG_REL_ ECM_HS SG_ 407 TARS_TransActRngM 1;
BA_REL_ "GenSigTimeoutTime" BU_SG_REL_ BSM_HS SG_ 407 TARS_TransActRngM 250;
BA_REL_ "GenSigTimeoutMsg" BU_SG_REL_ BSM_HS SG_ 407 TARS_TransActRngM 407;
BA_REL_ "GenSigSuprvResp" BU_SG_REL_ BSM_HS SG_ 407 TARS_TransActRngM 1;
BA_REL_ "GenSigTimeoutTime" BU_SG_REL_ BCM_HS SG_ 407 TARS_TransActRngM 250;
BA_REL_ "GenSigTimeoutMsg" BU_SG_REL_ BCM_HS SG_ 407 TARS_TransActRngM 407;
BA_REL_ "GenSigSuprvResp" BU_SG_REL_ BCM_HS SG_ 407 TARS_TransActRngM 1;
BA_REL_ "GenSigTimeoutTime" BU_SG_REL_ ECM_HS SG_ 407 TARS_TransActRng 250;
BA_REL_ "GenSigTimeoutMsg" BU_SG_REL_ ECM_HS SG_ 407 TARS_TransActRng 407;
BA_REL_ "GenSigSuprvResp" BU_SG_REL_ ECM_HS SG_ 407 TARS_TransActRng 1;
BA_REL_ "GenSigTimeoutTime" BU_SG_REL_ BSM_HS SG_ 407 TARS_TransActRng 250;
BA_REL_ "GenSigTimeoutMsg" BU_SG_REL_ BSM_HS SG_ 407 TARS_TransActRng 407;
BA_REL_ "GenSigSuprvResp" BU_SG_REL_ BSM_HS SG_ 407 TARS_TransActRng 1;
BA_REL_ "GenSigTimeoutTime" BU_SG_REL_ BCM_HS SG_ 407 TARS_TransActRng 250;
BA_REL_ "GenSigTimeoutMsg" BU_SG_REL_ BCM_HS SG_ 407 TARS_TransActRng 407;
BA_REL_ "GenSigSuprvResp" BU_SG_REL_ BCM_HS SG_ 407 TARS_TransActRng 1;
BA_REL_ "GenSigTimeoutTime" BU_SG_REL_ EBCM_HS SG_ 979 PTABR_AccReq 250;
BA_REL_ "GenSigTimeoutMsg" BU_SG_REL_ EBCM_HS SG_ 979 PTABR_AccReq 979;
BA_REL_ "GenSigSuprvResp" BU_SG_REL_ EBCM_HS SG_ 979 PTABR_AccReq 1;
BA_REL_ "GenSigTimeoutTime" BU_SG_REL_ EBCM_HS SG_ 979 PTABR_PTBrkRqAct 250;
BA_REL_ "GenSigTimeoutMsg" BU_SG_REL_ EBCM_HS SG_ 979 PTABR_PTBrkRqAct 979;
BA_REL_ "GenSigSuprvResp" BU_SG_REL_ EBCM_HS SG_ 979 PTABR_PTBrkRqAct 1;
BA_REL_ "GenSigTimeoutTime" BU_SG_REL_ EBCM_HS SG_ 979 BrkBstVac 250;
BA_REL_ "GenSigTimeoutMsg" BU_SG_REL_ EBCM_HS SG_ 979 BrkBstVac 979;
BA_REL_ "GenSigSuprvResp" BU_SG_REL_ EBCM_HS SG_ 979 BrkBstVac 1;
BA_REL_ "GenSigTimeoutTime" BU_SG_REL_ BCM_HS SG_ 979 RegVltCtlEngyRcvryAct 250;
BA_REL_ "GenSigTimeoutMsg" BU_SG_REL_ BCM_HS SG_ 979 RegVltCtlEngyRcvryAct 979;
BA_REL_ "GenSigSuprvResp" BU_SG_REL_ BCM_HS SG_ 979 RegVltCtlEngyRcvryAct 1;
BA_REL_ "GenSigTimeoutTime" BU_SG_REL_ BCM_HS SG_ 979 SpdLmtrSttngTypAct 250;
BA_REL_ "GenSigTimeoutMsg" BU_SG_REL_ BCM_HS SG_ 979 SpdLmtrSttngTypAct 979;
BA_REL_ "GenSigSuprvResp" BU_SG_REL_ BCM_HS SG_ 979 SpdLmtrSttngTypAct 1;
BA_REL_ "GenSigTimeoutTime" BU_SG_REL_ BCM_HS SG_ 979 SetSpdLmtRchd 250;
BA_REL_ "GenSigTimeoutMsg" BU_SG_REL_ BCM_HS SG_ 979 SetSpdLmtRchd 979;
BA_REL_ "GenSigSuprvResp" BU_SG_REL_ BCM_HS SG_ 979 SetSpdLmtRchd 1;
BA_REL_ "GenSigTimeoutTime" BU_SG_REL_ BCM_HS SG_ 979 ElvtdIdlCstCrStVal 250;
BA_REL_ "GenSigTimeoutMsg" BU_SG_REL_ BCM_HS SG_ 979 ElvtdIdlCstCrStVal 979;
BA_REL_ "GenSigSuprvResp" BU_SG_REL_ BCM_HS SG_ 979 ElvtdIdlCstCrStVal 1;
BA_REL_ "GenSigTimeoutTime" BU_SG_REL_ BCM_HS SG_ 979 ElvtdIdlCstStAvl 250;
BA_REL_ "GenSigTimeoutMsg" BU_SG_REL_ BCM_HS SG_ 979 ElvtdIdlCstStAvl 979;
BA_REL_ "GenSigSuprvResp" BU_SG_REL_ BCM_HS SG_ 979 ElvtdIdlCstStAvl 1;
BA_REL_ "GenSigTimeoutTime" BU_SG_REL_ BCM_HS SG_ 979 EngManfldAirTempCrtd 250;
BA_REL_ "GenSigTimeoutMsg" BU_SG_REL_ BCM_HS SG_ 979 EngManfldAirTempCrtd 979;
BA_REL_ "GenSigSuprvResp" BU_SG_REL_ BCM_HS SG_ 979 EngManfldAirTempCrtd 1;
BA_REL_ "GenSigTimeoutTime" BU_SG_REL_ TCM_HS SG_ 1187 CbnHtrWrmUpReq 2500;
BA_REL_ "GenSigTimeoutMsg" BU_SG_REL_ TCM_HS SG_ 1187 CbnHtrWrmUpReq 1187;
BA_REL_ "GenSigRxStartValue" BU_SG_REL_ TCM_HS SG_ 1187 CbnHtrWrmUpReq "*";
BA_REL_ "GenSigSuprvResp" BU_SG_REL_ TCM_HS SG_ 1187 CbnHtrWrmUpReq 1;
BA_REL_ "GenSigTimeoutTime" BU_SG_REL_ TCM_HS SG_ 1187 VehGrdSnsrBsd 2500;
BA_REL_ "GenSigTimeoutMsg" BU_SG_REL_ TCM_HS SG_ 1187 VehGrdSnsrBsd 1187;
BA_REL_ "GenSigSuprvResp" BU_SG_REL_ TCM_HS SG_ 1187 VehGrdSnsrBsd 1;
BA_REL_ "GenSigTimeoutTime" BU_SG_REL_ TCM_HS SG_ 1187 UndrHdAirFlwCap 2500;
BA_REL_ "GenSigTimeoutMsg" BU_SG_REL_ TCM_HS SG_ 1187 UndrHdAirFlwCap 1187;
BA_REL_ "GenSigSuprvResp" BU_SG_REL_ TCM_HS SG_ 1187 UndrHdAirFlwCap 1;
BA_REL_ "GenSigTimeoutTime" BU_SG_REL_ BSM_HS SG_ 1187 UndrHdAirFlwCap 2500;
BA_REL_ "GenSigTimeoutMsg" BU_SG_REL_ BSM_HS SG_ 1187 UndrHdAirFlwCap 1187;
BA_REL_ "GenSigSuprvResp" BU_SG_REL_ BSM_HS SG_ 1187 UndrHdAirFlwCap 1;
BA_REL_ "GenSigTimeoutTime" BU_SG_REL_ TCM_HS SG_ 1187 UndrHdAirFlwActPrcnt 2500;
BA_REL_ "GenSigTimeoutMsg" BU_SG_REL_ TCM_HS SG_ 1187 UndrHdAirFlwActPrcnt 1187;
BA_REL_ "GenSigSuprvResp" BU_SG_REL_ TCM_HS SG_ 1187 UndrHdAirFlwActPrcnt 1;
BA_REL_ "GenSigTimeoutTime" BU_SG_REL_ BSM_HS SG_ 1187 UndrHdAirFlwActPrcnt 2500;
BA_REL_ "GenSigTimeoutMsg" BU_SG_REL_ BSM_HS SG_ 1187 UndrHdAirFlwActPrcnt 1187;
BA_REL_ "GenSigSuprvResp" BU_SG_REL_ BSM_HS SG_ 1187 UndrHdAirFlwActPrcnt 1;
BA_REL_ "GenSigTimeoutTime" BU_SG_REL_ ECM_HS SG_ 566 ChrgSysShftPrkReq 250;
BA_REL_ "GenSigTimeoutMsg" BU_SG_REL_ ECM_HS SG_ 566 ChrgSysShftPrkReq 566;
BA_REL_ "GenSigSuprvResp" BU_SG_REL_ ECM_HS SG_ 566 ChrgSysShftPrkReq 1;
BA_REL_ "GenSigTimeoutTime" BU_SG_REL_ CGM_HS SG_ 566 HVBatChrgCrdAlrtReq 250;
BA_REL_ "GenSigTimeoutMsg" BU_SG_REL_ CGM_HS SG_ 566 HVBatChrgCrdAlrtReq 566;
BA_REL_ "GenSigSuprvResp" BU_SG_REL_ CGM_HS SG_ 566 HVBatChrgCrdAlrtReq 1;
BA_REL_ "GenSigTimeoutTime" BU_SG_REL_ EBCM_HS SG_ 566 ChrgSysPrkBrkAnmsBrkReq 500;
BA_REL_ "GenSigTimeoutMsg" BU_SG_REL_ EBCM_HS SG_ 566 ChrgSysPrkBrkAnmsBrkReq 566;
BA_REL_ "GenSigSuprvResp" BU_SG_REL_ EBCM_HS SG_ 566 ChrgSysPrkBrkAnmsBrkReq 1;
BA_REL_ "GenSigTimeoutTime" BU_SG_REL_ BCM_HS SG_ 566 ChrgSysAudblIndRq 250;
BA_REL_ "GenSigTimeoutMsg" BU_SG_REL_ BCM_HS SG_ 566 ChrgSysAudblIndRq 566;
BA_REL_ "GenSigSuprvResp" BU_SG_REL_ BCM_HS SG_ 566 ChrgSysAudblIndRq 1;
BA_REL_ "GenSigTimeoutTime" BU_SG_REL_ BCM_HS SG_ 817 RrAxlELSDCplLwRes 250;
BA_REL_ "GenSigTimeoutMsg" BU_SG_REL_ BCM_HS SG_ 817 RrAxlELSDCplLwRes 817;
BA_REL_ "GenSigSuprvResp" BU_SG_REL_ BCM_HS SG_ 817 RrAxlELSDCplLwRes 1;
BA_REL_ "GenSigTimeoutTime" BU_SG_REL_ BCM_HS SG_ 817 RrDrvlnSysVehTpSpdLmVal 250;
BA_REL_ "GenSigTimeoutMsg" BU_SG_REL_ BCM_HS SG_ 817 RrDrvlnSysVehTpSpdLmVal 817;
BA_REL_ "GenSigSuprvRespSubValue" BU_SG_REL_ BCM_HS SG_ 817 RrDrvlnSysVehTpSpdLmVal 255;
BA_REL_ "GenSigSuprvResp" BU_SG_REL_ BCM_HS SG_ 817 RrDrvlnSysVehTpSpdLmVal 2;
BA_REL_ "GenSigTimeoutTime" BU_SG_REL_ EBCM_HS SG_ 817 RrAxlMalfIO 1000;
BA_REL_ "GenSigTimeoutMsg" BU_SG_REL_ EBCM_HS SG_ 817 RrAxlMalfIO 817;
BA_REL_ "GenSigSuprvResp" BU_SG_REL_ EBCM_HS SG_ 817 RrAxlMalfIO 1;
BA_REL_ "GenSigTimeoutTime" BU_SG_REL_ BCM_HS SG_ 817 RrAxlMalfIO 250;
BA_REL_ "GenSigTimeoutMsg" BU_SG_REL_ BCM_HS SG_ 817 RrAxlMalfIO 817;
BA_REL_ "GenSigSuprvResp" BU_SG_REL_ BCM_HS SG_ 817 RrAxlMalfIO 1;
VAL_ 503 ElcTransRngRq 7 "Unused and Reserved" 6 "Manual Range" 5 "Low Range" 4 "Drive" 3 "Neutral" 2 "Reverse" 1 "Park" 0 "No Request" ;
VAL_ 353 ESPTrnVehOffFrPrkIO 1 "true" 0 "false" ;
VAL_ 353 ESPTrnsCtlrMalfIO 1 "true" 0 "false" ;
VAL_ 353 ESPShfToDrvTryAgnIO 1 "true" 0 "false" ;
VAL_ 353 ElcShfPriTwoGrsSlInRq 3 "Drive Indication" 2 "Neutral Indication" 1 "Park Indication" 0 "No Indication" ;
VAL_ 353 ElctShfPriLtdPerfMdIO 1 "true" 0 "false" ;
VAL_ 353 ESPDrvrExtIO 1 "true" 0 "false" ;
VAL_ 353 ESPDrvrDrStIndtrmntIO 1 "true" 0 "false" ;
VAL_ 353 ESPAutoPrkIO 1 "true" 0 "false" ;
VAL_ 353 ElecShfRngDisp 15 "Unused and Reserved 3" 14 "Unused and Reserved 2" 13 "Unused and Reserved 1" 12 "Park Requested And Denied" 11 "Drive Requested And In Progress" 10 "Neutral Requested And In Progress" 9 "Reverse Requested And In Progress" 8 "Park Requested And In Progress" 7 "Reserved" 6 "Manual Nominal" 5 "Low Nominal" 4 "Drive Nominal" 3 "Neutral Nominal" 2 "Reverse Nominal" 1 "Park Nominal" 0 "No Display " ;
VAL_ 353 ESPTransMalfIO 1 "true" 0 "false" ;
VAL_ 353 ESPRngInvldReqIO 1 "true" 0 "false" ;
VAL_ 353 ESPPrkInvldReqIO 1 "true" 0 "false" ;
VAL_ 353 ESPHldShfLvrToEngRgIO 1 "true" 0 "false" ;
VAL_ 353 ESPDrvrPrkIlkSftAtdIO 1 "true" 0 "false" ;
VAL_ 353 ESPDrvrIlkShfAtdIO 1 "true" 0 "false" ;
VAL_ 1271 BatSvrMdLvl7Act 1 "true" 0 "false" ;
VAL_ 1271 BSMCT_Mult 3 "Multiplier Factor 256" 2 "Multiplier Factor 64" 1 "Multiplier Factor 8" 0 "Multiplier Factor 1" ;
VAL_ 1271 BatSvrMdLvl6Act 1 "true" 0 "false" ;
VAL_ 1271 BatSvrMdLvl5Act 1 "true" 0 "false" ;
VAL_ 1271 BatSvrMdLvl4Act 1 "true" 0 "false" ;
VAL_ 1263 BattSOXStat 1 "Use SOC,SOH, & SOF" 0 "Don't Use SOC,SOH, & SOF" ;
VAL_ 1261 MinCrnkCrntVltStat 1 "Use Data" 0 "Don't Use Data" ;
VAL_ 1261 BattTempV 1 "Invalid" 0 "Valid" ;
VAL_ 1261 BattTempM 1 "Use Data" 0 "Don't Use Data" ;
VAL_ 1259 AllNodesVNA 1 "Activate Virtual Network" 0 "No Activation" ;
VAL_ 1259 NAHrDisChrgM 1 "Use Data" 0 "Don't Use Data" ;
VAL_ 1259 NAHrChgM 1 "Use Data" 0 "Don't Use Data" ;
VAL_ 844 IMUProtYawRtM 0 "Don't Use Data" 1 "Use Data" ;
VAL_ 844 IMUProtLonAccM 0 "Don't Use Data" 1 "Use Data" ;
VAL_ 844 IMUProtLatAccM 0 "Don't Use Data" 1 "Use Data" ;
VAL_ 844 StrAngSnsPolRat 0 "Not Passed" 1 "Passed" ;
VAL_ 844 IMUProtLonAccV 1 "Invalid" 0 "Valid" ;
VAL_ 806 DCCnvStblznErrIO 1 "true" 0 "false" ;
VAL_ 1231 DslExhFluidLvlPrcntV 1 "Invalid" 0 "Valid" ;
VAL_ 563 SPMCA_SusPrfMd6Avl 1 "true" 0 "false" ;
VAL_ 563 SPMCA_SusPrfMd5Avl 1 "true" 0 "false" ;
VAL_ 563 SPMCA_SusPrfMd4Avl 1 "true" 0 "false" ;
VAL_ 563 SPMCA_SusPrfMd3Avl 1 "true" 0 "false" ;
VAL_ 563 SPMCA_SusPrfMd2Avl 1 "true" 0 "false" ;
VAL_ 563 SPMCA_SusPrfMd1Avl 1 "true" 0 "false" ;
VAL_ 563 SPMCA_StrPrfMd6Avl 1 "true" 0 "false" ;
VAL_ 563 SPMCA_StrPrfMd5Avl 1 "true" 0 "false" ;
VAL_ 563 SPMCA_StrPrfMd4Avl 1 "true" 0 "false" ;
VAL_ 563 SPMCA_StrPrfMd3Avl 1 "true" 0 "false" ;
VAL_ 563 SPMCA_StrPrfMd2Avl 1 "true" 0 "false" ;
VAL_ 563 SPMCA_StrPrfMd1Avl 1 "true" 0 "false" ;
VAL_ 563 SPMCA_SndPrfMd6Avl 1 "true" 0 "false" ;
VAL_ 563 SPMCA_SndPrfMd5Avl 1 "true" 0 "false" ;
VAL_ 563 SPMCA_SndPrfMd4Avl 1 "true" 0 "false" ;
VAL_ 563 SPMCA_SndPrfMd3Avl 1 "true" 0 "false" ;
VAL_ 563 SPMCA_SndPrfMd2Avl 1 "true" 0 "false" ;
VAL_ 563 SPMCA_SndPrfMd1Avl 1 "true" 0 "false" ;
VAL_ 563 DPMCA_DispPrfMd6Avl 1 "true" 0 "false" ;
VAL_ 563 DPMCA_DispPrfMd5Avl 1 "true" 0 "false" ;
VAL_ 563 DPMCA_DispPrfMd4Avl 1 "true" 0 "false" ;
VAL_ 563 DPMCA_DispPrfMd3Avl 1 "true" 0 "false" ;
VAL_ 563 DPMCA_DispPrfMd2Avl 1 "true" 0 "false" ;
VAL_ 563 DPMCA_DispPrfMd1Avl 1 "true" 0 "false" ;
VAL_ 563 DPMCA_DrvlPrfMd6Avl 1 "true" 0 "false" ;
VAL_ 563 DPMCA_DrvlPrfMd5Avl 1 "true" 0 "false" ;
VAL_ 563 DPMCA_DrvlPrfMd4Avl 1 "true" 0 "false" ;
VAL_ 563 DPMCA_DrvlPrfMd3Avl 1 "true" 0 "false" ;
VAL_ 563 DPMCA_DrvlPrfMd2Avl 1 "true" 0 "false" ;
VAL_ 563 DPMCA_DrvlPrfMd1Avl 1 "true" 0 "false" ;
VAL_ 723 PerfTrcEngSpdRqStat 6 "Control System Failure Permanent" 5 "Control System Failure Temporary" 4 "Serial Data Failure Permanent" 3 "Serial Data Failure Temporary" 2 "Lost Arbitration" 1 "Request Honored" 0 "No Request" ;
VAL_ 723 PerfTrcEngSpdLmtStat 3 "Rate & Value Limited" 2 "Value Limited" 1 "Rate Limited" 0 "Not Limited" ;
VAL_ 723 PerfTrcTrqRqStat 6 "Control System Failure Permanent" 5 "Control System Failure Temporary" 4 "Serial Data Failure Permanent" 3 "Serial Data Failure Temporary" 2 "Lost Arbitration" 1 "Request Honored" 0 "No Request" ;
VAL_ 723 PerfTrcTrqLmtStat 3 "Rate & Value Limited" 2 "Value Limited" 1 "Rate Limited" 0 "Not Limited" ;
VAL_ 419 ClrCGMLgsDgInf 1 "true" 0 "false" ;
VAL_ 419 EngRunng 1 "true" 0 "false" ;
VAL_ 1268 EngAirFltMonSt 7 "Unused and Reserved 3" 6 "Unused and Reserved 2" 5 "Unused and Reserved 1" 4 "Disabled" 3 "Fault Present" 2 "Replace Air Filter Now" 1 "Replace Air Filter Soon" 0 "Ok" ;
VAL_ 384 LKATODC_TrqRqAct 1 "true" 0 "false" ;
VAL_ 866 ColPrSysHzrdLghtsReq 0 "No Action" 1 "Activate" 2 "Deactivate" 3 "Reserved" ;
VAL_ 866 ColPrSysWndwsReq 0 "No Action" 1 "Close" 2 "Open" 3 "Reserved" ;
VAL_ 866 ColPrSysDrsReq 0 "No Action" 1 "Lock All" 2 "Unlock All" 3 "Reserved" ;
VAL_ 866 ColPrSysSnrfReq 0 "No Action" 1 "Close" 2 "Open" 3 "Reserved" ;
VAL_ 866 CPSInfotmntMtReq 0 "No Mute" 1 "Unused and Reserved 1" 2 "Unused and Reserved 2" 3 "Mute" ;
VAL_ 866 StBltTgtSetAvl 1 "true" 0 "false" ;
VAL_ 866 StBltTgtCrtSetVal 0 "No Action" 1 "Low" 2 "Normal" 3 "Performance" 4 "Locked" ;
VAL_ 866 MotStBltUnblIO 1 "true" 0 "false" ;
VAL_ 866 MotStBltFldIO 1 "true" 0 "false" ;
VAL_ 479 PTAVHEnbld 1 "true" 0 "false" ;
VAL_ 479 PTAVHActv 1 "true" 0 "false" ;
VAL_ 479 PrplsnSysAtv 1 "true" 0 "false" ;
VAL_ 479 EngAutoStpNotProb 1 "true" 0 "false" ;
VAL_ 479 EASSI_UnsdRsrvd2 1 "true" 0 "false" ;
VAL_ 479 EASSI_StlDetd 1 "true" 0 "false" ;
VAL_ 479 EASSI_TrqDetd 1 "true" 0 "false" ;
VAL_ 479 EASSI_FuelReqOn 1 "true" 0 "false" ;
VAL_ 479 EASSI_StrtTyp 7 "Type G" 6 "Type F" 5 "Type E" 4 "Type D" 3 "Type C" 2 "Type B" 1 "Type A" 0 "No Start" ;
VAL_ 479 EASSI_StrtStpSt 3 "Engine Stopping" 2 "Engine Starting" 1 "Engine Running" 0 "Engine Off" ;
VAL_ 479 EASSI_TorqDetdIndet 1 "true" 0 "false" ;
VAL_ 479 ASIRI_Indication08 1 "true" 0 "false" ;
VAL_ 479 ASIRI_Indication07 1 "true" 0 "false" ;
VAL_ 479 ASIRI_Indication06 1 "true" 0 "false" ;
VAL_ 479 ASIRI_Indication05 1 "true" 0 "false" ;
VAL_ 479 ASIRI_Indication04 1 "true" 0 "false" ;
VAL_ 479 ASIRI_Indication03 1 "true" 0 "false" ;
VAL_ 479 ASIRI_Indication02 1 "true" 0 "false" ;
VAL_ 479 ASIRI_Indication01 1 "true" 0 "false" ;
VAL_ 479 PTWrmgWtToShftIO 1 "true" 0 "false" ;
VAL_ 479 PTShftLvrLckRqd 1 "true" 0 "false" ;
VAL_ 1020 OtsAirTmpEmsnsRelV 1 "Invalid" 0 "Valid" ;
VAL_ 1020 OATEmsnsRelCrValV 1 "Invalid" 0 "Valid" ;
VAL_ 1020 OATEmsnsRelCrValM 0 "Don't Use Data" 1 "Use Data" ;
VAL_ 1020 CatlystOutGasTempEstV 1 "Invalid" 0 "Valid" ;
VAL_ 1020 OtsAirTmpCrValMsk 0 "Don't Use Data" 1 "Use Data" ;
VAL_ 1020 OtsAirTmpV 1 "Invalid" 0 "Valid" ;
VAL_ 1020 OtsAirTmpCrValV 1 "Invalid" 0 "Valid" ;
VAL_ 1020 EngInltSpcfcHmdtyV 1 "Invalid" 0 "Valid" ;
VAL_ 1020 EngInltSpcfcHmdtyM 0 "Don't Use Data" 1 "Use Data" ;
VAL_ 567 LnchCtrlWhlSlpStat 31 "Unused and Reserved 10" 30 "Unused and Reserved 9" 29 "Unused and Reserved 8" 28 "Unused and Reserved 7" 27 "Unused and Reserved 6" 26 "Unused and Reserved 5" 25 "Unused and Reserved 4" 24 "Unused and Reserved 3" 23 "Unused and Reserved 2" 22 "Unused and Reserved 1" 21 "Fifteen Percent" 20 "Fourteen And A Half Percent" 19 "Fourteen Percent" 18 "Thirteen And A Half Percent" 17 "Thirteen Percent" 16 "Twelve And A Half Percent" 15 "Twelve Percent" 14 "Eleven And a Half Percent" 13 "Eleven Percent" 12 "Ten And A Half Percent" 11 "Ten Percent" 10 "Nine And A Half Percent" 9 "Nine Percent" 8 "Eight And A Half Percent" 7 "Eight Percent" 6 "Seven And A Half Percent" 5 "Seven Percent" 4 "Six And A Half Percent" 3 "Six Percent" 2 "Five And A Half Percent" 1 "Five Percent" 0 "No Action" ;
VAL_ 567 LnchCtrlMdStat 7 "Line Lock Release Brake" 6 "Line Lock Press Brake" 5 "Burn Out Or Line Lock" 4 "High Traction Custom" 3 "High Traction" 2 "General Custom" 1 "General" 0 "Disable" ;
VAL_ 567 LnchCtrlEngRPMStat 0 "No Action" 63 "Unused and Reserved 30" 62 "Unused and Reserved 29" 61 "Unused and Reserved 28" 60 "Unused and Reserved 27" 59 "Unused and Reserved 26" 58 "Unused and Reserved 25" 57 "Unused and Reserved 24" 56 "Unused and Reserved 23" 55 "Unused and Reserved 22" 54 "Unused and Reserved 21" 53 "Unused and Reserved 20" 52 "Unused and Reserved 19" 51 "Unused and Reserved 18" 50 "Unused and Reserved 17" 49 "Unused and Reserved 16" 48 "Unused and Reserved 15" 47 "Unused and Reserved 14" 46 "Unused and Reserved 13" 45 "Unused and Reserved 12" 44 "Unused and Reserved 11" 43 "Unused and Reserved 10" 42 "Unused and Reserved 9" 41 "Unused and Reserved 8" 40 "Unused and Reserved 7" 39 "Unused and Reserved 6" 38 "Unused and Reserved 5" 37 "Unused and Reserved 4" 36 "Unused and Reserved 3" 35 "Unused and Reserved 2" 34 "Unused and Reserved 1" 33 "4000" 32 "3900" 31 "3800" 30 "3700" 29 "3600" 28 "3500" 27 "3400" 26 "3300" 25 "3200" 24 "3100" 23 "3000" 22 "2900" 21 "2800" 20 "2700" 19 "2600" 18 "2500" 17 "2400" 16 "2300" 15 "2200" 14 "2100" 13 "2000" 12 "1900" 11 "1800" 10 "1700" 9 "1600" 8 "1500" 7 "1400" 6 "1300" 5 "1200" 4 "1100" 3 "1000" 2 "900" 1 "800" ;
VAL_ 567 ExtHlStrAssCsCrStVal 2 "Standard Hold" 1 "Extended Hold" 0 "No Action" ;
VAL_ 567 ExtHlStrAssCsStAvl 1 "true" 0 "false" ;
VAL_ 567 DrvStyPerfMdCsCrStVal 7 "Performance Mode 7" 6 "Performance Mode 6" 5 "Performance Mode 5" 4 "Performance Mode 4" 3 "Performance Mode 3" 2 "Performance Mode 2" 1 "Performance Mode 1" 0 "No Action" ;
VAL_ 567 DrvStyPerfMdCsStAvl 1 "true" 0 "false" ;
VAL_ 567 PsngStPerfMdCsCrStVal 7 "Auto" 6 "Performance Mode 6" 5 "Performance Mode 5" 4 "Performance Mode 4" 3 "Performance Mode 3" 2 "Performance Mode 2" 1 "Performance Mode 1" 0 "No Action" ;
VAL_ 567 PsngStPerfMdCsStAvl 1 "true" 0 "false" ;
VAL_ 567 DrvrStPerfMdCsCrStVal 7 "Auto" 6 "Performance Mode 6" 5 "Performance Mode 5" 4 "Performance Mode 4" 3 "Performance Mode 3" 2 "Performance Mode 2" 1 "Performance Mode 1" 0 "No Action" ;
VAL_ 567 DrvrStPerfMdCsStAvl 1 "true" 0 "false" ;
VAL_ 567 ACCPerfMdCsCrStVal 7 "Auto" 6 "Performance Mode 6" 5 "Performance Mode 5" 4 "Performance Mode 4" 3 "Performance Mode 3" 2 "Performance Mode 2" 1 "Performance Mode 1" 0 "No Action" ;
VAL_ 567 ACCPerfMdCsStAvl 1 "true" 0 "false" ;
VAL_ 1219 DslExhFldDiagWrnIdRq 0 "No Indication" 1 "Warning Level 1" 2 "Warning Level 2" 3 "Warning Level 3" 4 "Warning Level 4" 5 "Warning Level 5" 6 "Warning Level 6" 7 "Warning Level 7" ;
VAL_ 1219 DslEmnsOBDMrkt 0 "North America" 1 "Europe" ;
VAL_ 1219 DslExNxEmWrngIndRq 15 "Warning Level 15" 14 "Warning Level 14" 13 "Warning Level 13" 12 "Warning Level 12" 11 "Warning Level 11" 10 "Warning Level 10" 9 "Warning Level 9" 8 "Warning Level 8" 7 "Warning Level 7" 6 "Warning Level 6" 5 "Warning Level 5" 4 "Warning Level 4" 3 "Warning Level 3" 2 "Warning Level 2" 1 "Warning Level 1" 0 "No Indication" ;
VAL_ 1219 DslExFldTpWrngIndRq 15 "Warning Level 15" 14 "Warning Level 14" 13 "Warning Level 13" 12 "Warning Level 12" 11 "Warning Level 11" 10 "Warning Level 10" 9 "Warning Level 9" 8 "Warning Level 8" 7 "Warning Level 7" 6 "Warning Level 6" 5 "Warning Level 5" 4 "Warning Level 4" 3 "Warning Level 3" 2 "Warning Level 2" 1 "Warning Level 1" 0 "No Indication" ;
VAL_ 1219 DslExhFldQlyWrngIReq 15 "Warning Level 15" 14 "Warning Level 14" 13 "Warning Level 13" 12 "Warning Level 12" 11 "Warning Level 11" 10 "Warning Level 10" 9 "Warning Level 9" 8 "Warning Level 8" 7 "Warning Level 7" 6 "Warning Level 6" 5 "Warning Level 5" 4 "Warning Level 4" 3 "Warning Level 3" 2 "Warning Level 2" 1 "Warning Level 1" 0 "No Indication" ;
VAL_ 1219 DslExhFldWrngIdRqER 15 "Warning Level 15" 14 "Warning Level 14" 13 "Warning Level 13" 12 "Warning Level 12" 11 "Warning Level 11" 10 "Warning Level 10" 9 "Warning Level 9" 8 "Warning Level 8" 7 "Warning Level 7" 6 "Warning Level 6" 5 "Warning Level 5" 4 "Warning Level 4" 3 "Warning Level 3" 2 "Warning Level 2" 1 "Warning Level 1" 0 "No Indication" ;
VAL_ 1219 DslExFldCnWrngIndRq 15 "Warning Level 15" 14 "Warning Level 14" 13 "Warning Level 13" 12 "Warning Level 12" 11 "Warning Level 11" 10 "Warning Level 10" 9 "Warning Level 9" 8 "Warning Level 8" 7 "Warning Level 7" 6 "Warning Level 6" 5 "Warning Level 5" 4 "Warning Level 4" 3 "Warning Level 3" 2 "Warning Level 2" 1 "Warning Level 1" 0 "No Indication" ;
VAL_ 372 ARSOpStat 0 "Normal" 1 "Temporarily Unavailable" 2 "Reduced Performance" 3 "Failed" ;
VAL_ 372 ARSAlgmtCmplt 1 "true" 0 "false" ;
VAL_ 372 ARSActAnglV 1 "Invalid" 0 "Valid" ;
VAL_ 372 ARSFlrIO 1 "true" 0 "false" ;
VAL_ 565 PerfMdMainMenuType 7 "Reserved" 6 "Reserved" 5 "Reserved" 4 "Reserved" 3 "Main Menu Type 3" 2 "Main Menu Type 2" 1 "Main Menu Type 1" 0 "No Action" ;
VAL_ 565 PSPMCA_PsngStPrfMd6Avl 1 "true" 0 "false" ;
VAL_ 565 PSPMCA_PsngStPrfMd5Avl 1 "true" 0 "false" ;
VAL_ 565 PSPMCA_PsngStPrfMd4Avl 1 "true" 0 "false" ;
VAL_ 565 PSPMCA_PsngStPrfMd3Avl 1 "true" 0 "false" ;
VAL_ 565 PSPMCA_PsngStPrfMd2Avl 1 "true" 0 "false" ;
VAL_ 565 PSPMCA_PsngStPrfMd1Avl 1 "true" 0 "false" ;
VAL_ 565 DSPMCA_DrvStyPrfMd7Avl 1 "true" 0 "false" ;
VAL_ 565 DSPMCA_DrvStyPrfMd6Avl 1 "true" 0 "false" ;
VAL_ 565 DSPMCA_DrvStyPrfMd5Avl 1 "true" 0 "false" ;
VAL_ 565 DSPMCA_DrvStyPrfMd4Avl 1 "true" 0 "false" ;
VAL_ 565 DSPMCA_DrvStyPrfMd3Avl 1 "true" 0 "false" ;
VAL_ 565 DSPMCA_DrvStyPrfMd2Avl 1 "true" 0 "false" ;
VAL_ 565 DSPMCA_DrvStyPrfMd1Avl 1 "true" 0 "false" ;
VAL_ 565 DSPMCA_DrvrStPrfMd6Avl 1 "true" 0 "false" ;
VAL_ 565 DSPMCA_DrvrStPrfMd5Avl 1 "true" 0 "false" ;
VAL_ 565 DSPMCA_DrvrStPrfMd4Avl 1 "true" 0 "false" ;
VAL_ 565 DSPMCA_DrvrStPrfMd3Avl 1 "true" 0 "false" ;
VAL_ 565 DSPMCA_DrvrStPrfMd2Avl 1 "true" 0 "false" ;
VAL_ 565 DSPMCA_DrvrStPrfMd1Avl 1 "true" 0 "false" ;
VAL_ 565 ACCPMCA_ACCPrfMd6Avl 1 "true" 0 "false" ;
VAL_ 565 ACCPMCA_ACCPrfMd5Avl 1 "true" 0 "false" ;
VAL_ 565 ACCPMCA_ACCPrfMd4Avl 1 "true" 0 "false" ;
VAL_ 565 ACCPMCA_ACCPrfMd3Avl 1 "true" 0 "false" ;
VAL_ 565 ACCPMCA_ACCPrfMd2Avl 1 "true" 0 "false" ;
VAL_ 565 ACCPMCA_ACCPrfMd1Avl 1 "true" 0 "false" ;
VAL_ 500 AutoVehMdSelctIntrStat 3 "Mode Request Denied" 2 "Disabled" 1 "Enabled" 0 "No Action" ;
VAL_ 500 EnhDrvMdSwChUseAct 1 "true" 0 "false" ;
VAL_ 500 EnhDrvSelMdSwStat 0 "No Activation" 1 "Increment" 2 "Decrement" 3 "Faulted" ;
VAL_ 500 DrvSelMd8Stat 1 "Active" 0 "Inactive" ;
VAL_ 500 DrvSelMd8ReqDnd 1 "true" 0 "false" ;
VAL_ 500 DrvSelMd7Stat 1 "Active" 0 "Inactive" ;
VAL_ 500 DrvSelMd7ReqDnd 1 "true" 0 "false" ;
VAL_ 500 DrvSelMd6Stat 1 "Active" 0 "Inactive" ;
VAL_ 500 DrvSelMd6ReqDnd 1 "true" 0 "false" ;
VAL_ 500 DrvSelMd5Stat 1 "Active" 0 "Inactive" ;
VAL_ 500 DrvSelMd5ReqDnd 1 "true" 0 "false" ;
VAL_ 500 DrvSelMd4Stat 1 "Active" 0 "Inactive" ;
VAL_ 500 DrvSelMd4ReqDnd 1 "true" 0 "false" ;
VAL_ 500 DrvSelMd3Stat 1 "Active" 0 "Inactive" ;
VAL_ 500 DrvSelMd3ReqDnd 1 "true" 0 "false" ;
VAL_ 500 DrvSelMd2Stat 1 "Active" 0 "Inactive" ;
VAL_ 500 DrvSelMd2ReqDnd 1 "true" 0 "false" ;
VAL_ 500 DSMSS_DrvSelMd0Pn 1 "true" 0 "false" ;
VAL_ 500 DSMSS_DrvSelMd8Pn 1 "true" 0 "false" ;
VAL_ 500 DSMSS_DrvSelMd7Pn 1 "true" 0 "false" ;
VAL_ 500 DSMSS_DrvSelMd6Pn 1 "true" 0 "false" ;
VAL_ 500 DSMSS_DrvSelMd5Pn 1 "true" 0 "false" ;
VAL_ 500 DSMSS_DrvSelMd4Pn 1 "true" 0 "false" ;
VAL_ 500 DSMSS_DrvSelMd3Pn 1 "true" 0 "false" ;
VAL_ 500 DSMSS_DrvSelMd2Pn 1 "true" 0 "false" ;
VAL_ 500 DSMSS_DrvSelMd1Pn 1 "true" 0 "false" ;
VAL_ 500 DSMSS_DrvSelMd8Un 1 "true" 0 "false" ;
VAL_ 500 DSMSS_DrvSelMd7Un 1 "true" 0 "false" ;
VAL_ 500 DSMSS_DrvSelMd6Un 1 "true" 0 "false" ;
VAL_ 500 DSMSS_DrvSelMd5Un 1 "true" 0 "false" ;
VAL_ 500 DSMSS_DrvSelMd4Un 1 "true" 0 "false" ;
VAL_ 500 DSMSS_DrvSelMd3Un 1 "true" 0 "false" ;
VAL_ 500 DSMSS_DrvSelMd2Un 1 "true" 0 "false" ;
VAL_ 500 DSMSS_DrvSelMd1Un 1 "true" 0 "false" ;
VAL_ 500 DrvSelMd1ReqDnd 1 "true" 0 "false" ;
VAL_ 500 DrvSelMd1Stat 1 "Active" 0 "Inactive" ;
VAL_ 407 TransStCrwlMdOvrrd 3 "Unused And Reserved" 2 "Override To Crawl" 1 "Override To Not Crawl" 0 "No Override" ;
VAL_ 407 TEPI_TrnsEngdPrFlwSt 7 "Unused and Reserved4" 6 "Unused and Reserved3" 5 "Unused and Reserved2" 4 "Unused and Reserved1" 3 "Reverse Engaged" 2 "Drive Engaged" ;
VAL_ 407 TransRatioV 1 "Invalid" 0 "Valid" ;
VAL_ 407 TrnsOvrallActTorqRatioV 1 "Invalid" 0 "Valid" ;
VAL_ 407 TARS_TransActRngV 1 "Invalid" 0 "Valid" ;
VAL_ 407 TARS_TransActRngM 1 "Use Data" 0 "Do not Use Data" ;
VAL_ 407 TARS_TransActRng 15 "Unused and Reserved2" 14 "Unused and Reserved1" 13 "Fourth Drive Position" 12 "Between Third and Fourth Drive position" 11 "Third Drive Position" 10 "Between Second and Third Drive position" 9 "Second Drive Position" 8 "Between First and Second Drive position" 7 "First Drive Position" 6 "Between Neutral and First Drive position" 5 "Neutral Position" 4 "Between Reverse and Neutral" 3 "Reverse Position" 2 "Between Park and Reverse" 1 "Park Position" 0 "Unknown Position" ;
VAL_ 979 PltfrmEngSpdCmmndSt 3 "Request Denied" 2 "Lost Arbitration" 1 "Request Honored" 0 "No Request" ;
VAL_ 979 PTABR_PTBrkRqAct 1 "true" 0 "false" ;
VAL_ 979 BrkBstVacV 1 "Invalid" 0 "Valid" ;
VAL_ 979 RegVltCtlEngyRcvryAct 1 "true" 0 "false" ;
VAL_ 979 SpdLmtrSttngTypAct 3 "Reserved" 2 "Auto" 1 "Manual" 0 "Off" ;
VAL_ 979 SetSpdLmtRchd 3 "Reserved" 2 "Low limit reached" 1 "High limit reached" 0 "No limit reached" ;
VAL_ 979 ElvtdIdlCstCrStVal 0 "No Action" 1 "Off" 2 "On" ;
VAL_ 979 ElvtdIdlCstStAvl 1 "true" 0 "false" ;
VAL_ 979 EngManfldAirTempCrtdV 1 "Invalid" 0 "Valid" ;
VAL_ 368 EnvIdRspSt5 0 "No info" 1 "Info valid" 2 "Incorrect immo id" 3 "Environment id request" ;
VAL_ 1187 EngInltCltTmpV 1 "Invalid" 0 "Valid" ;
VAL_ 1187 CbnHtrWrmUpReq 3 "Warm Up Level 3" 2 "Warm Up Level 2" 1 "Warm Up Level 1" 0 "None" ;
VAL_ 1187 VehGrdSnsrBsdV 1 "Invalid" 0 "Valid" ;
VAL_ 1187 CbnHtrWrmUpIO 1 "true" 0 "false" ;
VAL_ 566 RdDCChrgCntctrStat 2 "Closed" 1 "Precharge" 0 "Open" ;
VAL_ 566 RdHVBatHtrCntctrStat 2 "Closed" 1 "Unused and Reserved" 0 "Open" ;
VAL_ 566 RHVBCCS_InvtrCaptrChrgAct 1 "true" 0 "false" ;
VAL_ 566 RHVBCCS_DCChrgrCntCmd 1 "true" 0 "false" ;
VAL_ 566 RHVBCCS_InvtrCntCmd 1 "true" 0 "false" ;
VAL_ 566 RHVBCCS_ACChrgrCntCmd 1 "true" 0 "false" ;
VAL_ 566 RdHVCntctrShdwnCmd 4 "Normal Shutdown" 3 "Emergency Crash Shutdown" 2 "Controlled Shutdown" 1 "Emergency Shutdown" 0 "None" ;
VAL_ 566 ChrgSysShftPrkReq 1 "true" 0 "false" ;
VAL_ 566 HVBatChrgCrdAlrtReq 0 "None" 1 "Pedestrian" 2 "Theft" ;
VAL_ 566 RdHVBatLwParMdReq 1 "true" 0 "false" ;
VAL_ 566 RdHVBtClOVFFTstRq 1 "true" 0 "false" ;
VAL_ 566 ClimCtrlHVDvcShtdwnCmd 1 "true" 0 "false" ;
VAL_ 566 VICMHVEnMgCmEnTrS 0 "Inactive" 1 "Active" ;
VAL_ 566 ChrgSysPrkBrkAnmsBrkReq 1 "true" 0 "false" ;
VAL_ 566 HybVehHiVltSysDisbld_236 1 "true" 0 "false" ;
VAL_ 566 ChrgSysAudblIndRq 7 "Unused and Reserved3" 6 "Unused and Reserved2" 5 "Unused and Reserved1" 4 "Sequence 4" 3 "Sequence 3" 2 "Sequence 2" 1 "Sequence 1" 0 "Inactive" ;
VAL_ 817 RrAxlELSDCplLwResV 1 "Invalid" 0 "Valid" ;
VAL_ 817 RrAxlTmpInhIO 1 "true" 0 "false" 1 "true" 0 "false" ;
VAL_ 817 RrAxlMalfIO 1 "true" 0 "false" 1 "true" 0 "false" ;
SIG_GROUP_ 1271 BatSvrMdCurrTrgr 1 : BSMCT_RawVal BSMCT_Mult;
SIG_GROUP_ 563 SusPerfMdCustAvl 1 : SPMCA_SusPrfMd6Avl SPMCA_SusPrfMd5Avl SPMCA_SusPrfMd4Avl SPMCA_SusPrfMd3Avl SPMCA_SusPrfMd2Avl SPMCA_SusPrfMd1Avl;
SIG_GROUP_ 563 StrPerfMdCustAvl 1 : SPMCA_StrPrfMd6Avl SPMCA_StrPrfMd5Avl SPMCA_StrPrfMd4Avl SPMCA_StrPrfMd3Avl SPMCA_StrPrfMd2Avl SPMCA_StrPrfMd1Avl;
SIG_GROUP_ 563 SndPerfMdCustAvl 1 : SPMCA_SndPrfMd6Avl SPMCA_SndPrfMd5Avl SPMCA_SndPrfMd4Avl SPMCA_SndPrfMd3Avl SPMCA_SndPrfMd2Avl SPMCA_SndPrfMd1Avl;
SIG_GROUP_ 563 DispPerfCustMdAvl 1 : DPMCA_DispPrfMd6Avl DPMCA_DispPrfMd5Avl DPMCA_DispPrfMd4Avl DPMCA_DispPrfMd3Avl DPMCA_DispPrfMd2Avl DPMCA_DispPrfMd1Avl;
SIG_GROUP_ 563 DrvlnPerfMdCustAvl 1 : DPMCA_DrvlPrfMd6Avl DPMCA_DrvlPrfMd5Avl DPMCA_DrvlPrfMd4Avl DPMCA_DrvlPrfMd3Avl DPMCA_DrvlPrfMd2Avl DPMCA_DrvlPrfMd1Avl;
SIG_GROUP_ 384 LKATqOvrDltCmd 1 : LKATODC_TrqVl LKATODC_TrqRqAct;
SIG_GROUP_ 479 EngAutoStrtStpInfo 1 : EASSI_UnsdRsrvd2 EASSI_StlDetd EASSI_TrqDetd EASSI_FuelReqOn EASSI_StrtTyp EASSI_StrtStpSt EASSI_TorqDetdIndet;
SIG_GROUP_ 479 AutoStpInhbtRsnInd 1 : ASIRI_Indication08 ASIRI_Indication07 ASIRI_Indication06 ASIRI_Indication05 ASIRI_Indication04 ASIRI_Indication03 ASIRI_Indication02 ASIRI_Indication01;
SIG_GROUP_ 1219 DslExFldWrngVSpdLmt 1 : DEFWVSL_S3SpdLmt DEFWVSL_S2SpdLmt DEFWVSL_S1SpdLmt;
SIG_GROUP_ 565 PsngStPerfMdCustAvl 1 : PSPMCA_PsngStPrfMd6Avl PSPMCA_PsngStPrfMd5Avl PSPMCA_PsngStPrfMd4Avl PSPMCA_PsngStPrfMd3Avl PSPMCA_PsngStPrfMd2Avl PSPMCA_PsngStPrfMd1Avl;
SIG_GROUP_ 565 DrvStyPerfMdCustAvl 1 : DSPMCA_DrvStyPrfMd7Avl DSPMCA_DrvStyPrfMd6Avl DSPMCA_DrvStyPrfMd5Avl DSPMCA_DrvStyPrfMd4Avl DSPMCA_DrvStyPrfMd3Avl DSPMCA_DrvStyPrfMd2Avl DSPMCA_DrvStyPrfMd1Avl;
SIG_GROUP_ 565 DrvrStPerfMdCustAvl 1 : DSPMCA_DrvrStPrfMd6Avl DSPMCA_DrvrStPrfMd5Avl DSPMCA_DrvrStPrfMd4Avl DSPMCA_DrvrStPrfMd3Avl DSPMCA_DrvrStPrfMd2Avl DSPMCA_DrvrStPrfMd1Avl;
SIG_GROUP_ 565 ACCPerfMdCustAvl 1 : ACCPMCA_ACCPrfMd6Avl ACCPMCA_ACCPrfMd5Avl ACCPMCA_ACCPrfMd4Avl ACCPMCA_ACCPrfMd3Avl ACCPMCA_ACCPrfMd2Avl ACCPMCA_ACCPrfMd1Avl;
SIG_GROUP_ 500 DrvSelMdSelnStat 1 : DSMSS_DrvSelMd0Pn DSMSS_DrvSelMd8Pn DSMSS_DrvSelMd7Pn DSMSS_DrvSelMd6Pn DSMSS_DrvSelMd5Pn DSMSS_DrvSelMd4Pn DSMSS_DrvSelMd3Pn DSMSS_DrvSelMd2Pn DSMSS_DrvSelMd1Pn DSMSS_DrvSelMd8Un DSMSS_DrvSelMd7Un DSMSS_DrvSelMd6Un DSMSS_DrvSelMd5Un DSMSS_DrvSelMd4Un DSMSS_DrvSelMd3Un DSMSS_DrvSelMd2Un DSMSS_DrvSelMd1Un;
SIG_GROUP_ 407 TransActlRngSt 1 : TARS_TransActRngM TARS_TransActRng TARS_TransActRngV;
SIG_GROUP_ 407 TransEngdPrFlwInfo 1 : TEPI_TrnsEngdPrFlwStV TEPI_TrnsEngdPrFlwSt;
SIG_GROUP_ 979 PTAutoBrkReq 1 : PTABR_AccReq PTABR_PTBrkRqAct;
SIG_GROUP_ 566 RdHVBatCntCmdStat 1 : RHVBCCS_InvtrCaptrChrgAct RHVBCCS_DCChrgrCntCmd RHVBCCS_InvtrCntCmd RHVBCCS_ACChrgrCntCmd;
